VERSION "HNNBNNNYNNNNNNNNNNNNNNNNNNNNNNNNNNNNNNNNNN/4/%%%/4/'%**4NNN///"

NS_ :

BS_:

BU_: BAP_Tester CGS Gateway Gateway_PAG HUD Kombi Kombi_LB Kombi_PAG Waehlhebel_SB

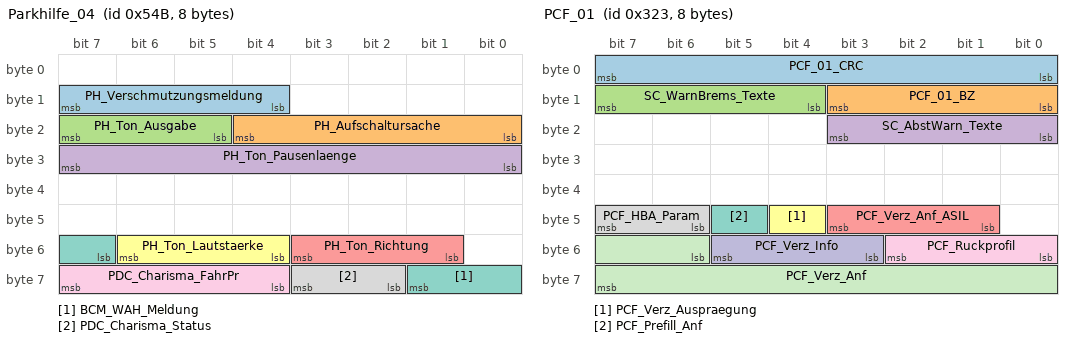
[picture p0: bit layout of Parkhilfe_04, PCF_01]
BO_ 1355 Parkhilfe_04: 8 Gateway
 SG_ PH_Verschmutzungsmeldung : 12|4@1+ (1.0,0.0) [0.0|15] ""  Kombi,Kombi_LB,Kombi_PAG
 SG_ PH_Aufschaltursache : 16|5@1+ (1.0,0.0) [0.0|31] ""  Vector__XXX
 SG_ PH_Ton_Ausgabe : 21|3@1+ (1.0,0.0) [0.0|7] ""  Vector__XXX
 SG_ PH_Ton_Pausenlaenge : 24|8@1+ (1.0,0.0) [0.0|255] ""  Vector__XXX
 SG_ PH_Ton_Richtung : 49|3@1+ (1.0,0.0) [0.0|7] ""  Vector__XXX
 SG_ PH_Ton_Lautstaerke : 52|3@1+ (1.0,0.0) [0.0|7] ""  Vector__XXX
 SG_ BCM_WAH_Meldung : 55|3@1+ (1.0,0.0) [0.0|7] ""  Kombi
 SG_ PDC_Charisma_Status : 58|2@1+ (1.0,0.0) [0.0|3] ""  Vector__XXX
 SG_ PDC_Charisma_FahrPr : 60|4@1+ (1.0,0.0) [0.0|15] ""  Vector__XXX

BO_ 803 PCF_01: 8 Gateway
 SG_ PCF_01_CRC : 0|8@1+ (1,0) [0|255] ""  Vector__XXX
 SG_ PCF_01_BZ : 8|4@1+ (1,0) [0|15] ""  Vector__XXX
 SG_ SC_WarnBrems_Texte : 12|4@1+ (1.0,0.0) [0.0|15] ""  Kombi,Kombi_LB,Kombi_PAG
 SG_ SC_AbstWarn_Texte : 16|4@1+ (1.0,0.0) [0.0|15] ""  Kombi,Kombi_LB,Kombi_PAG
 SG_ PCF_Verz_Anf_ASIL : 41|3@1+ (1.0,0.0) [0.0|7] ""  Vector__XXX
 SG_ PCF_Verz_Auspraegung : 44|1@1+ (1.0,0.0) [0.0|1] ""  Vector__XXX
 SG_ PCF_Prefill_Anf : 45|1@1+ (1.0,0.0) [0.0|1] ""  Vector__XXX
 SG_ PCF_HBA_Param : 46|2@1+ (1.0,0.0) [0.0|3] ""  Vector__XXX
 SG_ PCF_Ruckprofil : 48|3@1+ (1.0,0.0) [0.0|7] ""  Vector__XXX
 SG_ PCF_Verz_Info : 51|3@1+ (1.0,0.0) [0.0|7] ""  Vector__XXX
 SG_ PCF_Verz_Anf : 54|10@1+ (0.024,-20.016) [-20.016|4.536] "Unit_MeterPerSeconSquar"  Vector__XXX

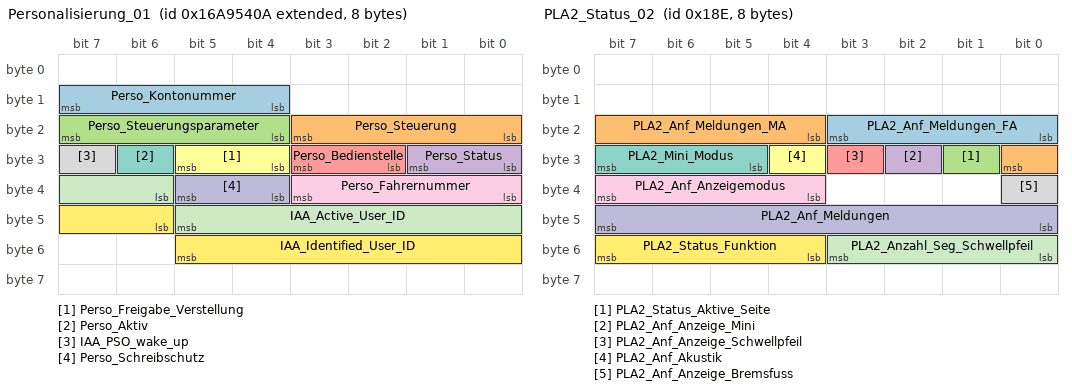
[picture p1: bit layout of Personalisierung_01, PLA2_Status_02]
BO_ 2527679498 Personalisierung_01: 8 Gateway
 SG_ Perso_Kontonummer : 12|4@1+ (1.0,0.0) [0.0|15] ""  HUD,Kombi,Kombi_LB,Kombi_PAG
 SG_ Perso_Steuerung : 16|4@1+ (1.0,0.0) [0.0|15] ""  HUD,Kombi,Kombi_LB,Kombi_PAG
 SG_ Perso_Steuerungsparameter : 20|4@1+ (1.0,0.0) [0.0|15] ""  HUD,Kombi,Kombi_LB,Kombi_PAG
 SG_ Perso_Status : 24|2@1+ (1.0,0.0) [0.0|3] ""  HUD,Kombi,Kombi_LB,Kombi_PAG
 SG_ Perso_Bedienstelle : 26|2@1+ (1.0,0.0) [0.0|3] ""  Vector__XXX
 SG_ Perso_Freigabe_Verstellung : 28|2@1+ (1.0,0.0) [0.0|3] ""  Vector__XXX
 SG_ Perso_Aktiv : 30|1@1+ (1.0,0.0) [0.0|1] ""  Vector__XXX
 SG_ IAA_PSO_wake_up : 31|1@1+ (1.0,0.0) [0.0|1] ""  Vector__XXX
 SG_ Perso_Fahrernummer : 32|4@1+ (1.0,0.0) [0.0|15] ""  Vector__XXX
 SG_ Perso_Schreibschutz : 36|2@1+ (1.0,0.0) [0.0|3] ""  Vector__XXX
 SG_ IAA_Active_User_ID : 38|8@1+ (1,0) [0|255] "Unit_None"  Kombi_PAG
 SG_ IAA_Identified_User_ID : 46|8@1+ (1,0) [0|255] "Unit_None"  Kombi_PAG

BO_ 398 PLA2_Status_02: 8 Gateway
 SG_ PLA2_Anf_Meldungen_FA : 16|4@1+ (1.0,0.0) [0.0|15] ""  Kombi,Kombi_LB,Kombi_PAG
 SG_ PLA2_Anf_Meldungen_MA : 20|5@1+ (1.0,0.0) [0.0|31] ""  Kombi,Kombi_LB,Kombi_PAG
 SG_ PLA2_Status_Aktive_Seite : 25|1@1+ (1.0,0.0) [0.0|1] ""  Kombi,Kombi_LB,Kombi_PAG
 SG_ PLA2_Anf_Anzeige_Mini : 26|1@1+ (1.0,0.0) [0.0|1] ""  Kombi,Kombi_LB,Kombi_PAG
 SG_ PLA2_Anf_Anzeige_Schwellpfeil : 27|1@1+ (1.0,0.0) [0.0|1] ""  Kombi,Kombi_LB,Kombi_PAG
 SG_ PLA2_Anf_Akustik : 28|1@1+ (1.0,0.0) [0.0|1] ""  Kombi,Kombi_LB,Kombi_PAG
 SG_ PLA2_Mini_Modus : 29|3@1+ (1.0,0.0) [0.0|7] ""  Kombi,Kombi_LB,Kombi_PAG
 SG_ PLA2_Anf_Anzeige_Bremsfuss : 32|1@1+ (1.0,0.0) [0.0|1] ""  Kombi,Kombi_LB,Kombi_PAG
 SG_ PLA2_Anf_Anzeigemodus : 36|4@1+ (1.0,0.0) [0.0|15] ""  Kombi,Kombi_LB,Kombi_PAG
 SG_ PLA2_Anf_Meldungen : 40|8@1+ (1.0,0.0) [0.0|255] ""  Kombi,Kombi_LB,Kombi_PAG
 SG_ PLA2_Anzahl_Seg_Schwellpfeil : 48|4@1+ (1,0) [0|15] ""  Kombi,Kombi_LB,Kombi_PAG
 SG_ PLA2_Status_Funktion : 52|4@1+ (1.0,0.0) [0.0|15] ""  Kombi,Kombi_LB,Kombi_PAG

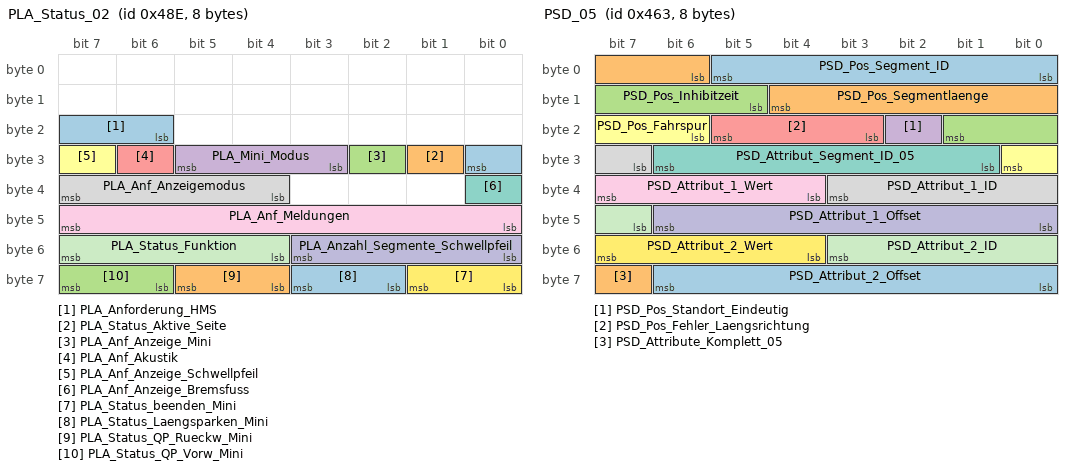
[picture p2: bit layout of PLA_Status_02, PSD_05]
BO_ 1166 PLA_Status_02: 8 Gateway
 SG_ PLA_Anforderung_HMS : 22|3@1+ (1.0,0.0) [0.0|7] ""  Vector__XXX
 SG_ PLA_Status_Aktive_Seite : 25|1@1+ (1.0,0.0) [0.0|1] ""  Kombi,Kombi_LB,Kombi_PAG
 SG_ PLA_Anf_Anzeige_Mini : 26|1@1+ (1.0,0.0) [0.0|1] ""  Kombi,Kombi_LB,Kombi_PAG
 SG_ PLA_Mini_Modus : 27|3@1+ (1.0,0.0) [0.0|7] ""  Kombi,Kombi_LB,Kombi_PAG
 SG_ PLA_Anf_Akustik : 30|1@1+ (1.0,0.0) [0.0|1] ""  Kombi,Kombi_LB,Kombi_PAG
 SG_ PLA_Anf_Anzeige_Schwellpfeil : 31|1@1+ (1.0,0.0) [0.0|1] ""  Kombi,Kombi_LB,Kombi_PAG
 SG_ PLA_Anf_Anzeige_Bremsfuss : 32|1@1+ (1.0,0.0) [0.0|1] ""  Kombi,Kombi_LB,Kombi_PAG
 SG_ PLA_Anf_Anzeigemodus : 36|4@1+ (1.0,0.0) [0.0|15] ""  Kombi,Kombi_LB,Kombi_PAG
 SG_ PLA_Anf_Meldungen : 40|8@1+ (1.0,0.0) [0.0|255] ""  Kombi,Kombi_LB,Kombi_PAG
 SG_ PLA_Anzahl_Segmente_Schwellpfeil : 48|4@1+ (1,0) [0|15] "Unit_None"  Kombi,Kombi_LB,Kombi_PAG
 SG_ PLA_Status_Funktion : 52|4@1+ (1.0,0.0) [0.0|15] ""  Kombi,Kombi_LB,Kombi_PAG
 SG_ PLA_Status_beenden_Mini : 56|2@1+ (1.0,0.0) [0.0|3] ""  Vector__XXX
 SG_ PLA_Status_Laengsparken_Mini : 58|2@1+ (1.0,0.0) [0.0|3] ""  Vector__XXX
 SG_ PLA_Status_QP_Rueckw_Mini : 60|2@1+ (1.0,0.0) [0.0|3] ""  Vector__XXX
 SG_ PLA_Status_QP_Vorw_Mini : 62|2@1+ (1.0,0.0) [0.0|3] ""  Vector__XXX

BO_ 319 PreCrash_02: 8 Gateway
 SG_ PreCrash_02_CRC : 0|8@1+ (1,0) [0|255] ""  Vector__XXX
 SG_ PreCrash_02_BZ : 8|4@1+ (1,0) [0|15] ""  Vector__XXX
 SG_ PreCrash_Charisma_FahrPr : 12|4@1+ (1.0,0.0) [0.0|15] ""  Vector__XXX
 SG_ PreCrash_Charisma_Status : 16|2@1+ (1.0,0.0) [0.0|3] ""  Vector__XXX
 SG_ PreCrash_Schiebedach_schliessen : 18|1@1+ (1.0,0.0) [0.0|1] ""  Vector__XXX
 SG_ PreCrash_Fenster_schliessen : 19|1@1+ (1.0,0.0) [0.0|1] ""  Vector__XXX
 SG_ PreCrash_Blinken : 20|3@1+ (1.0,0.0) [0.0|7] ""  Vector__XXX
 SG_ SC_PreSense_FCWP : 23|1@1+ (1.0,0.0) [0.0|1] ""  Vector__XXX
 SG_ PreCrash_Tueren_Verriegeln : 24|1@1+ (1.0,0.0) [0.0|1] ""  Vector__XXX
 SG_ PreCrash_Anforderung_AFR : 26|3@1+ (1.0,0.0) [0.0|7] ""  Vector__XXX
 SG_ SC_PreCrash_LED : 29|2@1+ (1.0,0.0) [0.0|3] ""  HUD,Kombi,Kombi_LB,Kombi_PAG
 SG_ PreCrash_FS_Pneumatik_ansteuern : 31|1@1+ (1.0,0.0) [0.0|1] ""  Vector__XXX
 SG_ PreCrash_BFS_Pneumatik_ansteuern : 32|1@1+ (1.0,0.0) [0.0|1] ""  Vector__XXX
 SG_ PreCrash_Fo_Pneumatik_ansteuern : 33|1@1+ (1.0,0.0) [0.0|1] ""  Vector__XXX
 SG_ PreCrash_FS_Sitzlehne_verfahren : 34|3@1+ (1.0,0.0) [0.0|7] ""  Vector__XXX
 SG_ PreCrash_BFS_Sitzlehne_verfahren : 37|3@1+ (1.0,0.0) [0.0|7] ""  Vector__XXX
 SG_ PreCrash_Fo_Sitzlehne_verfahren : 40|3@1+ (1.0,0.0) [0.0|7] ""  Vector__XXX
 SG_ PreCrash_FS_KSV_verfahren : 43|4@1+ (1.0,0.0) [0.0|15] ""  Vector__XXX
 SG_ PreCrash_BFS_KSV_verfahren : 47|4@1+ (1.0,0.0) [0.0|15] ""  Vector__XXX
 SG_ PreCrash_Fo_KSV_verfahren : 51|4@1+ (1.0,0.0) [0.0|15] ""  Vector__XXX
 SG_ SC_PreCrash_Warnung : 56|4@1+ (1.0,0.0) [0.0|15] ""  HUD,Kombi,Kombi_LB,Kombi_PAG
 SG_ SC_PreCrash_Texte : 60|4@1+ (1.0,0.0) [0.0|15] ""  Kombi,Kombi_LB,Kombi_PAG

BO_ 1122 PSD_04: 8 Gateway
 SG_ PSD_Segment_ID : 0|6@1+ (1,0) [2|63] ""  Kombi,Kombi_LB,Kombi_PAG
 SG_ PSD_Vorgaenger_Segment_ID : 6|6@1+ (1,0) [2|63] ""  Kombi,Kombi_LB,Kombi_PAG
 SG_ PSD_Segmentlaenge : 12|7@1+ (2,0) [0|254] "Unit_Meter"  Kombi,Kombi_LB,Kombi_PAG
 SG_ PSD_Strassenkategorie : 19|3@1+ (1.0,0.0) [0.0|7] ""  Kombi,Kombi_LB,Kombi_PAG
 SG_ PSD_Endkruemmung : 22|8@1+ (1,0) [0|254] "Unit_None"  Kombi,Kombi_LB,Kombi_PAG
 SG_ PSD_Endkruemmung_Vorz : 30|1@1+ (1.0,0.0) [0.0|1] ""  Kombi,Kombi_LB,Kombi_PAG
 SG_ PSD_Idenditaets_ID : 31|6@1+ (1,0) [2|63] ""  Kombi,Kombi_LB,Kombi_PAG
 SG_ PSD_ADAS_Qualitaet : 37|1@1+ (1.0,0.0) [0.0|1] ""  Kombi,Kombi_LB,Kombi_PAG
 SG_ PSD_wahrscheinlichster_Pfad : 38|1@1+ (1.0,0.0) [0.0|1] ""  Kombi,Kombi_LB,Kombi_PAG
 SG_ PSD_Geradester_Pfad : 39|1@1+ (1.0,0.0) [0.0|1] ""  Kombi,Kombi_LB,Kombi_PAG
 SG_ PSD_Fahrspuren_Anzahl : 40|3@1+ (1.0,0.0) [0.0|7] ""  Kombi,Kombi_LB,Kombi_PAG
 SG_ PSD_Bebauung : 43|1@1+ (1.0,0.0) [0.0|1] ""  Kombi,Kombi_LB,Kombi_PAG
 SG_ PSD_Segment_Komplett : 44|1@1+ (1.0,0.0) [0.0|1] ""  Kombi,Kombi_LB,Kombi_PAG
 SG_ PSD_Rampe : 45|2@1+ (1.0,0.0) [0.0|3] ""  Kombi,Kombi_LB,Kombi_PAG
 SG_ PSD_Anfangskruemmung : 47|8@1+ (1,0) [0|254] ""  Kombi,Kombi_LB,Kombi_PAG
 SG_ PSD_Anfangskruemmung_Vorz : 55|1@1+ (1.0,0.0) [0.0|1] ""  Kombi,Kombi_LB,Kombi_PAG
 SG_ PSD_Abzweigerichtung : 56|1@1+ (1.0,0.0) [0.0|1] ""  Kombi,Kombi_LB,Kombi_PAG
 SG_ PSD_Abzweigewinkel : 57|7@1+ (1.417323,0) [0.000000|180.000021] ""  Kombi,Kombi_LB,Kombi_PAG

BO_ 1123 PSD_05: 8 Gateway
 SG_ PSD_Pos_Segment_ID : 0|6@1+ (1,0) [2|63] ""  Kombi,Kombi_LB,Kombi_PAG
 SG_ PSD_Pos_Segmentlaenge : 6|7@1+ (2,0) [0|254] "Unit_Meter"  Kombi,Kombi_LB,Kombi_PAG
 SG_ PSD_Pos_Inhibitzeit : 13|5@1+ (10,0) [0|310] "Unit_MilliSecon"  Kombi,Kombi_LB,Kombi_PAG
 SG_ PSD_Pos_Standort_Eindeutig : 18|1@1+ (1.0,0.0) [0.0|1] ""  Kombi,Kombi_LB,Kombi_PAG
 SG_ PSD_Pos_Fehler_Laengsrichtung : 19|3@1+ (1.0,0.0) [0.0|7] ""  Kombi,Kombi_LB,Kombi_PAG
 SG_ PSD_Pos_Fahrspur : 22|3@1+ (1.0,0.0) [0.0|7] ""  Kombi,Kombi_LB,Kombi_PAG
 SG_ PSD_Attribut_Segment_ID_05 : 25|6@1+ (1,0) [2|63] ""  Kombi,Kombi_LB,Kombi_PAG
 SG_ PSD_Attribut_1_ID : 31|5@1+ (1,0) [1|31] ""  Kombi,Kombi_LB,Kombi_PAG
 SG_ PSD_Attribut_1_Wert : 36|4@1+ (1.0,0.0) [0.0|15] ""  Kombi,Kombi_LB,Kombi_PAG
 SG_ PSD_Attribut_1_Offset : 40|7@1+ (2,0) [0|254] "Unit_Meter"  Kombi,Kombi_LB,Kombi_PAG
 SG_ PSD_Attribut_2_ID : 47|5@1+ (1,0) [1|31] ""  Kombi,Kombi_LB,Kombi_PAG
 SG_ PSD_Attribut_2_Wert : 52|4@1+ (1.0,0.0) [0.0|15] ""  Kombi,Kombi_LB,Kombi_PAG
 SG_ PSD_Attribut_2_Offset : 56|7@1+ (2,0) [0|254] "Unit_Meter"  Kombi,Kombi_LB,Kombi_PAG
 SG_ PSD_Attribute_Komplett_05 : 63|1@1+ (1.0,0.0) [0.0|1] ""  Kombi,Kombi_LB,Kombi_PAG

BO_ 1124 PSD_06: 8 Gateway
 SG_ PSD_06_Mux M  : 0|3@1+ (1.0,0.0) [0.0|7] ""  HUD,Kombi,Kombi_LB,Kombi_PAG
 SG_ PSD_Sys_Segment_ID m0  : 3|6@1+ (1,0) [2|63] ""  HUD,Kombi,Kombi_LB,Kombi_PAG
 SG_ PSD_Attribut_Segment_ID m1  : 3|6@1+ (1,0) [2|63] ""  Kombi,Kombi_LB,Kombi_PAG
 SG_ PSD_Ges_Segment_ID m2  : 3|6@1+ (1,0) [2|63] ""  Kombi,Kombi_LB,Kombi_PAG
 SG_ PSD_Baum_Laenge_VZ m3  : 3|1@1+ (1.0,0.0) [0.0|1] ""  Kombi,Kombi_LB,Kombi_PAG
 SG_ PSD_Steigung_1_Segment_ID m4  : 3|6@1+ (1,0) [2|63] ""  Kombi,Kombi_LB,Kombi_PAG
 SG_ PSD_Baum_Laenge m3  : 4|25@1+ (0.00001,0) [0.00000|180.00000] "Unit_DegreOfArc"  Kombi,Kombi_LB,Kombi_PAG
 SG_ PSD_Sys_Laendercode m0  : 9|8@1+ (1.0,0.0) [0.0|255] ""  HUD,Kombi,Kombi_LB,Kombi_PAG
 SG_ PSD_Attribut_3_ID m1  : 9|5@1+ (1,0) [1|31] ""  Kombi,Kombi_LB,Kombi_PAG
 SG_ PSD_Ges_Offset m2  : 9|7@1+ (2,0) [0|254] "Unit_Meter"  Kombi,Kombi_LB,Kombi_PAG
 SG_ PSD_Steigung_1_A_Steigung m4  : 9|7@1+ (0.12,0) [0.00|15.00] "Unit_PerCent"  Kombi,Kombi_LB,Kombi_PAG
 SG_ PSD_Attribut_3_Offset m1  : 14|7@1+ (2,0) [0|254] "Unit_Meter"  Kombi,Kombi_LB,Kombi_PAG
 SG_ PSD_Ges_Geschwindigkeit m2  : 16|5@1+ (1.0,0.0) [0.0|31] ""  Kombi,Kombi_LB,Kombi_PAG
 SG_ PSD_Steigung_1_A_Vorz m4  : 16|1@1+ (1.0,0.0) [0.0|1] ""  Kombi,Kombi_LB,Kombi_PAG
 SG_ PSD_Sys_Geschwindigkeit_Einheit m0  : 17|1@1+ (1.0,0.0) [0.0|1] ""  HUD,Kombi,Kombi_LB,Kombi_PAG
 SG_ PSD_Steigung_1_A_Offset m4  : 17|7@1+ (2,0) [0|254] "Unit_Meter"  Kombi,Kombi_LB,Kombi_PAG
 SG_ PSD_Sys_Verkehrsrichtung m0  : 18|1@1+ (1.0,0.0) [0.0|1] ""  HUD,Kombi,Kombi_LB,Kombi_PAG
 SG_ PSD_Sys_Geometrieguete m0  : 19|2@1+ (1.0,0.0) [0.0|3] ""  HUD,Kombi,Kombi_LB,Kombi_PAG
 SG_ PSD_Sys_Mapmatchingguete m0  : 21|2@1+ (1.0,0.0) [0.0|3] ""  HUD,Kombi,Kombi_LB,Kombi_PAG
 SG_ PSD_Attribut_3_Wert m1  : 21|4@1+ (1.0,0.0) [0.0|15] ""  Kombi,Kombi_LB,Kombi_PAG
 SG_ PSD_Ges_Typ m2  : 21|2@1+ (1.0,0.0) [0.0|3] ""  Kombi,Kombi_LB,Kombi_PAG
 SG_ PSD_Sys_Alter_Karte m0  : 23|3@1+ (1.0,0.0) [0.0|7] ""  HUD,Kombi,Kombi_LB,Kombi_PAG
 SG_ PSD_Ges_Spur_Geschw_Begrenzung m2  : 23|6@1+ (1.0,0.0) [0.0|63] ""  Kombi,Kombi_LB,Kombi_PAG
 SG_ PSD_Steigung_1_B_Steigung m4  : 24|7@1+ (0.12,0) [0.00|15.00] "Unit_PerCent"  Kombi,Kombi_LB,Kombi_PAG
 SG_ PSD_Attribut_4_ID m1  : 25|5@1+ (1,0) [1|31] ""  Kombi,Kombi_LB,Kombi_PAG
 SG_ PSD_Sys_Zielfuehrung m0  : 26|1@1+ (1.0,0.0) [0.0|1] ""  HUD,Kombi,Kombi_LB,Kombi_PAG
 SG_ PSD_Sys_US_State m0  : 27|6@1+ (1.0,0.0) [0.0|63] ""  HUD,Kombi,Kombi_LB,Kombi_PAG
 SG_ PSD_Ges_Geschwindigkeit_Gespann m2  : 29|2@1+ (1.0,0.0) [0.0|3] ""  Kombi,Kombi_LB,Kombi_PAG
 SG_ PSD_Baum_Breite_VZ m3  : 29|1@1+ (1.0,0.0) [0.0|1] ""  Kombi,Kombi_LB,Kombi_PAG
 SG_ PSD_Attribut_4_Wert m1  : 30|4@1+ (1,0) [0|15] ""  Kombi,Kombi_LB,Kombi_PAG
 SG_ PSD_Baum_Breite m3  : 30|24@1+ (0.00001,0) [0.00000|90.00000] "Unit_DegreOfArc"  Kombi,Kombi_LB,Kombi_PAG
 SG_ PSD_Ges_Geschwindigkeit_Witter m2  : 31|2@1+ (1.0,0.0) [0.0|3] ""  Kombi,Kombi_LB,Kombi_PAG
 SG_ PSD_Steigung_1_B_Vorz m4  : 31|1@1+ (1.0,0.0) [0.0|1] ""  Kombi,Kombi_LB,Kombi_PAG
 SG_ PSD_Steigung_1_B_Offset m4  : 32|7@1+ (2,0) [0|254] "Unit_Meter"  Kombi,Kombi_LB,Kombi_PAG
 SG_ PSD_Sys_Quali_Geometrien m0  : 33|3@1+ (1,0) [0|7] "Unit_None"  HUD
 SG_ PSD_Ges_Geschwindigkeit_Tag_Anf m2  : 33|3@1+ (1.0,0.0) [0.0|7] ""  Kombi,Kombi_LB,Kombi_PAG
 SG_ PSD_Attribut_4_Offset m1  : 34|7@1+ (2,0) [0|254] "Unit_Meter"  Kombi,Kombi_LB,Kombi_PAG
 SG_ PSD_Sys_Quali_Ortsinfo m0  : 36|2@1+ (1,0) [0|3] "Unit_None"  HUD
 SG_ PSD_Ges_Geschwindigkeit_Tag_Ende m2  : 36|3@1+ (1.0,0.0) [0.0|7] ""  Kombi,Kombi_LB,Kombi_PAG
 SG_ PSD_Sys_Quali_verfuegbar m0  : 38|1@1+ (1.0,0.0) [0.0|1] ""  HUD
 SG_ PSD_Sys_Zielfuehrung_geaendert m0  : 39|1@1+ (1.0,0.0) [0.0|1] ""  HUD
 SG_ PSD_Ges_Geschwindigkeit_Std_Anf m2  : 39|5@1+ (1,0) [0|24] "Unit_Hours"  Kombi,Kombi_LB,Kombi_PAG
 SG_ PSD_Steigung_1_Attribute_kompl m4  : 39|1@1+ (1.0,0.0) [0.0|1] ""  Kombi,Kombi_LB,Kombi_PAG
 SG_ PSD_Sys_Geometrieguete_erweitert m0  : 40|8@1+ (1.0,0.0) [0.0|255] ""  HUD
 SG_ PSD_Steigung_2_Segment_ID m4  : 40|6@1+ (1,0) [2|63] ""  Kombi,Kombi_LB,Kombi_PAG
 SG_ PSD_Attribut_5_ID m1  : 41|5@1+ (1,0) [1|31] ""  Kombi,Kombi_LB,Kombi_PAG
 SG_ PSD_Ges_Geschwindigkeit_Std_Ende m2  : 44|5@1+ (1,0) [0|24] "Unit_Hours"  Kombi,Kombi_LB,Kombi_PAG
 SG_ PSD_Attribut_5_Offset m1  : 46|7@1+ (2,0) [0|254] "Unit_Meter"  Kombi,Kombi_LB,Kombi_PAG
 SG_ PSD_Steigung_2_Steigung m4  : 46|7@1+ (0.12,0) [0.00|15.00] "Unit_PerCent"  Kombi,Kombi_LB,Kombi_PAG
 SG_ PSD_Sys_Quali_sonstige_Attribute m0  : 48|3@1+ (1,0) [0|7] "Unit_None"  HUD
 SG_ PSD_Ges_Ueberholverbot m2  : 49|2@1+ (1.0,0.0) [0.0|3] ""  Kombi,Kombi_LB,Kombi_PAG
 SG_ PSD_Sys_Quali_Steigungen m0  : 51|3@1+ (1,0) [0|7] ""  HUD
 SG_ PSD_Ges_Wechselverkehrszeichen m2  : 51|3@1+ (1.0,0.0) [0.0|7] ""  Kombi,Kombi_LB,Kombi_PAG
 SG_ PSD_Attribut_5_Wert m1  : 53|4@1+ (1,0) [0|15] ""  Kombi,Kombi_LB,Kombi_PAG
 SG_ PSD_Steigung_2_Vorz m4  : 53|1@1+ (1.0,0.0) [0.0|1] ""  Kombi,Kombi_LB,Kombi_PAG
 SG_ PSD_Sys_Quali_Strassenkennz m0  : 54|3@1+ (1,0) [0|7] "Unit_None"  HUD
 SG_ PSD_Wechselverkehrszeichen_Typ m2  : 54|2@1+ (1.0,0.0) [0.0|3] ""  Kombi,Kombi_LB,Kombi_PAG
 SG_ PSD_Baum_Ausrichtung m3  : 54|10@1+ (0.3515625,0) [0E-7|359.6484375] "Unit_DegreOfArc"  Kombi,Kombi_LB,Kombi_PAG
 SG_ PSD_Steigung_2_Offset m4  : 54|7@1+ (2,0) [0|254] "Unit_Meter"  Kombi,Kombi_LB,Kombi_PAG
 SG_ PSD_Ges_Gesetzlich_Kategorie m2  : 56|3@1+ (1.0,0.0) [0.0|7] ""  Kombi,Kombi_LB,Kombi_PAG
 SG_ PSD_Sys_Quali_Tempolimits m0  : 57|3@1+ (1,0) [0|7] "Unit_None"  HUD
 SG_ PSD_Attribute_Komplett_06 m1  : 57|1@1+ (1.0,0.0) [0.0|1] ""  Kombi,Kombi_LB,Kombi_PAG
 SG_ PSD_Ges_Gesetzlich_Zusatz m2  : 59|2@1+ (1.0,0.0) [0.0|3] ""  Kombi,Kombi_LB,Kombi_PAG
 SG_ PSD_Sys_Quali_Vorfahrtsregelung m0  : 60|3@1+ (1,0) [0|7] "Unit_None"  HUD
 SG_ PSD_Ges_Verkehrszeichen_Quelle m2  : 61|2@1+ (1.0,0.0) [0.0|3] ""  Kombi,Kombi_LB,Kombi_PAG
 SG_ PSD_Steigung_2_Attribute_kompl m4  : 61|1@1+ (1.0,0.0) [0.0|1] ""  Kombi,Kombi_LB,Kombi_PAG
 SG_ PSD_Ges_Attribute_Komplett m2  : 63|1@1+ (1.0,0.0) [0.0|1] ""  Kombi,Kombi_LB,Kombi_PAG

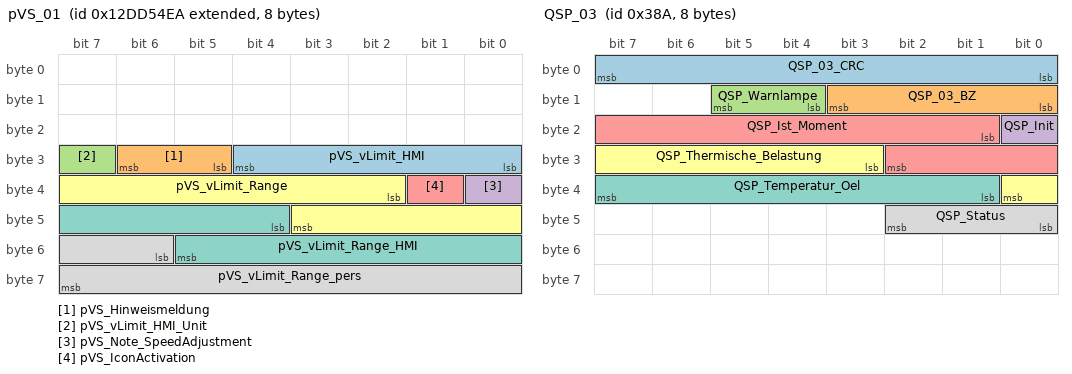
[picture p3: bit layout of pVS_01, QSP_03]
BO_ 2463978730 pVS_01: 8 Gateway_PAG
 SG_ pVS_vLimit_HMI : 24|5@1+ (5,35) [35|180] ""  HUD,Kombi_PAG
 SG_ pVS_Hinweismeldung : 29|2@1+ (1.0,0.0) [0.0|3] ""  HUD,Kombi_PAG
 SG_ pVS_vLimit_HMI_Unit : 31|1@1+ (1.0,0.0) [0.0|1] ""  HUD,Kombi_PAG
 SG_ pVS_Note_SpeedAdjustment : 32|1@1+ (1.0,0.0) [0.0|1] ""  Kombi_PAG
 SG_ pVS_IconActivation : 33|1@1+ (1.0,0.0) [0.0|1] ""  HUD,Kombi_PAG
 SG_ pVS_vLimit_Range : 34|10@1+ (0.32,0) [0.00|326.40] "Unit_KiloMeterPerHour"  Vector__XXX
 SG_ pVS_vLimit_Range_HMI : 44|10@1+ (0.32,0) [0.00|326.40] "Unit_KiloMeterPerHour"  Vector__XXX
 SG_ pVS_vLimit_Range_pers : 54|10@1+ (0.32,0) [0.00|326.40] "Unit_KiloMeterPerHour"  Vector__XXX

BO_ 906 QSP_03: 8 Gateway
 SG_ QSP_03_CRC : 0|8@1+ (1,0) [0|255] ""  Vector__XXX
 SG_ QSP_03_BZ : 8|4@1+ (1,0) [0|15] ""  Vector__XXX
 SG_ QSP_Warnlampe : 12|2@1+ (1.0,0.0) [0.0|3] ""  Kombi,Kombi_PAG
 SG_ QSP_Init : 16|1@1+ (1.0,0.0) [0.0|1] ""  Vector__XXX
 SG_ QSP_Ist_Moment : 17|10@1+ (3,-1533) [-1533|1533] "Unit_NewtoMeter"  Vector__XXX
 SG_ QSP_Thermische_Belastung : 27|6@1+ (2,0) [0|100] "Unit_PerCent"  Vector__XXX
 SG_ QSP_Temperatur_Oel : 33|7@1+ (2,-40) [-40|210] "Unit_DegreCelsi"  Vector__XXX
 SG_ QSP_Status : 40|3@1+ (1.0,0.0) [0.0|7] ""  Vector__XXX

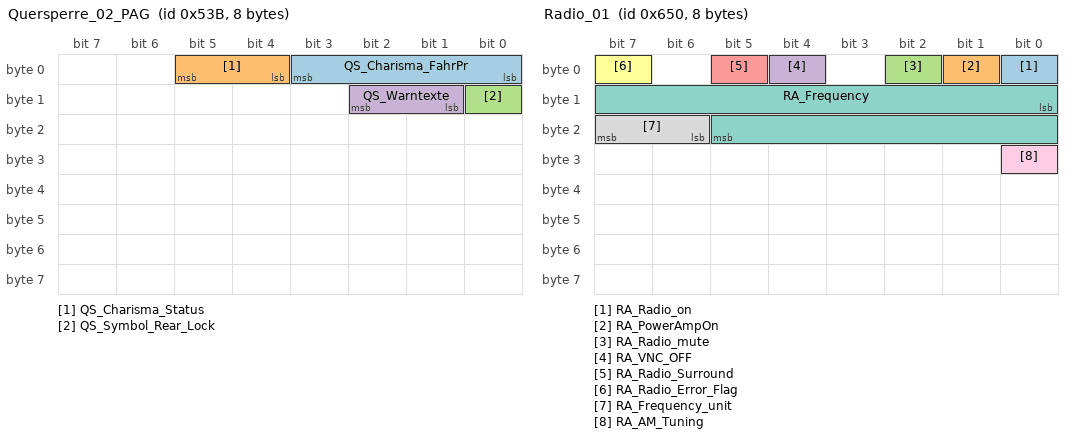
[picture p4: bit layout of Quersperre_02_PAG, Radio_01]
BO_ 1339 Quersperre_02_PAG: 8 Gateway
 SG_ QS_Charisma_FahrPr : 0|4@1+ (1.0,0.0) [0.0|15] ""  Vector__XXX
 SG_ QS_Charisma_Status : 4|2@1+ (1.0,0.0) [0.0|3] ""  Vector__XXX
 SG_ QS_Symbol_Rear_Lock : 8|1@1+ (1.0,0.0) [0.0|1] ""  Vector__XXX
 SG_ QS_Warntexte : 9|2@1+ (1.0,0.0) [0.0|3] ""  Kombi,Kombi_PAG

BO_ 1616 Radio_01: 8 Gateway
 SG_ RA_Radio_on : 0|1@1+ (1,0) [0|1] ""  Vector__XXX
 SG_ RA_PowerAmpOn : 1|1@1+ (1,0) [0|1] ""  Vector__XXX
 SG_ RA_Radio_mute : 2|1@1+ (1,0) [0|1] ""  Vector__XXX
 SG_ RA_VNC_OFF : 4|1@1+ (1,0) [0|1] ""  Vector__XXX
 SG_ RA_Radio_Surround : 5|1@1+ (1,0) [0|1] ""  Vector__XXX
 SG_ RA_Radio_Error_Flag : 7|1@1+ (1.0,0.0) [0.0|1] ""  Vector__XXX
 SG_ RA_Frequency : 8|14@1+ (1,0) [0|16383] "Unit_None"  Kombi
 SG_ RA_Frequency_unit : 22|2@1+ (1.0,0.0) [0.0|3] ""  Kombi,Kombi_LB
 SG_ RA_AM_Tuning : 24|1@1+ (1.0,0.0) [0.0|1] ""  Kombi,Kombi_LB

BO_ 1529 RDK_02: 8 Gateway
 SG_ RDK_FMVSS138_Lampe : 12|1@1+ (1.0,0.0) [0.0|1] ""  Kombi,Kombi_LB,Kombi_PAG
 SG_ RDK_FMVSS138_MIL : 13|1@1+ (1.0,0.0) [0.0|1] ""  Kombi,Kombi_LB,Kombi_PAG
 SG_ RDK_Kalibrierung : 14|1@1+ (1.0,0.0) [0.0|1] ""  Vector__XXX
 SG_ RDK_Reifendruck_Lampe : 15|1@1+ (1.0,0.0) [0.0|1] ""  Kombi,Kombi_LB
 SG_ RDK_Warnungen_02 : 16|5@1+ (1.0,0.0) [0.0|31] ""  Kombi,Kombi_LB,Kombi_PAG
 SG_ RDK_angelernt : 22|1@1+ (1.0,0.0) [0.0|1] ""  Kombi_PAG
 SG_ RDK_Reifentemperatur_Lampe : 23|1@1+ (1.0,0.0) [0.0|1] ""  Kombi,Kombi_LB
 SG_ RDK_RS_aktiv : 24|1@1+ (1.0,0.0) [0.0|1] ""  Kombi_PAG
 SG_ RDK_Text_7 : 25|1@1+ (1.0,0.0) [0.0|1] ""  Kombi_PAG
 SG_ RDK_W_1_Reifen_HL : 56|1@1+ (1.0,0.0) [0.0|1] ""  Kombi,Kombi_LB,Kombi_PAG
 SG_ RDK_W_1_Reifen_HR : 57|1@1+ (1.0,0.0) [0.0|1] ""  Kombi,Kombi_LB,Kombi_PAG
 SG_ RDK_W_1_Reifen_VL : 58|1@1+ (1.0,0.0) [0.0|1] ""  Kombi,Kombi_LB,Kombi_PAG
 SG_ RDK_W_1_Reifen_VR : 59|1@1+ (1.0,0.0) [0.0|1] ""  Kombi,Kombi_LB,Kombi_PAG
 SG_ RDK_W_2_Reifen_HL : 60|1@1+ (1.0,0.0) [0.0|1] ""  Kombi,Kombi_LB,Kombi_PAG
 SG_ RDK_W_2_Reifen_HR : 61|1@1+ (1.0,0.0) [0.0|1] ""  Kombi,Kombi_LB,Kombi_PAG
 SG_ RDK_W_2_Reifen_VL : 62|1@1+ (1.0,0.0) [0.0|1] ""  Kombi,Kombi_LB,Kombi_PAG
 SG_ RDK_W_2_Reifen_VR : 63|1@1+ (1.0,0.0) [0.0|1] ""  Kombi,Kombi_LB,Kombi_PAG

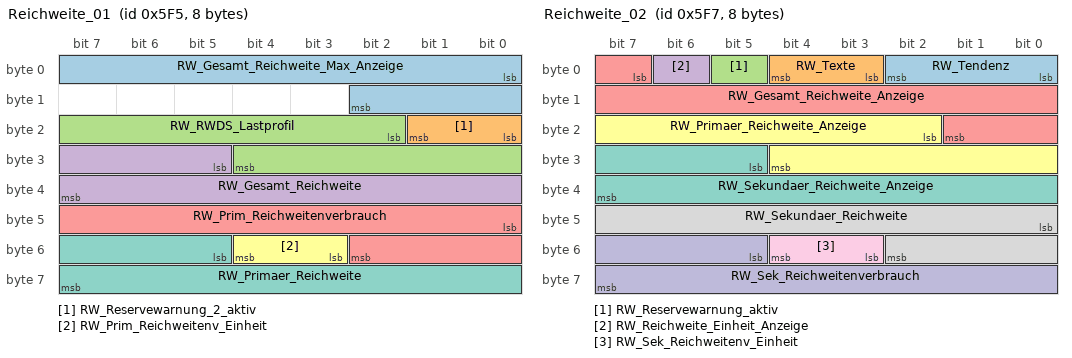
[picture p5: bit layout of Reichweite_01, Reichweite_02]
BO_ 1525 Reichweite_01: 8 Gateway
 SG_ RW_Gesamt_Reichweite_Max_Anzeige : 0|11@1+ (1,0) [0|2044] "Unit_None"  Kombi,Kombi_LB,Kombi_PAG
 SG_ RW_Reservewarnung_2_aktiv : 16|2@1+ (1.0,0.0) [0.0|3] ""  HUD,Kombi,Kombi_LB
 SG_ RW_RWDS_Lastprofil : 18|11@1+ (1,0) [0|2045] "Unit_Amper"  Vector__XXX
 SG_ RW_Gesamt_Reichweite : 29|11@1+ (1,0) [0|2044] "Unit_KiloMeter"  Kombi,Kombi_LB,Kombi_PAG
 SG_ RW_Prim_Reichweitenverbrauch : 40|11@1+ (0.1,0) [0.0|204.4] "Unit_None"  Kombi,Kombi_LB,Kombi_PAG
 SG_ RW_Prim_Reichweitenv_Einheit : 51|2@1+ (1.0,0.0) [0.0|3] ""  Kombi,Kombi_LB,Kombi_PAG
 SG_ RW_Primaer_Reichweite : 53|11@1+ (1,0) [0|2044] "Unit_KiloMeter"  Kombi,Kombi_LB,Kombi_PAG

BO_ 1527 Reichweite_02: 8 Gateway
 SG_ RW_Tendenz : 0|3@1+ (1.0,0.0) [0.0|7] ""  Kombi_PAG
 SG_ RW_Texte : 3|2@1+ (1.0,0.0) [0.0|3] ""  Kombi,Kombi_LB,Kombi_PAG
 SG_ RW_Reservewarnung_aktiv : 5|1@1+ (1.0,0.0) [0.0|1] ""  HUD,Kombi,Kombi_LB
 SG_ RW_Reichweite_Einheit_Anzeige : 6|1@1+ (1.0,0.0) [0.0|1] ""  Kombi,Kombi_LB,Kombi_PAG
 SG_ RW_Gesamt_Reichweite_Anzeige : 7|11@1+ (1,0) [0|2044] "Unit_None"  Kombi,Kombi_LB,Kombi_PAG
 SG_ RW_Primaer_Reichweite_Anzeige : 18|11@1+ (1,0) [0|2044] "Unit_None"  HUD,Kombi,Kombi_LB,Kombi_PAG
 SG_ RW_Sekundaer_Reichweite_Anzeige : 29|11@1+ (1,0) [0|2044] "Unit_None"  Kombi,Kombi_LB,Kombi_PAG
 SG_ RW_Sekundaer_Reichweite : 40|11@1+ (1,0) [0|2044] "Unit_KiloMeter"  Kombi,Kombi_LB,Kombi_PAG
 SG_ RW_Sek_Reichweitenv_Einheit : 51|2@1+ (1.0,0.0) [0.0|3] ""  Kombi,Kombi_LB,Kombi_PAG
 SG_ RW_Sek_Reichweitenverbrauch : 53|11@1+ (0.1,0) [0.0|204.4] "Unit_None"  Kombi,Kombi_LB,Kombi_PAG

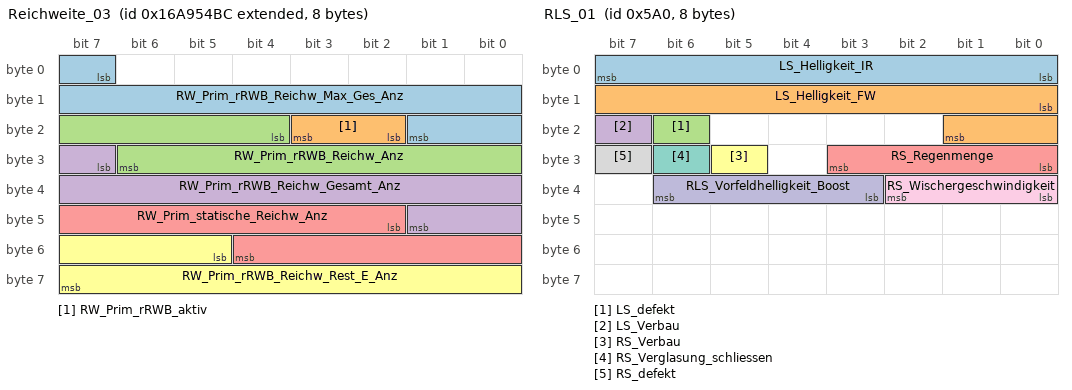
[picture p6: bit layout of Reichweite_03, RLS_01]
BO_ 2527679676 Reichweite_03: 8 Gateway
 SG_ RW_Prim_rRWB_Reichw_Max_Ges_Anz : 7|11@1+ (1,0) [0|2044] ""  Kombi,Kombi_LB,Kombi_PAG
 SG_ RW_Prim_rRWB_aktiv : 18|2@1+ (1.0,0.0) [0.0|3] ""  HUD,Kombi,Kombi_LB,Kombi_PAG
 SG_ RW_Prim_rRWB_Reichw_Anz : 20|11@1+ (1,0) [0|2044] ""  Kombi,Kombi_LB,Kombi_PAG
 SG_ RW_Prim_rRWB_Reichw_Gesamt_Anz : 31|11@1+ (1,0) [0|2044] "Unit_None"  HUD,Kombi,Kombi_LB,Kombi_PAG
 SG_ RW_Prim_statische_Reichw_Anz : 42|11@1+ (1,0) [0|2044] ""  HUD,Kombi,Kombi_LB,Kombi_PAG
 SG_ RW_Prim_rRWB_Reichw_Rest_E_Anz : 53|11@1+ (1,0) [0|2044] ""  HUD,Kombi,Kombi_LB,Kombi_PAG

BO_ 1440 RLS_01: 8 Gateway
 SG_ LS_Helligkeit_IR : 0|8@1+ (400,0) [0|101200] "Unit_Lux"  HUD
 SG_ LS_Helligkeit_FW : 8|10@1+ (6,0) [0|6126] "Unit_Lux"  HUD
 SG_ LS_defekt : 22|1@1+ (1.0,0.0) [0.0|1] ""  HUD
 SG_ LS_Verbau : 23|1@1+ (1.0,0.0) [0.0|1] ""  HUD
 SG_ RS_Regenmenge : 24|4@1+ (1.0,0.0) [0.0|15] ""  Kombi
 SG_ RS_Verbau : 29|1@1+ (1.0,0.0) [0.0|1] ""  Vector__XXX
 SG_ RS_Verglasung_schliessen : 30|1@1+ (1.0,0.0) [0.0|1] ""  Vector__XXX
 SG_ RS_defekt : 31|1@1+ (1.0,0.0) [0.0|1] ""  Kombi,Kombi_LB,Kombi_PAG
 SG_ RS_Wischergeschwindigkeit : 32|3@1+ (1.0,0.0) [0.0|7] ""  Kombi
 SG_ RLS_Vorfeldhelligkeit_Boost : 35|4@1+ (1.0,0.0) [0.0|15] ""  HUD

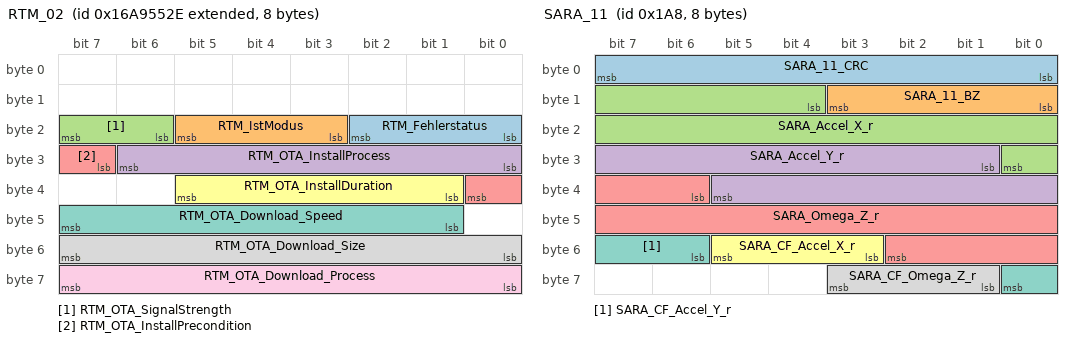
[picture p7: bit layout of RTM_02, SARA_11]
BO_ 2527679790 RTM_02: 8 Gateway
 SG_ RTM_Fehlerstatus : 16|3@1+ (1.0,0.0) [0.0|7] ""  Vector__XXX
 SG_ RTM_IstModus : 19|3@1+ (1.0,0.0) [0.0|7] ""  Kombi,Kombi_LB,Kombi_PAG
 SG_ RTM_OTA_SignalStrength : 22|2@1+ (1.0,0.0) [0.0|3] ""  Vector__XXX
 SG_ RTM_OTA_InstallProcess : 24|7@1+ (1,-1) [0|100] "Unit_PerCent"  Vector__XXX
 SG_ RTM_OTA_InstallPrecondition : 31|2@1+ (1.0,0.0) [0.0|3] ""  Vector__XXX
 SG_ RTM_OTA_InstallDuration : 33|5@1+ (1,0) [1|30] "Unit_Minut"  Vector__XXX
 SG_ RTM_OTA_Download_Speed : 41|7@1+ (0.1,0) [0.1|12.5] ""  Vector__XXX
 SG_ RTM_OTA_Download_Size : 48|8@1+ (1,1) [1|253] ""  Vector__XXX
 SG_ RTM_OTA_Download_Process : 56|8@1+ (0.5,0) [0.0|100.0] "Unit_PerCent"  Vector__XXX

BO_ 1504 SAD_01: 8 Gateway
 SG_ MD1_Position : 8|7@1+ (1,0) [0|100] "Unit_PerCent"  Kombi_PAG
 SG_ MD1_Lage : 15|1@1+ (1.0,0.0) [0.0|1] ""  Kombi_PAG
 SG_ MD3_Position : 16|7@1+ (1,0) [0|100] "Unit_PerCent"  Vector__XXX
 SG_ MD3_Lage : 23|1@1+ (1.0,0.0) [0.0|1] ""  Vector__XXX
 SG_ MRollo_Position : 24|7@1+ (1,0) [0|100] "Unit_PerCent"  Vector__XXX
 SG_ MRollo_Lage : 31|1@1+ (1.0,0.0) [0.0|1] ""  Vector__XXX
 SG_ SAD_normiert : 32|1@1+ (1.0,0.0) [0.0|1] ""  Kombi_PAG
 SG_ SAD_Thermoschutz : 33|1@1+ (1.0,0.0) [0.0|1] ""  Vector__XXX
 SG_ SAD_UEKB_aktiv : 34|1@1+ (1.0,0.0) [0.0|1] ""  Vector__XXX
 SG_ Rollo_normiert : 35|1@1+ (1.0,0.0) [0.0|1] ""  Vector__XXX
 SG_ Rollo_Thermoschutz : 36|1@1+ (1.0,0.0) [0.0|1] ""  Vector__XXX
 SG_ Rollo_UEKB_aktiv : 37|1@1+ (1.0,0.0) [0.0|1] ""  Vector__XXX
 SG_ SAD_Taster_Deckel_hi : 38|4@1+ (1.0,0.0) [0.0|15] ""  Vector__XXX
 SG_ SAD_Taster_Deckel_vo : 42|4@1+ (1.0,0.0) [0.0|15] ""  Vector__XXX
 SG_ SAD_Taster_Rollo_hi : 46|3@1+ (1.0,0.0) [0.0|7] ""  Vector__XXX
 SG_ SAD_Taster_Rollo_vo : 49|3@1+ (1.0,0.0) [0.0|7] ""  Vector__XXX
 SG_ SAD_Anf_ESC_Zuschaltung : 52|1@1+ (1.0,0.0) [0.0|1] ""  Vector__XXX
 SG_ SAD_Text : 53|1@1+ (1.0,0.0) [0.0|1] ""  Kombi_PAG
 SG_ SAD_ToggleBit : 54|1@1+ (1,0) [0|1] ""  Vector__XXX
 SG_ SAD_ParityBit : 55|1@1+ (1,0) [0|1] ""  Vector__XXX

BO_ 424 SARA_11: 8 Gateway
 SG_ SARA_11_CRC : 0|8@1+ (1,0) [0|255] ""  Vector__XXX
 SG_ SARA_11_BZ : 8|4@1+ (1,0) [0|15] ""  Vector__XXX
 SG_ SARA_Accel_X_r : 12|13@1+ (0.16,-655.36) [-655.20|655.04] "Unit_MeterPerSeconSquar"  HUD,Kombi,Kombi_LB,Kombi_PAG
 SG_ SARA_Accel_Y_r : 25|13@1+ (0.16,-655.36) [-655.20|655.04] "Unit_MeterPerSeconSquar"  HUD,Kombi,Kombi_LB,Kombi_PAG
 SG_ SARA_Omega_Z_r : 38|13@1+ (0.08,-327.68) [-327.60|327.52] "Unit_DegreOfArcPerSecon"  Vector__XXX
 SG_ SARA_CF_Accel_X_r : 51|3@1+ (1.0,0.0) [0.0|7] ""  HUD,Kombi,Kombi_LB,Kombi_PAG
 SG_ SARA_CF_Accel_Y_r : 54|3@1+ (1.0,0.0) [0.0|7] ""  HUD,Kombi,Kombi_LB,Kombi_PAG
 SG_ SARA_CF_Omega_Z_r : 57|3@1+ (1.0,0.0) [0.0|7] ""  Vector__XXX

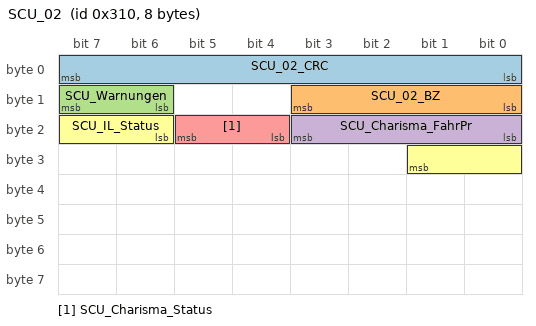
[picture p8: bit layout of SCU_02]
BO_ 784 SCU_02: 8 Gateway
 SG_ SCU_02_CRC : 0|8@1+ (1,0) [0|255] ""  Kombi,Kombi_LB,Kombi_PAG
 SG_ SCU_02_BZ : 8|4@1+ (1,0) [0|15] ""  Kombi,Kombi_LB,Kombi_PAG
 SG_ SCU_Warnungen : 14|2@1+ (1.0,0.0) [0.0|3] ""  Kombi,Kombi_LB,Kombi_PAG
 SG_ SCU_Charisma_FahrPr : 16|4@1+ (1.0,0.0) [0.0|15] ""  Vector__XXX
 SG_ SCU_Charisma_Status : 20|2@1+ (1.0,0.0) [0.0|3] ""  Vector__XXX
 SG_ SCU_IL_Status : 22|4@1+ (1.0,0.0) [0.0|15] ""  Vector__XXX

BO_ 1522 Sensorik_Dimmung_01: 2 Kombi
 SG_ KBI_Phototransistor : 0|8@1+ (1,0) [0|253] ""  Gateway,Gateway_PAG,HUD
 SG_ KBI_Dimmpoti : 8|7@1+ (1,0) [0|100] "Unit_PerCent"  Gateway,Gateway_PAG

BO_ 1363 Sitzmemo_SR3_01: 8 Gateway
 SG_ SR3_Status_Lehne_Links : 12|1@1+ (1.0,0.0) [0.0|1] ""  Kombi,Kombi_PAG
 SG_ SR3_Status_Lehne_Rechts : 13|1@1+ (1.0,0.0) [0.0|1] ""  Kombi,Kombi_PAG

BO_TX_BU_ 1355 :Gateway,Gateway_PAG;
BO_TX_BU_ 803 :Gateway,Gateway_PAG;
BO_TX_BU_ 2527679498 :Gateway,Gateway_PAG;
BO_TX_BU_ 398 :Gateway,Gateway_PAG;
BO_TX_BU_ 1166 :Gateway,Gateway_PAG;
BO_TX_BU_ 319 :Gateway,Gateway_PAG;
BO_TX_BU_ 1122 :Gateway,Gateway_PAG;
BO_TX_BU_ 1123 :Gateway,Gateway_PAG;
BO_TX_BU_ 1124 :Gateway,Gateway_PAG;
BO_TX_BU_ 906 :Gateway,Gateway_PAG;
BO_TX_BU_ 1339 :Gateway,Gateway_PAG;
BO_TX_BU_ 1616 :Gateway,Gateway_PAG;
BO_TX_BU_ 1529 :Gateway,Gateway_PAG;
BO_TX_BU_ 1525 :Gateway,Gateway_PAG;
BO_TX_BU_ 1527 :Gateway,Gateway_PAG;
BO_TX_BU_ 2527679676 :Gateway,Gateway_PAG;
BO_TX_BU_ 1440 :Gateway,Gateway_PAG;
BO_TX_BU_ 2527679790 :Gateway,Gateway_PAG;
BO_TX_BU_ 1504 :Gateway,Gateway_PAG;
BO_TX_BU_ 424 :Gateway,Gateway_PAG;
BO_TX_BU_ 784 :Gateway,Gateway_PAG;
BO_TX_BU_ 1522 :Kombi,Kombi_LB,Kombi_PAG;
BO_TX_BU_ 1363 :Gateway,Gateway_PAG;
CM_ BO_ 1355 "neue Struktur ab MQB ohne KD-Fehler";
CM_ BO_ 1529 "MQB";
CM_ BO_ 1440 "8Byte ab MLBevo
LIN-CAN (1:1) Botschaften werden geroutet
-  wenn entsprechender Slave codiert ist
-  wenn fehlerfreie Kommunikation zum Slave besteht
-  bei fehlerhafter Kommunikation zum Slave wird die Botschaft für 4s mit den letzten gültigen Werte";
CM_ BO_ 1504 "MLBevo 8Byte
LIN-CAN (1:1) Botschaft wird geroutet:
- wenn entsprechender Slave codiert ist
- wenn fehlerfreie Kommunikation zum Slave besteht
- bei fehlerhafter Kommunikation zum Slave wird die Botschaft für 4s mit den letzten gültigen Werten versend";
CM_ BO_ 424 "CAN-Botschaft";
CM_ BO_ 784 "MLBevo";
CM_ BO_ 1522 "MQB";
CM_ BO_ 1363 "Botschaft vom Steuergerät der dritten Sitzreihe";

CM_ SG_ 1355 BCM_WAH_Meldung "Steuert die HMI-Meldungen im Kombi für den Wiederanfahrhinweis";
CM_ SG_ 1355 PDC_Charisma_FahrPr "Istwert der Kennline (siehe System-LAH MQB FPA)";
CM_ SG_ 1355 PDC_Charisma_Status "Charisma Systemstatus des Charisma-Teilnehmers";
CM_ SG_ 1355 PH_Aufschaltursache "Der Grund für die Aufschaltung der Einparkhilfe wird angegeben, z.B. bei der Aktivierung der Einparkhilfe durch eine andere Funktion, wird diese Funktion als Aktivierungsursache für die Dauer der Aktivierung gemeldet.
Das Signal wird den PH_Systemzustand";
CM_ SG_ 1355 PH_Ton_Ausgabe "Anforderung einer Tonausgabe beim MIB3 durch die Parkhilfe";
CM_ SG_ 1355 PH_Ton_Lautstaerke "Wunschlautstärke der Tonanforderung beim MIB3 durch die Parkhilfe.";
CM_ SG_ 1355 PH_Ton_Pausenlaenge "Pause zwischen den angeforderten Tönen beim MIB3 durch die Parkhilfe. Nur für Intervalltöne, nicht relevant für Dauerton und Quittierungston.";
CM_ SG_ 1355 PH_Ton_Richtung "Abspielrichtung des angeforderten Ton beim MIB3 durch die Parkhilfe";
CM_ SG_ 1355 PH_Verschmutzungsmeldung "Meldung einer Verschmutzung/Vereisung der PDC an das Kombi";

CM_ SG_ 803 PCF_01_BZ "Botschaftszähler pro PDU


Botschaft asynchron geroutet. Zählerwert kann springen.";
CM_ SG_ 803 PCF_01_CRC "Für MLB:
'Berechnung siehe Lastenheft 'Kommunikationsabsicherung für Flexray und CAN''

Ab MQB und MLBevo:
'Berechnung siehe Lastenheft 'End-to-End Kommunikationsabsicherung'

Endwerte siehe Begleitdokument 'S-PDU Kennungsfolge'";
CM_ SG_ 803 PCF_HBA_Param "Mitteilung an das ESC-SG, welcher HBA-Parametersatz verwendet werden muss";
CM_ SG_ 803 PCF_Prefill_Anf "Mitteilung an das ESC-SG, dass die Prefill-Funktion aktiviert werden soll";
CM_ SG_ 803 PCF_Ruckprofil "Mitteilung an das ESC-SG welches Ruckprofil angefordert wird";
CM_ SG_ 803 PCF_Verz_Anf "Verzoegerungsanforderung an das ESC";
CM_ SG_ 803 PCF_Verz_Anf_ASIL "ASIL-Level der derzeit angeforderten Verzögerung";
CM_ SG_ 803 PCF_Verz_Auspraegung "Anforderung der Auspraegung einer Bremsanforderung an das ESC-SG";
CM_ SG_ 803 PCF_Verz_Info "Mitteilung an das ESC-SG welche Bremsanforderung aktuell angefordert wird";
CM_ SG_ 803 SC_AbstWarn_Texte "Safety Computer übermittelt Systemstatus der Abstandswarnfunktion an Kombi";
CM_ SG_ 803 SC_WarnBrems_Texte "Safety Computer übermittelt Systemstatus der Funktion Warn- und Bremsfunktion an Kombi";

CM_ SG_ 2527679498 IAA_Active_User_ID "Signal gibt die IAA Nutzer ID des aktiven IAA Nutzers an.";
CM_ SG_ 2527679498 IAA_Identified_User_ID "Signal gibt die IAA Nutzer ID des vom BCM identifizierten IAA Nutzers an";
CM_ SG_ 2527679498 IAA_PSO_wake_up "Signal zum Wake_up der IAA und PSO Komponenten im Kombi und in der OCU";
CM_ SG_ 2527679498 Perso_Aktiv "Status Personalisierung für den Fahrer aktiviert/ deaktiviert (via HMI)";
CM_ SG_ 2527679498 Perso_Bedienstelle "Signal zeigt an, über welche Bedienstelle die Umschaltung des Benutzerkontos gestartet wurden.";
CM_ SG_ 2527679498 Perso_Fahrernummer "Signal gibt die jewels aktuelle Nummer des Fahrers für die Personalisierung an.
Nicht für AU736 und AU48x.";
CM_ SG_ 2527679498 Perso_Freigabe_Verstellung "Signal zeigt an, ob die Ergonomiefunktionen nach Umschaltung des Benutzerkontos verfahren dürfen.";
CM_ SG_ 2527679498 Perso_Kontonummer "Signal gibt die jewels aktuelle Kontonummer für die Personalisierung an.
Nicht für AU736 und AU48x.";
CM_ SG_ 2527679498 Perso_Schreibschutz "Signal zeigt an, ob der Schreibschutz der Personalisierung aktiv ist.";
CM_ SG_ 2527679498 Perso_Status "Codierstatus der Personalisierung
Nicht für AU736 und AU49x.";
CM_ SG_ 2527679498 Perso_Steuerung "Signal gibt einen Steuerungsbefehl an die Funktionsteilnehmer der Personalisierung.
Nicht für AU736 und AU49x.";
CM_ SG_ 2527679498 Perso_Steuerungsparameter "Signal gibt einen Parameter zum Steuerungsbefehl (Signal Perso_Steuerung) für die Personalisierung an.
Nicht für AU736 und AU49x.";

CM_ SG_ 398 PLA2_Anf_Akustik "Anforderung der Akustik durch IPA";
CM_ SG_ 398 PLA2_Anf_Anzeige_Bremsfuss "Anzeige, ob IPA die Anzeige eines Bremsfusses anfordert";
CM_ SG_ 398 PLA2_Anf_Anzeige_Mini "Anforderung der Miniaturanzeige Funktionsstatus IPA";
CM_ SG_ 398 PLA2_Anf_Anzeige_Schwellpfeil "Anzeige, ob IPA im Kombi den Schwellpfeil zur Darstellung der Restwegstrecke im aktuellen Zug anfordert";
CM_ SG_ 398 PLA2_Anf_Anzeigemodus "Anzeigemodus das vom IPA je nach Parkszenario beim Kombi angefordert wird
";
CM_ SG_ 398 PLA2_Anf_Meldungen "Anforderung der Meldungen:
0 - Keine Meldung
1-127 niederprio. Meldungen
128-255 hochprio. Meldungen";
CM_ SG_ 398 PLA2_Anf_Meldungen_FA "Anforderung der Meldungen für Felgenschutz  (FA)";
CM_ SG_ 398 PLA2_Anf_Meldungen_MA "Anforderung der Meldungen für Manövrierassistent (MA)";
CM_ SG_ 398 PLA2_Anzahl_Seg_Schwellpfeil "Wird ein Schwellpfeil angezeigt, gibt dieses Signal die Länge des breiten Balkens in Anzahl der Segmente (max. Länge: 15 Segmente).

Wird keine Anzeige der Schwellpfeile angefordert, muss die Anzahl Segmente 0 sein.";
CM_ SG_ 398 PLA2_Mini_Modus "Art des vom IPA zur Darstellung angeforderten Minis. Wird angezeigt, wenn PLA2_Anf_Anzeige_Mini=1.";
CM_ SG_ 398 PLA2_Status_Aktive_Seite "Anzeige der zu parkenden Seite";
CM_ SG_ 398 PLA2_Status_Funktion "Funktionsstati, die die einzelnen Schritte innerhalb eines Parkszenarios anzeigen.";

CM_ SG_ 1166 PLA_Anf_Akustik "Anzeige, ob das PLA einen Gong im Kombi anfordert, Gong soll mit dem Übergang 0->1 abgespielt werden.";
CM_ SG_ 1166 PLA_Anf_Anzeige_Bremsfuss "Anzeige, ob PLA die Anzeige eines Bremsfusses anfordert";
CM_ SG_ 1166 PLA_Anf_Anzeige_Mini "Anforderung der Miniaturanzeige ";
CM_ SG_ 1166 PLA_Anf_Anzeige_Schwellpfeil "Anzeige, ob PLA im Kombi den Schwellpfeil zur Darstellung der Restwegstrecke im aktuellen Zug anfordert";
CM_ SG_ 1166 PLA_Anf_Anzeigemodus "Anzeigemodus das vom PLA je nach Parkszenario beim Kombi angefordert wird";
CM_ SG_ 1166 PLA_Anf_Meldungen "Anforderung der Meldungen:
0 - Keine Meldung
1-127 niederprio. Meldungen
128-255 hochprio. Meldungen";
CM_ SG_ 1166 PLA_Anforderung_HMS "Für die Anforderung der HMS Funktionen";
CM_ SG_ 1166 PLA_Anzahl_Segmente_Schwellpfeil "Wird ein Schwellpfeil angezeigt, gibt dieses Signal die Länge des breiten Balkens in Anzahl der Segmente (max. Länge: 15 Segmente).

Wird keine Anzeige der Schwellpfeile angefordert, muss die Anzahl Segmente 0 sein.";
CM_ SG_ 1166 PLA_Mini_Modus "Art des vom PLA zur Darstellung angeforderten Minis. Wird angezeigt, wenn PLA_Anf_Anzeige_Mini=1.";
CM_ SG_ 1166 PLA_Status_Aktive_Seite "Anzeige der zu parkenden Seite";
CM_ SG_ 1166 PLA_Status_beenden_Mini "Status Anzeige beendet Mini";
CM_ SG_ 1166 PLA_Status_Funktion "Funktionsstati, die die einzelnen Schritte innerhalb eines Parkszenarios anzeigen.";
CM_ SG_ 1166 PLA_Status_Laengsparken_Mini "Status Anzeige Längsparken Mini";
CM_ SG_ 1166 PLA_Status_QP_Rueckw_Mini "Status Anzeige Querparken rückwärts Mini";
CM_ SG_ 1166 PLA_Status_QP_Vorw_Mini "Status Anzeige Querparken vorwärtsMini";

CM_ SG_ 319 PreCrash_02_BZ "Botschaftszaehler
Botschaft asynchron geroutet. Zählerwert kann springen.";
CM_ SG_ 319 PreCrash_02_CRC "Ab MQB und MLBevo:
'Berechnung siehe Lastenheft 'End-to-End Kommunikationsabsicherung''

Endwerte siehe Begleitdokument 'S-PDU Kennungsfolgen'";
CM_ SG_ 319 PreCrash_Anforderung_AFR "Anforderungen der Funktion PrecrashSeite an Fahrwerksregelung";
CM_ SG_ 319 PreCrash_BFS_KSV_verfahren "Ansteuerung der Kopfstuetze Beifahrerseite durch die Funktion PreCrash

Signalwert 0x09 für vereinfachte Ansteuerung mit Logik im Sitz-SG (MQB37W)";
CM_ SG_ 319 PreCrash_BFS_Pneumatik_ansteuern "Ansteuerung des Beifahrersitzes durch die PreCrash-Funktionen";
CM_ SG_ 319 PreCrash_BFS_Sitzlehne_verfahren "Ansteuerung des Beifahrersitzes durch die PreCrash-Funktionen

Wert 0x06 und 0x07 für vereinfachte Ansteuerung Sitzlehne";
CM_ SG_ 319 PreCrash_Blinken "Safety Computer übermittelt Blinkverhalten bei einer PreCrash-Auslösung an den BCM2";
CM_ SG_ 319 PreCrash_Charisma_FahrPr "Aktuell eingestelltes Fahrprogramm der Funktion PreCrash";
CM_ SG_ 319 PreCrash_Charisma_Status "Verfügbarkeit der Funktion PreCrash für die Ansteuerung durch den Charisma_Koordinator";
CM_ SG_ 319 PreCrash_Fenster_schliessen "Anforderung Seitenscheiben schließen durch die Funktion PreCrash";
CM_ SG_ 319 PreCrash_Fo_KSV_verfahren "Ansteuerung der Kopfstuetzen im Fond durch die PreCrash-Funktionen";
CM_ SG_ 319 PreCrash_Fo_Pneumatik_ansteuern "Ansteuerung der Fondsitze durch die PreCrash-Funktionen";
CM_ SG_ 319 PreCrash_Fo_Sitzlehne_verfahren "Ansteuerung des Fondsitzes durch die PreCrash-Funktionen";
CM_ SG_ 319 PreCrash_FS_KSV_verfahren "Ansteuerung der Kopfstuetze Fahrerseite durch die PreCrash-Funktionen

Signalwert 0x09 für vereinfachte Ansteuerung mit Logik im Sitz-SG (MQB37W)";
CM_ SG_ 319 PreCrash_FS_Pneumatik_ansteuern "Ansteuerung des Fahrersitzes durch die PreCrash-Funktionen";
CM_ SG_ 319 PreCrash_FS_Sitzlehne_verfahren "Ansteuerung des Fahrersitzes durch die PreCrash-Funktionen

Wert 0x06 und 0x07 für vereinfachte Ansteuerung Sitzlehne";
CM_ SG_ 319 PreCrash_Schiebedach_schliessen "Anforderung Schiebedach schließen durch die Funktion PreCrash";
CM_ SG_ 319 PreCrash_Tueren_Verriegeln "Anforderung Türen Verriegeln durch die Funktion PreCrash";
CM_ SG_ 319 SC_PreCrash_LED "Ansteuerung LED-Leiste im Kombi durch SC";
CM_ SG_ 319 SC_PreCrash_Texte "Safety Computer übermittelt Systemstatus der PreCrash Funktionen an Kombi";
CM_ SG_ 319 SC_PreCrash_Warnung "Safety Computer übermittelt Warnung der PreCrash Funktionen an Kombi";
CM_ SG_ 319 SC_PreSense_FCWP "Mitteilung an das NightVision, auf welche Art von Objekt eine Warnung angefordert wird";

CM_ SG_ 1122 PSD_Abzweigerichtung "Richtung, in der die Abzweigung von der Hauptroute abzweigt
";
CM_ SG_ 1122 PSD_Abzweigewinkel "Winkel, unter dem die Abzweigung von der Hauptroute abzweigt.
";
CM_ SG_ 1122 PSD_ADAS_Qualitaet "ADAS Qualtität des Streckensegments.";
CM_ SG_ 1122 PSD_Anfangskruemmung "Startkrümmung der Klothoide des übermittelten abzweigenden Streckensegments. 
1/(1+0.155 * x^2) {1/m}'
";
CM_ SG_ 1122 PSD_Anfangskruemmung_Vorz "Vorzeichen für die Startkrümmung bei Abzweigungen
";
CM_ SG_ 1122 PSD_Bebauung "Segement befindet sich innerhalb bebauten Gebietes";
CM_ SG_ 1122 PSD_Endkruemmung "'Endkrümmung der Klotoide des übermittelten Streckensegments. Die Anfangskrümmung des folgenden Streckensegments entspricht der Endkrümmung dieses Segments. Krümmung = 1/(1+0.155 * x²) [1/m]

";
CM_ SG_ 1122 PSD_Fahrspuren_Anzahl "Anzahl der Fahrspuren in Fahrtrichtung
";
CM_ SG_ 1122 PSD_Geradester_Pfad "Segment ist Teil des geradesten Pfades";
CM_ SG_ 1122 PSD_Idenditaets_ID "Identifier auf ein Streckensegment, dass mit dem aktuell übertragenen geometrisch identisch ist.";
CM_ SG_ 1122 PSD_Segment_ID "Identifier des prädiktiven Streckensegments
";
CM_ SG_ 1122 PSD_Segment_Komplett "Zeigt, ob alle Attribute für das Segment übertragen worden sind
";
CM_ SG_ 1122 PSD_Segmentlaenge "Gesamtlänge des prädiktiven Streckensegments";
CM_ SG_ 1122 PSD_Strassenkategorie "Klassifizierung der Straße des beschriebenen Segments
";
CM_ SG_ 1122 PSD_Vorgaenger_Segment_ID "An dem Streckensegment mit diesem Identifier schließt sich das neue Segment mit der ID 'PSD_01_Segment_ID' an.
";
CM_ SG_ 1122 PSD_wahrscheinlichster_Pfad "Identifiziert den vom Navigationssystem berechneten wahrscheinlichsten Pfad des Fahrzeuges. ";

CM_ SG_ 1123 PSD_Attribut_1_ID "Identifier des ersten Attributes";
CM_ SG_ 1123 PSD_Attribut_1_Offset "Positionsoffset im Segment für die Position des Attributs";
CM_ SG_ 1123 PSD_Attribut_1_Wert "Wert des ersten Attributes";
CM_ SG_ 1123 PSD_Attribut_2_ID "Identifier des zweiten Attributes";
CM_ SG_ 1123 PSD_Attribut_2_Offset "Positionsoffset im Segment für die Position des Attributs";
CM_ SG_ 1123 PSD_Attribut_2_Wert "Wert des zweiten Attributes";
CM_ SG_ 1123 PSD_Attribut_Segment_ID_05 "Identifier des Streckensegments, für das die weiteren Attribute in der Botschaft gültig sind";
CM_ SG_ 1123 PSD_Attribute_Komplett_05 "Zeigt, ob alle Attribute für das Segment übertragen worden sind";
CM_ SG_ 1123 PSD_Pos_Fahrspur "Spur, auf der sich das Fahrzeug aktuell befindet";
CM_ SG_ 1123 PSD_Pos_Fehler_Laengsrichtung "Laengsfehler der Positionierung";
CM_ SG_ 1123 PSD_Pos_Inhibitzeit "Zeitspanne zwischen Generierung der PSD Daten im Navigationssystem und Versand der Daten auf den Most
";
CM_ SG_ 1123 PSD_Pos_Segment_ID "Identifier des Streckensegments, auf dem sich das Fahrzeug aktuell befindet
";
CM_ SG_ 1123 PSD_Pos_Segmentlaenge "Verbleibende Länge des Streckensegments, auf dem sich das Fahrzeug aktuell befindet
";
CM_ SG_ 1123 PSD_Pos_Standort_Eindeutig "Ist die Position des Fahrzeugs eindeutig dem aktuelle Segment zugeordnet, oder gibt es fahrbare alternative Segmente, die bei akteller GPS-Position ebenfalls als aktuelles Segment möglich wären.";

CM_ SG_ 1124 PSD_06_Mux "Multiplex Zähler für die PSD_06-Botschaft.
Die unterschiedlichen Muxe folgen keiner festen Reihenfolge. Je nach Inhalt des PSD-Protokolls an der aktuellen Position werden jeweils die notwendigen PSD6-Botschaften gesendet.";
CM_ SG_ 1124 PSD_Attribut_3_ID "Identifier des dritten Attributes";
CM_ SG_ 1124 PSD_Attribut_3_Offset "Positionsoffset im Segment für die Position des Attributs";
CM_ SG_ 1124 PSD_Attribut_3_Wert "Wert des dritten Attributes";
CM_ SG_ 1124 PSD_Attribut_4_ID "Typ von Attribut 4";
CM_ SG_ 1124 PSD_Attribut_4_Offset "Offset von Attribut 4";
CM_ SG_ 1124 PSD_Attribut_4_Wert "Wert von Attribut 4";
CM_ SG_ 1124 PSD_Attribut_5_ID "Typ von Attribut 5";
CM_ SG_ 1124 PSD_Attribut_5_Offset "Offset von Attribut 5";
CM_ SG_ 1124 PSD_Attribut_5_Wert "Wert von Attribut 5";
CM_ SG_ 1124 PSD_Attribut_Segment_ID "Identifier des Streckensegments,für das die weiteren Attribute in der Botschaft gültig sind";
CM_ SG_ 1124 PSD_Attribute_Komplett_06 "Zeigt, ob alle Attribute für das Segment übertragen worden sind
";
CM_ SG_ 1124 PSD_Baum_Ausrichtung "Ausrichtung des Fahrzeugsegments zu Nord";
CM_ SG_ 1124 PSD_Baum_Breite "WGS84 Breite des Fahrzeugsegments";
CM_ SG_ 1124 PSD_Baum_Breite_VZ "Vorzeichen WGS84 Breite des Fahrzeugsegments";
CM_ SG_ 1124 PSD_Baum_Laenge "WGS84 Laenge des Fahrzeugsegments";
CM_ SG_ 1124 PSD_Baum_Laenge_VZ "Vorzeichen WGS84 Laenge des Fahrzeugsegments";
CM_ SG_ 1124 PSD_Ges_Attribute_Komplett "Zeigt, ob alle Attribute für das Segment übertragen worden sind";
CM_ SG_ 1124 PSD_Ges_Geschwindigkeit_Gespann "Gilt diese Einschränkung der Geschwindigkeit für alle Fahrzeuge oder ausschließlich für PKW mit Gespann oder für LKW, Buss, etc.";
CM_ SG_ 1124 PSD_Ges_Geschwindigkeit_Std_Anf "Stunde, zu der die stündliche Geschwindigkeitsbegrenzung beginnt
0h.. 24h";
CM_ SG_ 1124 PSD_Ges_Geschwindigkeit_Std_Ende "Stunde, an der die stündliche Geschwindigkeitsbegrenzung endet
0h.. 24h";
CM_ SG_ 1124 PSD_Ges_Geschwindigkeit_Tag_Anf "Wochentag, an dem die tägliche Geschwindigkeitsbegrenzung beginnt";
CM_ SG_ 1124 PSD_Ges_Geschwindigkeit_Tag_Ende "Wochentag, an dem die tägliche Geschwindigkeitsbegrenzung endet";
CM_ SG_ 1124 PSD_Ges_Geschwindigkeit_Witter "Witterungsabhängigkeit der Geschwindigkeitsbegrenzung";
CM_ SG_ 1124 PSD_Ges_Gesetzlich_Kategorie "Kategorie für das legale Gebot";
CM_ SG_ 1124 PSD_Ges_Gesetzlich_Zusatz "Zusatz für das legale Gebot";
CM_ SG_ 1124 PSD_Ges_Offset "Positionsoffset im Segment für die Position des Attributs";
CM_ SG_ 1124 PSD_Ges_Segment_ID "Identifier des prädiktiven Streckensegments ab dem die Geschwindigkeitsbegrenzungen und mögliche Einschränkungen gelten.
";
CM_ SG_ 1124 PSD_Ges_Spur_Geschw_Begrenzung "Definition der Spuren, für die das übertragene Gebot gilt";
CM_ SG_ 1124 PSD_Ges_Typ "Typ der Geschwindigkeitsbegrenzung
";
CM_ SG_ 1124 PSD_Ges_Verkehrszeichen_Quelle "Quelle der Verkehrszeicheninformation";
CM_ SG_ 1124 PSD_Ges_Wechselverkehrszeichen "Am Beginn des Segments ist ein Wechselverkehrszeichen angebracht.";
CM_ SG_ 1124 PSD_Steigung_1_A_Offset "Positionsoffset im Segment für die Position der Steigung 1 A";
CM_ SG_ 1124 PSD_Steigung_1_A_Steigung "Steigung des Segments ab Offset 1A";
CM_ SG_ 1124 PSD_Steigung_1_A_Vorz "Vorzeichen für Steigung 1 A";
CM_ SG_ 1124 PSD_Steigung_1_Attribute_kompl "Alle Steigungsdaten für dieses Segment gesendet";
CM_ SG_ 1124 PSD_Steigung_1_B_Offset "Positionsoffset im Segment für die Position der Steigung 1 B";
CM_ SG_ 1124 PSD_Steigung_1_B_Steigung "Steigung des Segments ab Offset 1B";
CM_ SG_ 1124 PSD_Steigung_1_B_Vorz "Vorzeichen für Steigung 1 B";
CM_ SG_ 1124 PSD_Steigung_1_Segment_ID "Identifier des prädiktiven Streckensegments, zu dem die  ersten beiden Steigungswerte dieser Botschaft gehören";
CM_ SG_ 1124 PSD_Steigung_2_Attribute_kompl "Alle Steigungsdaten für dieses Segment gesendet";
CM_ SG_ 1124 PSD_Steigung_2_Offset "Positionsoffset im Segment für die Position der Steigung 2";
CM_ SG_ 1124 PSD_Steigung_2_Segment_ID "Identifier des prädiktiven Streckensegments, zu dem der dritte Steigungswert dieser Botschaft gehört";
CM_ SG_ 1124 PSD_Steigung_2_Steigung "Steigung des Segments ab Offset 2";
CM_ SG_ 1124 PSD_Steigung_2_Vorz "Vorzeichen für Steigung 2";
CM_ SG_ 1124 PSD_Sys_Alter_Karte "Alter der Karte";
CM_ SG_ 1124 PSD_Sys_Geometrieguete "Maß für die Güte der Klothoidengeometrie.";
CM_ SG_ 1124 PSD_Sys_Geometrieguete_erweitert "Güte der Kurvenrepräsentation der Klothoiden";
CM_ SG_ 1124 PSD_Sys_Geschwindigkeit_Einheit "Unterscheidung zwischen km/h und miles/h";
CM_ SG_ 1124 PSD_Sys_Laendercode "Ländercode
";
CM_ SG_ 1124 PSD_Sys_Mapmatchingguete "Güte des Mapmatchings";
CM_ SG_ 1124 PSD_Sys_Quali_Geometrien "Qualität der Geometrien in dieser Region";
CM_ SG_ 1124 PSD_Sys_Quali_Ortsinfo "Qualität Ortsinformationen (Bebauung, Ortsschild) dieser Region";
CM_ SG_ 1124 PSD_Sys_Quali_sonstige_Attribute "Qualität sonstiger Attribute dieser Region";
CM_ SG_ 1124 PSD_Sys_Quali_Steigungen "Qualität der Steigungen dieser Region";
CM_ SG_ 1124 PSD_Sys_Quali_Strassenkennz "Qualität Straßenkennzeichnungen dieser Region";
CM_ SG_ 1124 PSD_Sys_Quali_Tempolimits "Qualität Tempolimits dieser Region";
CM_ SG_ 1124 PSD_Sys_Quali_verfuegbar "Karte enthält gültige Qualitätskriterien";
CM_ SG_ 1124 PSD_Sys_Quali_Vorfahrtsregelung "Qualität Vorfahrtsregelungen dieser Region";
CM_ SG_ 1124 PSD_Sys_Segment_ID "Identifier des prädiktiven Streckensegments ab dem die Systeminformationen gültig sind.
";
CM_ SG_ 1124 PSD_Sys_US_State "Name des USA-State";
CM_ SG_ 1124 PSD_Sys_Verkehrsrichtung "Unterscheidung zwischen Linksverkehr und Rechtsverkehr";
CM_ SG_ 1124 PSD_Sys_Zielfuehrung "Zielfuehrung im Navigationssystem. Damit lässt sich der wahrscheinlichste Pfad des Fahrzeuges zuverlässig angeben.";
CM_ SG_ 1124 PSD_Sys_Zielfuehrung_geaendert "Die Zielführung (Route) hat sich geändert hat ohne dass der Fahrer eine neue Zielführung gestartet hat";
CM_ SG_ 1124 PSD_Wechselverkehrszeichen_Typ "Typ des Wechselverkehrszeichen";

CM_ SG_ 2463978730 pVS_Hinweismeldung "Hinweismeldung, falls die Geschwindigkeitsvorgabe überschritten wird / sich ändert";
CM_ SG_ 2463978730 pVS_IconActivation "Boolean zur Ansteuerung eines pVS-Icons im Kombi (pVS on/off).";
CM_ SG_ 2463978730 pVS_Note_SpeedAdjustment "Boolean zur Ansteuerung eines Hinweises (z.B. Blinken) im Falle eine V_Limit-Anpassung durch pVS im Kombi.";
CM_ SG_ 2463978730 pVS_vLimit_HMI "Geschwindigkeit für die dynamische Anzeige in der pVS_Hinweismeldung";
CM_ SG_ 2463978730 pVS_vLimit_HMI_Unit "Angabe für die Einheit der Geschwindigkeitsvorgabe";
CM_ SG_ 2463978730 pVS_vLimit_Range "Von der prädiktiven Verbrauchssteuerung bzw. im Fahrprogramm  Range konfiguriertes Limit";
CM_ SG_ 2463978730 pVS_vLimit_Range_HMI "Von der prädiktiven Verbrauchssteuerung bzw. im Fahrprogramm  Range konfiguriertes Limit für Anzeigezwecke. Diese Signal hat einen zeitlichen Vorlauf im Vergleich zu pVS_vLimit_Range";
CM_ SG_ 2463978730 pVS_vLimit_Range_pers "Vom Fahrer für den Range Mode personalisiertes Geschwindigkeitslimit";

CM_ SG_ 906 QSP_03_BZ "BZ der QSP_03
Botschaft asynchron geroutet. Zählerwert kann springen.";
CM_ SG_ 906 QSP_03_CRC "Ab MQB und MLBevo:
'Berechnung siehe Lastenheft 'End-to-End Kommunikationsabsicherung''

Endwerte siehe Begleitdokument 'S-PDU Kennungsfolgen'";
CM_ SG_ 906 QSP_Init "Status Initialisierungsphase";
CM_ SG_ 906 QSP_Ist_Moment "Gib an welches (Ist)Moment aktuell vom QSP verlagert wird.

negativ: mehr Antriebsmoment nach rechts (/rechtes Rad wird beschleuningt)

positiv: mehr Antriebsmoment nach links (/linkes Rad wird beschleuningt)";
CM_ SG_ 906 QSP_Status "Status der QSP-ECU:
Dient der synchronisation von QSP mit EFP

0x00 Abgeschaltet
0x01 Init
0x02 Bereit
0x03 Normalbetrieb
0x04 Temporaer_beendet (Beenden des aktuellen Eingriffs,
anschließend Übergang in Temporaer_abgeschaltet)
0x05 Temporaer_abg";
CM_ SG_ 906 QSP_Temperatur_Oel "Aktuelle Hydrauli-Oel-Temperatur";
CM_ SG_ 906 QSP_Thermische_Belastung "Maximale aktuelle thermische Belastung des Gesamtsystems (Motor, ECU, Kupplungen)";
CM_ SG_ 906 QSP_Warnlampe "Status der Warnlampe: aktuell anliegender Fehlerzustand";

CM_ SG_ 1339 QS_Charisma_FahrPr "MLBevoKonzern: Aktuelles Fahrprogramm des Charisma-Teilnehmers";
CM_ SG_ 1339 QS_Charisma_Status "Charisma Systemstatus des Charisma-Teilnehmers

Wert 0x3 ist nur für Fahrzeuge ab MQB relevant";
CM_ SG_ 1339 QS_Symbol_Rear_Lock "Anzeige von gelockter Quersperre im Offroad-Modus";
CM_ SG_ 1339 QS_Warntexte "Anzeige von Warn- oder Fehlermeldungen der geregelten Quersperre.";

CM_ SG_ 1616 RA_AM_Tuning "Das Signal kennzeichnet einen aktiven AM Suchlauf. Während des Suchlaufes wird die Frequenz = 0 übertragen.
0 = frequency locked => Störquelle vermeidet die aktuelle Frequenz
1 = AM tuning in progress => Störquelle abschalten bzw.PWM Signal auf DC umsch";
CM_ SG_ 1616 RA_Frequency "Übermittlung der eingestellten Sendefrequenz AM oder FM, diese wird mit RA_Frequency_unit multipliziert.
Im DAB oder Hybrid/Online Mode wird die aktuelle FM-Alternativfrequenz oder, falls nicht vorhanden, die zuletzt gehörte Senderfrequenz übertragen (AM";
CM_ SG_ 1616 RA_Frequency_unit "Faktor für RA_Frequency
bei AM: Faktor 0 = 1kHz
sonst   Faktor 1 = 100kHz";
CM_ SG_ 1616 RA_PowerAmpOn "1 = Request for Amplifier; 0 = Amplifier mute/off";
CM_ SG_ 1616 RA_Radio_Error_Flag "1 = mindestens ein Kundendienstfehlerspeicher Eintrag vorhanden";
CM_ SG_ 1616 RA_Radio_mute "1=Radio is muted for telephone";
CM_ SG_ 1616 RA_Radio_on "1 = user perceived On";
CM_ SG_ 1616 RA_Radio_Surround "1 = Surround ON; 0 = Surround OFF
requests the Amp to switch Surroundmode";
CM_ SG_ 1616 RA_VNC_OFF "VNC = Vehicle Noice Cancellation;
1 = VNC OFF; 0 = VNC ON
requests the Amp to switch VNC off";

CM_ SG_ 1529 RDK_angelernt "RDK signalisiert, dass die Radelektroniken angelernt sind und das Kombi den Rundstreckenmodus anbieten kann.";
CM_ SG_ 1529 RDK_FMVSS138_Lampe "Ansteuerung der RDK-Lampe im Kombi bei Druckwarnung";
CM_ SG_ 1529 RDK_FMVSS138_MIL "Ansteuerung der RDK-Lampe im Kombi bei Systemstörung.
RDK-Lampe muss für 65 Sekunden blinken und anschliessend dauerhaft leuchten bis RDK dieses Bit wieder auf '0' setzt (Wiedergutprüfung).
Hinweis:  Im AU48x blinken für 60 Sekunden";
CM_ SG_ 1529 RDK_Kalibrierung "Art der Vorgabe der Solldrücke
0x0 Vorgabe der Solldrücke erfolgt durch eine Reifenauswahl in der Headunit
0x1 Vorgabe der Solldrücke erfolgt durch Betätigung des SET-Tasters des Kombiinstruments";
CM_ SG_ 1529 RDK_Reifendruck_Lampe "Ansteuerung einer RDK-Lampe im Kombi bei einem problematischen Druck";
CM_ SG_ 1529 RDK_Reifentemperatur_Lampe "Ansteuerung einer RDK-Lampe im Kombi bei einer problematischen Reifentemperatur";
CM_ SG_ 1529 RDK_RS_aktiv "Rundstreckenmodus inaktiv/ aktiv";
CM_ SG_ 1529 RDK_Text_7 "Textausgabe 7: Mindestdruck für Rundstreckenmode unterschritten";
CM_ SG_ 1529 RDK_W_1_Reifen_HL "Harte Warnung fuer Reifen hinten links";
CM_ SG_ 1529 RDK_W_1_Reifen_HR "Harte Warnung fuer Reifen hinten rechts";
CM_ SG_ 1529 RDK_W_1_Reifen_VL "Harte Warnung fuer Reifen vorne links";
CM_ SG_ 1529 RDK_W_1_Reifen_VR "Harte Warnung fuer Reifen vorne rechts";
CM_ SG_ 1529 RDK_W_2_Reifen_HL "Weiche Warnung fuer Reifen hinten links";
CM_ SG_ 1529 RDK_W_2_Reifen_HR "Weiche Warnung fuer Reifen hinten rechts";
CM_ SG_ 1529 RDK_W_2_Reifen_VL "Weiche Warnung fuer Reifen vorne links";
CM_ SG_ 1529 RDK_W_2_Reifen_VR "Weiche Warnung fuer Reifen vorne rechts";
CM_ SG_ 1529 RDK_Warnungen_02 "Ausgabe von Texten/Akustik im Kombiinstrument";

CM_ SG_ 1525 RW_Gesamt_Reichweite "Reichweite für primär und sekundär Reichweite (eventuell Gewichtet)";
CM_ SG_ 1525 RW_Gesamt_Reichweite_Max_Anzeige "Angabe der Maximalen Anzeige der gesamten Reichweite.
Ergänzt das Signal RW_Gesamt_Reichweite_Anzeige.Die Einheit dieser Signal ist über RW_Reichweite_Einheit_Anzeige bereitgestellt.";
CM_ SG_ 1525 RW_Prim_Reichweitenv_Einheit "Für primäre  Reichweitenberechnung (KBI_Prim_Reichweitenverbrauch) zugrunde gelegte Einheit";
CM_ SG_ 1525 RW_Prim_Reichweitenverbrauch "Für primäre Reichweitenberechnung zugrunde gelegter Verbrauch";
CM_ SG_ 1525 RW_Primaer_Reichweite "Reichweite der primären Antriebsart";
CM_ SG_ 1525 RW_Reservewarnung_2_aktiv "Ansteuerung der Reservewarnung im Kombiinstrument (Leuchte und MFA-Warnhinweis). Wird gesetzt bei Erreichen / Unterschreiten eines unteren Reichweitenschwellwerts und zurückgenommen bei Erreich.
Zusätzlich erfolgt eine logische Verknüpfung mit einer akti";
CM_ SG_ 1525 RW_RWDS_Lastprofil "Lastprofil zur Bestimmung der notwendigen Nachladeenergie (Reichweitendurchschnittstrom)";

CM_ SG_ 1527 RW_Gesamt_Reichweite_Anzeige "Reichweite für primär und sekundär Reichweite (eventuell Gewichtet) zur Anzeige im Kombi. Die Einheit dieser Signal ist über RW_Reichweite_Einheit_Anzeige bereitgestellt.";
CM_ SG_ 1527 RW_Primaer_Reichweite_Anzeige "Reichweite der primären Antriebsart zur Anzeige im Kombi";
CM_ SG_ 1527 RW_Reichweite_Einheit_Anzeige "Einheit für Primaer-/Sekundaer-/Gesamt- Reichweite zur Anzeige im Kombi";
CM_ SG_ 1527 RW_Reservewarnung_aktiv "Ansteuerung der Reservewarnung im Kombiinstrument (Leuchte und MFA-Warnhinweis). Wird gesetzt bei Erreichen / Unterschreiten eines unteren Reichweitenschwellwerts und zurückgenommen bei Erreichen / Überschreiten eines oberen Reichweitenschwellwerts.";
CM_ SG_ 1527 RW_Sek_Reichweitenv_Einheit "Für sekundäre Reichweitenberechnung (KBI_Sek_Reichweitenverbrauch) zugrunde gelegte Einheit";
CM_ SG_ 1527 RW_Sek_Reichweitenverbrauch "Für sekundäre Reichweitenberechnung zugrunde gelegter Verbrauch";
CM_ SG_ 1527 RW_Sekundaer_Reichweite "Reichweite der sekundaeren Antriebsart";
CM_ SG_ 1527 RW_Sekundaer_Reichweite_Anzeige "Reichweite der sekundaeren Antriebsart zur Anzeige im Kombi";
CM_ SG_ 1527 RW_Tendenz "Signalisierung der RW-Tendenz auf Basis der aktuellen Fahrweise. ";
CM_ SG_ 1527 RW_Texte "Signal zum Steuern von reichweitenbezogenen Hinweistexten für Pop-Up Anzeigen im Kombiinstrument";

CM_ SG_ 2527679676 RW_Prim_rRWB_aktiv "Signalisiert eine aktive Routen basierende Reichweitenberechnung";
CM_ SG_ 2527679676 RW_Prim_rRWB_Reichw_Anz "Routen basierende Reichweite im Fall einer Navi Zielfuehrung";
CM_ SG_ 2527679676 RW_Prim_rRWB_Reichw_Gesamt_Anz "Gesamte Routen basierende Reichweite im Fall einer Navi Zielfuehrung";
CM_ SG_ 2527679676 RW_Prim_rRWB_Reichw_Max_Ges_Anz "Routen basierende gesamte maximal Reichweite im Fall einer Navi Zielfuehrung.
Einheit über RW_Reichweite_Einheit_Anzeige definiert.";
CM_ SG_ 2527679676 RW_Prim_rRWB_Reichw_Rest_E_Anz "Reichweite basierend auf dem Restenergieinhalt am Ziel im Fall einer Navi Zielfuehrung";
CM_ SG_ 2527679676 RW_Prim_statische_Reichw_Anz "Orientierungsreichweite aufgrund eines festen, bzw. geringfuegig adaptierbaren Reichweitenverbrauches";

CM_ SG_ 1440 LS_defekt "Fehlererkennung Lichtsensor
";
CM_ SG_ 1440 LS_Helligkeit_FW "Vorfeldhelligkeit";
CM_ SG_ 1440 LS_Helligkeit_IR "Globalfeldhelligkeit";
CM_ SG_ 1440 LS_Verbau "Verbauinfo Lichtsensor";
CM_ SG_ 1440 RLS_Vorfeldhelligkeit_Boost "erweiterte Helligkeitssensierung für HUD";
CM_ SG_ 1440 RS_defekt "Fehlererkennung Regensensor";
CM_ SG_ 1440 RS_Regenmenge "Regenmenge";
CM_ SG_ 1440 RS_Verbau "Verbauinfo Regensensor";
CM_ SG_ 1440 RS_Verglasung_schliessen "Anforderung: Verglasung schliessen
";
CM_ SG_ 1440 RS_Wischergeschwindigkeit "Wischergeschwindigkeit (Hübe/min)";

CM_ SG_ 2527679790 RTM_Fehlerstatus "The error status of RTM.";
CM_ SG_ 2527679790 RTM_IstModus "The operation status of RTM";
CM_ SG_ 2527679790 RTM_OTA_Download_Process "RTM OTA package download process in percentage[%]:0~100%";
CM_ SG_ 2527679790 RTM_OTA_Download_Size "The size of OTA download package [MB]";
CM_ SG_ 2527679790 RTM_OTA_Download_Speed "RTM OTA package download speed
[MB/s]";
CM_ SG_ 2527679790 RTM_OTA_InstallDuration "The estimated duration of  OTA package installation
Range:1-30min";
CM_ SG_ 2527679790 RTM_OTA_InstallPrecondition "The precondition check for SW upgrade installation.";
CM_ SG_ 2527679790 RTM_OTA_InstallProcess "RTM OTA package installation process in percentage[%]:0~100%";
CM_ SG_ 2527679790 RTM_OTA_SignalStrength "The signal strength during OTA package downloading";

CM_ SG_ 1504 MD1_Lage "Lage Schiebedachstellung 1 (Signal wird 1:1 vom BCM2 geroutet; ursprünglicher Sender: SAD = LIN-Slave vom BCM2)";
CM_ SG_ 1504 MD1_Position "Aktuelle Öffnungsweite Schiebedach.";
CM_ SG_ 1504 MD3_Lage "Lage Schiebedachstellung 3 
(Signal wird 1:1 vom BCM2 geroutet; ursprünglicher Sender: SAD = LIN-Slave vom BCM2) 
";
CM_ SG_ 1504 MD3_Position "Schiebedachstellung 3 
(Signal wird 1:1 vom BCM2 geroutet; ursprünglicher Sender: SAD = LIN-Slave vom BCM2)
";
CM_ SG_ 1504 MRollo_Lage "Lage Rollo
(Signal wird 1:1 vom BCM2 geroutet; ursprünglicher Sender: Rollo = LIN-Slave vom BCM2)";
CM_ SG_ 1504 MRollo_Position "Aktuelle Öffnungsweite des Dachrollos.";
CM_ SG_ 1504 Rollo_normiert "Anzeigen Normierung des Dachrollos";
CM_ SG_ 1504 Rollo_Thermoschutz "Anzeigen aktivierter Thermoschutz des Dachrollo";
CM_ SG_ 1504 Rollo_UEKB_aktiv "Anzeigen aktivierter Überschusskraftbegrenzung des Dachrollos";
CM_ SG_ 1504 SAD_Anf_ESC_Zuschaltung "Zwangsaktivierung ESP durch SAD-SG (bei geöffnetem Schiebedach und V> xx km/h).";
CM_ SG_ 1504 SAD_normiert "Anzeige Normierung des Schiebeausstelldaches";
CM_ SG_ 1504 SAD_ParityBit "SIL A Absicherung für die Signale: SAD_normiert, MD1_Lage, MD1_Position, SAD_Anf_ESC_Zuschaltung";
CM_ SG_ 1504 SAD_Taster_Deckel_hi "Taster für SAD Deckel hinten";
CM_ SG_ 1504 SAD_Taster_Deckel_vo "Taster für SAD Deckel vorne";
CM_ SG_ 1504 SAD_Taster_Rollo_hi "Taster für SAD Rollo hinten";
CM_ SG_ 1504 SAD_Taster_Rollo_vo "Taster für SAD Rollo vorne";
CM_ SG_ 1504 SAD_Text "Fehler Windabweiser in Abhängigkeit von der Geschwindigkeit";
CM_ SG_ 1504 SAD_Thermoschutz "Anzeige aktivierter Thermoschutz des Schiebeausstelldaches";
CM_ SG_ 1504 SAD_ToggleBit "SIL A Absicherung für die Signale: SAD_normiert, MD1_Lage, MD1_Position, SAD_Anf_ESC_Zuschaltung";
CM_ SG_ 1504 SAD_UEKB_aktiv "Anzeige aktivierter Überschusskraftbegrenzung des Schiebeausstelldaches";

CM_ SG_ 424 SARA_11_CRC "Für MLB:
'Berechnung siehe Lastenheft 'Kommunikationsabsicherung für Flexray und CAN''

Ab MQB und MLBevo:
'Berechnung siehe Lastenheft 'End-to-End Kommunikationsabsicherung'

Endwerte siehe Begleitdokument 'S-PDU Kennungsfolge'";
CM_ SG_ 424 SARA_Accel_X_r "Beschleunigung Acceleration-X routable:
- 0x0000= Sensor nicht verbaut, Signal wird nicht berechnet
- genutzter Wertebereich ± 640 m/s²

Filterung: 60 Hz Sensorfilter + 15 Hz uC-Filter (Cheby-II 3.Ordnung)";
CM_ SG_ 424 SARA_Accel_Y_r "Beschleunigung Acceleration-Y routable:
- 0x0000= Sensor nicht verbaut, Signal wird nicht berechnet
- genutzter Wertebereich ± 640 m/s²

Filterung: 60 Hz Sensorfilter + 15 Hz uC-Filter (Cheby-II 3.Ordnung)";
CM_ SG_ 424 SARA_CF_Accel_X_r "Confidence Faktor Beschleunigung Acceleration-X routable:

0=gültiger Wert
1=nicht belegt
2=nicht belegt
3=Temporärer Fehler {solange möglich werden aktuelle Sensorwerte gesendet, ansonsten 0xFFFF}
4=Init {0x8000 wird gesendet}
5=Sensor nicht verba";
CM_ SG_ 424 SARA_CF_Accel_Y_r "Confidence Faktor Beschleunigung Acceleration-Y routable:

0=gültiger Wert
1=nicht belegt
2=nicht belegt
3=Temporärer Fehler {solange möglich werden aktuelle Sensorwerte gesendet, ansonsten 0xFFFF}
4=Init {0x8000 wird gesendet}
5=Sensor nicht verba";
CM_ SG_ 424 SARA_CF_Omega_Z_r "Confidence Faktor Winkelgeschwindigkeit Omega-Z routable:

0=gültiger Wert
1=nicht belegt
2=nicht belegt
3=Temporärer Fehler {solange möglich werden aktuelle Sensorwerte gesendet, ansonsten 0xFFFF}
4=Init {0x8000 wird gesendet}
5=Sensor nicht verba";
CM_ SG_ 424 SARA_Omega_Z_r "Winkelgeschwindigkeit Omega-Z routable:
- 0x0000 = Sensor nicht verbaut, Signal wird nicht berechnet
- genutzter Wertebereich ± 320 Deg/s

Filterung: 60 Hz Sensorfilter + 15 Hz uC-Filter (Cheby-II 3.Ordnung)";

CM_ SG_ 784 SCU_02_BZ "Botschaftszaehler
Botschaft asynchron geroutet. Zählerwert kann springen.";
CM_ SG_ 784 SCU_02_CRC "Für MLB:
'Berechnung siehe Lastenheft 'Kommunikationsabsicherung für FlexRay und CAN''

Ab MQB und MLBevo:
'Berechnung siehe Lastenheft 'End-to-End Kommunikationsabsicherung''

Endwerte siehe Begleitdokument 'S-PDU Kennungsfolgen'";
CM_ SG_ 784 SCU_Charisma_FahrPr "Aktuelles Fahrprogramm des Charismateilnehmers SCU

Achtung neue Modusnamen (wie im MMI):

0x1 = Komfort = Comfort
0x2 = Dynamik = Auto
0x3 = Sport = Dynamic";
CM_ SG_ 784 SCU_Charisma_Status "Systemstatus des Charismateilnehmers SCU

Wert 0x3 ist nur für Fahrzeuge ab MQB relevant
";
CM_ SG_ 784 SCU_IL_Status "Status des Funktionsanteils Integrallenkung in der SCU";
CM_ SG_ 784 SCU_Warnungen "Warnungen der SCU";

CM_ SG_ 1522 KBI_Dimmpoti "Signal wird benötigt für Dimmung im Audi B8. Der Signalfluss erfolgt vom Kombi an das BCM1.";
CM_ SG_ 1522 KBI_Phototransistor "Signal wird benötigt für die Dimmung von Such- Funktions- und Displaybeleuchtungen. Der Signalfluss erfolgt vom Steuergerät mit Fotosensor an die jeweiligen Dimmmaster-Steuergeräte.

Für Audi B8/Q5 und D4/C7/VW526 vor PA: 
0xFE Phototransistor nicht ve";

CM_ SG_ 1363 SR3_Status_Lehne_Links "Status der Lehnenverriegelung  Links von der 3ten Sitzreihe ";
CM_ SG_ 1363 SR3_Status_Lehne_Rechts "Status der Lehnenverriegelung  Rechts von der 3ten Sitzreihe ";
BA_DEF_REL_ BU_SG_REL_  "GenSigTimeoutTime" INT 0 65535;
BA_DEF_ BO_  "DiagRequest" ENUM "No", "Yes";
BA_DEF_ BO_  "DiagResponse" ENUM "No", "Yes";
BA_DEF_ BO_  "DiagState" ENUM "No", "Yes";
BA_DEF_ BO_  "GenMsgChkConstant" HEX 0 4095;
BA_DEF_ BO_  "GenMsgCycleTime" INT 0 65535;
BA_DEF_ BO_  "GenMsgCycleTimeFast" INT 0 65535;
BA_DEF_ BO_  "GenMsgDelayTime" INT 0 100000;
BA_DEF_ BO_  "GenMsgILSupport" ENUM "No", "Yes";
BA_DEF_ BO_  "GenMsgNrOfRepetition" INT 0 100;
BA_DEF_ BO_  "GenMsgPDUConstants" STRING;
BA_DEF_ BO_  "GenMsgSendType" ENUM "Cyclic", "not_used", "not_used", "not_used", "not_used", "not_used", "not_used", "IfActive", "NoMsgSendType";
BA_DEF_ BO_  "GenMsgStartDelayTime" INT 0 100000;
BA_DEF_ BO_  "NmMessage" ENUM "No", "Yes";
BA_DEF_ BO_  "NmhMessage" ENUM "No", "Yes";
BA_DEF_ BO_  "MsgType" ENUM "Application", "NM ", "NMH", "TP2.0", "ISO-TP ", "BAP", "EID", "KS", "XCP_PRE_CONFIGURED", "XCP_RUNTIME_CONFIGURED";
BA_DEF_ BO_  "VAGTP20_API" HEX 0 255;
BA_DEF_ BO_  "VAGTP20_DynConnection" ENUM "No", "Yes";
BA_DEF_ BO_  "VAGTP20_DynSetup" ENUM "No", "Yes";
BA_DEF_ BO_  "VAGTP20_StatConnection" ENUM "No", "Yes";
BA_DEF_ SG_  "GenSigActiveRepetitions" INT -2147483648 2147483647;
BA_DEF_ SG_  "GenSigInactiveValue" INT -2147483648 2147483647;
BA_DEF_ SG_  "GenSigSendType" ENUM "Cyclic", "OnWrite", "OnWriteWithRepetition", "OnChange", "OnChangeWithRepetition", "IfActive", "IfActiveWithRepetition", "NoSigSendType", "OnChangeAndIfActive", "OnChangeAndIfActiveWithRepetition";
BA_DEF_ SG_  "GenSigStartValue" INT -2147483648 2147483647;
BA_DEF_ SG_  "NWM-WakeupAllowed" ENUM "No", "Yes";
BA_DEF_ SG_  "GenSigFuncType" ENUM "NoFunction", "MsgCounter", "CRC-8", "XOR", "XOR-2", "DatedBit", "SW-Kl15", "CHK", "Constant", "Protocol", "CRC-8-SAE_J1850", "CRC-32", "DataLength", "DataID", "MsgCounter16", "SOK-Signatur", "Cluster";
BA_DEF_ SG_  "GenSigSwitchedByIgnition" ENUM "No", "Yes";
BA_DEF_ SG_  "Fehlerwert" HEX 0 2147483647;
BA_DEF_ SG_  "GenSigMissingSourceValue" HEX 0 2147483647;
BA_DEF_DEF_REL_  "GenSigTimeoutTime" 0;
BA_DEF_DEF_  "DiagRequest" "No";
BA_DEF_DEF_  "DiagResponse" "No";
BA_DEF_DEF_  "DiagState" "No";
BA_DEF_DEF_  "GenMsgChkConstant" 0;
BA_DEF_DEF_  "GenMsgCycleTime" 0;
BA_DEF_DEF_  "GenMsgCycleTimeFast" 0;
BA_DEF_DEF_  "GenMsgDelayTime" 0;
BA_DEF_DEF_  "GenMsgILSupport" "No";
BA_DEF_DEF_  "GenMsgNrOfRepetition" 0;
BA_DEF_DEF_  "GenMsgPDUConstants" "";
BA_DEF_DEF_  "GenMsgSendType" "NoMsgSendType";
BA_DEF_DEF_  "GenMsgStartDelayTime" 0;
BA_DEF_DEF_  "NmMessage" "No";
BA_DEF_DEF_  "NmhMessage" "No";
BA_DEF_DEF_  "MsgType" "Application";
BA_DEF_DEF_  "VAGTP20_API" 0;
BA_DEF_DEF_  "VAGTP20_DynConnection" "No";
BA_DEF_DEF_  "VAGTP20_DynSetup" "No";
BA_DEF_DEF_  "VAGTP20_StatConnection" "No";
BA_DEF_DEF_  "GenSigActiveRepetitions" 0;
BA_DEF_DEF_  "GenSigInactiveValue" 0;
BA_DEF_DEF_  "GenSigSendType" "NoSigSendType";
BA_DEF_DEF_  "GenSigStartValue" 0;
BA_DEF_DEF_  "NWM-WakeupAllowed" "No";
BA_DEF_DEF_  "GenSigFuncType" "NoFunction";
BA_DEF_DEF_  "GenSigSwitchedByIgnition" "Yes";
BA_DEF_DEF_  "Fehlerwert" 0;
BA_DEF_DEF_  "GenSigMissingSourceValue" 0;
BA_ "GenMsgCycleTime" BO_ 1355 500;
BA_ "GenMsgDelayTime" BO_ 1355 20;
BA_ "GenMsgILSupport" BO_ 1355 1;
BA_ "GenMsgSendType" BO_ 1355 0;
BA_ "GenMsgCycleTime" BO_ 803 200;
BA_ "GenMsgDelayTime" BO_ 803 20;
BA_ "GenMsgILSupport" BO_ 803 1;
BA_ "GenMsgPDUConstants" BO_ 803 "0xa4,0x8b,0xda,0x66,0xdf,0x26,0xe0,0x4a,0x17,0x4d,0xbf,0xe3,0x47,0x2f,0x2a,0x06";
BA_ "GenMsgSendType" BO_ 803 0;
BA_ "GenMsgCycleTime" BO_ 2527679498 1000;
BA_ "GenMsgCycleTimeFast" BO_ 2527679498 200;
BA_ "GenMsgDelayTime" BO_ 2527679498 50;
BA_ "GenMsgILSupport" BO_ 2527679498 1;
BA_ "GenMsgNrOfRepetition" BO_ 2527679498 3;
BA_ "GenMsgSendType" BO_ 2527679498 0;
BA_ "GenMsgCycleTime" BO_ 398 100;
BA_ "GenMsgILSupport" BO_ 398 1;
BA_ "GenMsgSendType" BO_ 398 0;
BA_ "GenMsgCycleTime" BO_ 1166 100;
BA_ "GenMsgILSupport" BO_ 1166 1;
BA_ "GenMsgSendType" BO_ 1166 0;
BA_ "GenMsgCycleTime" BO_ 319 200;
BA_ "GenMsgDelayTime" BO_ 319 20;
BA_ "GenMsgILSupport" BO_ 319 1;
BA_ "GenMsgPDUConstants" BO_ 319 "0x28,0x6e,0x5a,0xc6,0x52,0x65,0x85,0xa1,0xb8,0xe6,0x38,0x88,0xf8,0xb9,0x2b,0xb0";
BA_ "GenMsgSendType" BO_ 319 0;
BA_ "GenMsgStartDelayTime" BO_ 319 15;
BA_ "GenMsgCycleTime" BO_ 1122 150;
BA_ "GenMsgILSupport" BO_ 1122 1;
BA_ "GenMsgSendType" BO_ 1122 0;
BA_ "GenMsgCycleTime" BO_ 1123 150;
BA_ "GenMsgILSupport" BO_ 1123 1;
BA_ "GenMsgSendType" BO_ 1123 0;
BA_ "GenMsgCycleTime" BO_ 1124 150;
BA_ "GenMsgILSupport" BO_ 1124 1;
BA_ "GenMsgSendType" BO_ 1124 0;
BA_ "GenMsgCycleTime" BO_ 2463978730 100;
BA_ "GenMsgILSupport" BO_ 2463978730 1;
BA_ "GenMsgSendType" BO_ 2463978730 0;
BA_ "GenMsgCycleTime" BO_ 906 100;
BA_ "GenMsgDelayTime" BO_ 906 10;
BA_ "GenMsgILSupport" BO_ 906 1;
BA_ "GenMsgPDUConstants" BO_ 906 "0xdd,0xd2,0x70,0x3d,0x04,0xcd,0x8a,0x28,0x06,0x4c,0x09,0x14,0x5b,0x22,0x86,0x4b";
BA_ "GenMsgSendType" BO_ 906 0;
BA_ "GenMsgCycleTime" BO_ 1339 500;
BA_ "GenMsgDelayTime" BO_ 1339 80;
BA_ "GenMsgILSupport" BO_ 1339 1;
BA_ "GenMsgSendType" BO_ 1339 0;
BA_ "GenMsgCycleTime" BO_ 1616 1000;
BA_ "GenMsgDelayTime" BO_ 1616 50;
BA_ "GenMsgILSupport" BO_ 1616 1;
BA_ "GenMsgSendType" BO_ 1616 0;
BA_ "GenMsgCycleTime" BO_ 1529 320;
BA_ "GenMsgILSupport" BO_ 1529 1;
BA_ "GenMsgSendType" BO_ 1529 0;
BA_ "GenMsgCycleTime" BO_ 1525 500;
BA_ "GenMsgILSupport" BO_ 1525 1;
BA_ "GenMsgSendType" BO_ 1525 0;
BA_ "GenMsgStartDelayTime" BO_ 1525 85;
BA_ "GenMsgCycleTime" BO_ 1527 500;
BA_ "GenMsgDelayTime" BO_ 1527 100;
BA_ "GenMsgILSupport" BO_ 1527 1;
BA_ "GenMsgSendType" BO_ 1527 0;
BA_ "GenMsgStartDelayTime" BO_ 1527 85;
BA_ "GenMsgCycleTime" BO_ 2527679676 500;
BA_ "GenMsgILSupport" BO_ 2527679676 1;
BA_ "GenMsgSendType" BO_ 2527679676 0;
BA_ "GenMsgStartDelayTime" BO_ 2527679676 85;
BA_ "GenMsgCycleTime" BO_ 1440 200;
BA_ "GenMsgILSupport" BO_ 1440 1;
BA_ "GenMsgSendType" BO_ 1440 0;
BA_ "GenMsgCycleTime" BO_ 2527679790 500;
BA_ "GenMsgILSupport" BO_ 2527679790 1;
BA_ "GenMsgSendType" BO_ 2527679790 0;
BA_ "GenMsgCycleTime" BO_ 1504 500;
BA_ "GenMsgCycleTimeFast" BO_ 1504 100;
BA_ "GenMsgDelayTime" BO_ 1504 50;
BA_ "GenMsgILSupport" BO_ 1504 1;
BA_ "GenMsgNrOfRepetition" BO_ 1504 5;
BA_ "GenMsgSendType" BO_ 1504 0;
BA_ "GenMsgCycleTime" BO_ 424 20;
BA_ "GenMsgILSupport" BO_ 424 1;
BA_ "GenMsgPDUConstants" BO_ 424 "0x11,0x17,0xbb,0xaa,0xd0,0x83,0xe1,0x8e,0xa3,0x4d,0xef,0x50,0x88,0xa5,0x22,0xf6";
BA_ "GenMsgSendType" BO_ 424 0;
BA_ "GenMsgCycleTime" BO_ 784 120;
BA_ "GenMsgDelayTime" BO_ 784 40;
BA_ "GenMsgILSupport" BO_ 784 1;
BA_ "GenMsgPDUConstants" BO_ 784 "0x39,0x5d,0x40,0x87,0x41,0xf4,0x1e,0x19,0xd6,0x91,0xe0,0xdd,0x7b,0xf3,0x74,0x30";
BA_ "GenMsgSendType" BO_ 784 0;
BA_ "GenMsgCycleTime" BO_ 1522 200;
BA_ "GenMsgDelayTime" BO_ 1522 50;
BA_ "GenMsgILSupport" BO_ 1522 1;
BA_ "GenMsgSendType" BO_ 1522 0;
BA_ "GenMsgCycleTime" BO_ 1363 100;
BA_ "GenMsgILSupport" BO_ 1363 1;
BA_ "GenMsgSendType" BO_ 1363 0;
BA_ "GenSigSendType" SG_ 1355 BCM_WAH_Meldung 3;
BA_ "GenSigSendType" SG_ 1355 PDC_Charisma_FahrPr 3;
BA_ "GenSigSendType" SG_ 1355 PDC_Charisma_Status 3;
BA_ "GenSigSendType" SG_ 1355 PH_Aufschaltursache 3;
BA_ "GenSigSendType" SG_ 1355 PH_Ton_Ausgabe 3;
BA_ "Fehlerwert" SG_ 1355 PH_Ton_Ausgabe 7;
BA_ "GenSigSendType" SG_ 1355 PH_Ton_Lautstaerke 3;
BA_ "GenSigSendType" SG_ 1355 PH_Ton_Pausenlaenge 3;
BA_ "Fehlerwert" SG_ 1355 PH_Ton_Pausenlaenge 127;
BA_ "GenSigSendType" SG_ 1355 PH_Ton_Richtung 3;
BA_ "GenSigSendType" SG_ 1355 PH_Verschmutzungsmeldung 3;
BA_ "GenSigSendType" SG_ 803 PCF_01_BZ 0;
BA_ "GenSigFuncType" SG_ 803 PCF_01_BZ 1;
BA_ "GenSigSendType" SG_ 803 PCF_01_CRC 0;
BA_ "GenSigFuncType" SG_ 803 PCF_01_CRC 2;
BA_ "GenSigSendType" SG_ 803 PCF_HBA_Param 0;
BA_ "GenSigSwitchedByIgnition" SG_ 803 PCF_HBA_Param 0;
BA_ "GenSigSendType" SG_ 803 PCF_Prefill_Anf 0;
BA_ "GenSigSwitchedByIgnition" SG_ 803 PCF_Prefill_Anf 0;
BA_ "GenSigSendType" SG_ 803 PCF_Ruckprofil 0;
BA_ "GenSigSwitchedByIgnition" SG_ 803 PCF_Ruckprofil 0;
BA_ "GenSigSendType" SG_ 803 PCF_Verz_Anf 0;
BA_ "GenSigStartValue" SG_ 803 PCF_Verz_Anf 834;
BA_ "GenSigSendType" SG_ 803 PCF_Verz_Anf_ASIL 0;
BA_ "GenSigSwitchedByIgnition" SG_ 803 PCF_Verz_Anf_ASIL 0;
BA_ "GenSigSendType" SG_ 803 PCF_Verz_Auspraegung 0;
BA_ "GenSigSwitchedByIgnition" SG_ 803 PCF_Verz_Auspraegung 0;
BA_ "GenSigSendType" SG_ 803 PCF_Verz_Info 0;
BA_ "GenSigSwitchedByIgnition" SG_ 803 PCF_Verz_Info 0;
BA_ "GenSigSendType" SG_ 803 SC_AbstWarn_Texte 3;
BA_ "GenSigSwitchedByIgnition" SG_ 803 SC_AbstWarn_Texte 0;
BA_ "GenSigSendType" SG_ 803 SC_WarnBrems_Texte 3;
BA_ "GenSigSwitchedByIgnition" SG_ 803 SC_WarnBrems_Texte 0;
BA_ "GenSigSendType" SG_ 2527679498 IAA_Active_User_ID 0;
BA_ "GenSigSwitchedByIgnition" SG_ 2527679498 IAA_Active_User_ID 0;
BA_ "GenSigSendType" SG_ 2527679498 IAA_Identified_User_ID 0;
BA_ "GenSigSwitchedByIgnition" SG_ 2527679498 IAA_Identified_User_ID 0;
BA_ "GenSigSendType" SG_ 2527679498 IAA_PSO_wake_up 0;
BA_ "GenSigSwitchedByIgnition" SG_ 2527679498 IAA_PSO_wake_up 0;
BA_ "GenSigActiveRepetitions" SG_ 2527679498 Perso_Aktiv 3;
BA_ "GenSigSendType" SG_ 2527679498 Perso_Aktiv 4;
BA_ "GenSigSwitchedByIgnition" SG_ 2527679498 Perso_Aktiv 0;
BA_ "GenSigActiveRepetitions" SG_ 2527679498 Perso_Bedienstelle 3;
BA_ "GenSigSendType" SG_ 2527679498 Perso_Bedienstelle 4;
BA_ "GenSigSwitchedByIgnition" SG_ 2527679498 Perso_Bedienstelle 0;
BA_ "GenSigActiveRepetitions" SG_ 2527679498 Perso_Fahrernummer 3;
BA_ "GenSigSendType" SG_ 2527679498 Perso_Fahrernummer 4;
BA_ "GenSigSwitchedByIgnition" SG_ 2527679498 Perso_Fahrernummer 0;
BA_ "GenSigActiveRepetitions" SG_ 2527679498 Perso_Freigabe_Verstellung 3;
BA_ "GenSigSendType" SG_ 2527679498 Perso_Freigabe_Verstellung 4;
BA_ "GenSigSwitchedByIgnition" SG_ 2527679498 Perso_Freigabe_Verstellung 0;
BA_ "GenSigActiveRepetitions" SG_ 2527679498 Perso_Kontonummer 3;
BA_ "GenSigSendType" SG_ 2527679498 Perso_Kontonummer 4;
BA_ "GenSigSwitchedByIgnition" SG_ 2527679498 Perso_Kontonummer 0;
BA_ "GenSigActiveRepetitions" SG_ 2527679498 Perso_Schreibschutz 3;
BA_ "GenSigSendType" SG_ 2527679498 Perso_Schreibschutz 4;
BA_ "GenSigSwitchedByIgnition" SG_ 2527679498 Perso_Schreibschutz 0;
BA_ "GenSigSendType" SG_ 2527679498 Perso_Status 1;
BA_ "GenSigSwitchedByIgnition" SG_ 2527679498 Perso_Status 0;
BA_ "GenSigActiveRepetitions" SG_ 2527679498 Perso_Steuerung 3;
BA_ "GenSigSendType" SG_ 2527679498 Perso_Steuerung 4;
BA_ "GenSigSwitchedByIgnition" SG_ 2527679498 Perso_Steuerung 0;
BA_ "GenSigActiveRepetitions" SG_ 2527679498 Perso_Steuerungsparameter 3;
BA_ "GenSigSendType" SG_ 2527679498 Perso_Steuerungsparameter 4;
BA_ "GenSigSwitchedByIgnition" SG_ 2527679498 Perso_Steuerungsparameter 0;
BA_ "GenSigSendType" SG_ 398 PLA2_Anf_Akustik 0;
BA_ "GenSigSwitchedByIgnition" SG_ 398 PLA2_Anf_Akustik 0;
BA_ "GenSigSendType" SG_ 398 PLA2_Anf_Anzeige_Bremsfuss 0;
BA_ "GenSigSwitchedByIgnition" SG_ 398 PLA2_Anf_Anzeige_Bremsfuss 0;
BA_ "GenSigSendType" SG_ 398 PLA2_Anf_Anzeige_Mini 0;
BA_ "GenSigSwitchedByIgnition" SG_ 398 PLA2_Anf_Anzeige_Mini 0;
BA_ "GenSigSendType" SG_ 398 PLA2_Anf_Anzeige_Schwellpfeil 0;
BA_ "GenSigSwitchedByIgnition" SG_ 398 PLA2_Anf_Anzeige_Schwellpfeil 0;
BA_ "GenSigSendType" SG_ 398 PLA2_Anf_Anzeigemodus 0;
BA_ "GenSigSwitchedByIgnition" SG_ 398 PLA2_Anf_Anzeigemodus 0;
BA_ "GenSigSendType" SG_ 398 PLA2_Anf_Meldungen 0;
BA_ "GenSigSwitchedByIgnition" SG_ 398 PLA2_Anf_Meldungen 0;
BA_ "GenSigSendType" SG_ 398 PLA2_Anf_Meldungen_FA 0;
BA_ "GenSigSwitchedByIgnition" SG_ 398 PLA2_Anf_Meldungen_FA 0;
BA_ "GenSigSendType" SG_ 398 PLA2_Anf_Meldungen_MA 0;
BA_ "GenSigSwitchedByIgnition" SG_ 398 PLA2_Anf_Meldungen_MA 0;
BA_ "GenSigSendType" SG_ 398 PLA2_Anzahl_Seg_Schwellpfeil 0;
BA_ "GenSigSwitchedByIgnition" SG_ 398 PLA2_Anzahl_Seg_Schwellpfeil 0;
BA_ "GenSigSendType" SG_ 398 PLA2_Mini_Modus 0;
BA_ "GenSigSwitchedByIgnition" SG_ 398 PLA2_Mini_Modus 0;
BA_ "GenSigSendType" SG_ 398 PLA2_Status_Aktive_Seite 0;
BA_ "GenSigSwitchedByIgnition" SG_ 398 PLA2_Status_Aktive_Seite 0;
BA_ "GenSigSendType" SG_ 398 PLA2_Status_Funktion 0;
BA_ "GenSigSwitchedByIgnition" SG_ 398 PLA2_Status_Funktion 0;
BA_ "GenSigSendType" SG_ 1166 PLA_Anf_Akustik 0;
BA_ "GenSigSendType" SG_ 1166 PLA_Anf_Anzeige_Bremsfuss 0;
BA_ "GenSigSendType" SG_ 1166 PLA_Anf_Anzeige_Mini 0;
BA_ "GenSigSendType" SG_ 1166 PLA_Anf_Anzeige_Schwellpfeil 0;
BA_ "GenSigSendType" SG_ 1166 PLA_Anf_Anzeigemodus 0;
BA_ "GenSigSendType" SG_ 1166 PLA_Anf_Meldungen 0;
BA_ "GenSigSendType" SG_ 1166 PLA_Anforderung_HMS 0;
BA_ "GenSigSendType" SG_ 1166 PLA_Anzahl_Segmente_Schwellpfeil 0;
BA_ "GenSigSendType" SG_ 1166 PLA_Mini_Modus 0;
BA_ "GenSigSendType" SG_ 1166 PLA_Status_Aktive_Seite 0;
BA_ "GenSigSendType" SG_ 1166 PLA_Status_beenden_Mini 0;
BA_ "GenSigSendType" SG_ 1166 PLA_Status_Funktion 0;
BA_ "GenSigSendType" SG_ 1166 PLA_Status_Laengsparken_Mini 0;
BA_ "GenSigSendType" SG_ 1166 PLA_Status_QP_Rueckw_Mini 0;
BA_ "GenSigSendType" SG_ 1166 PLA_Status_QP_Vorw_Mini 0;
BA_ "GenSigSendType" SG_ 319 PreCrash_02_BZ 0;
BA_ "GenSigFuncType" SG_ 319 PreCrash_02_BZ 1;
BA_ "GenSigSendType" SG_ 319 PreCrash_02_CRC 0;
BA_ "GenSigFuncType" SG_ 319 PreCrash_02_CRC 2;
BA_ "GenSigSendType" SG_ 319 PreCrash_Anforderung_AFR 3;
BA_ "GenSigStartValue" SG_ 319 PreCrash_Anforderung_AFR 7;
BA_ "GenSigSwitchedByIgnition" SG_ 319 PreCrash_Anforderung_AFR 0;
BA_ "GenSigSendType" SG_ 319 PreCrash_BFS_KSV_verfahren 3;
BA_ "GenSigSwitchedByIgnition" SG_ 319 PreCrash_BFS_KSV_verfahren 0;
BA_ "GenSigSendType" SG_ 319 PreCrash_BFS_Pneumatik_ansteuern 3;
BA_ "GenSigSwitchedByIgnition" SG_ 319 PreCrash_BFS_Pneumatik_ansteuern 0;
BA_ "GenSigSendType" SG_ 319 PreCrash_BFS_Sitzlehne_verfahren 3;
BA_ "GenSigSwitchedByIgnition" SG_ 319 PreCrash_BFS_Sitzlehne_verfahren 0;
BA_ "GenSigSendType" SG_ 319 PreCrash_Blinken 3;
BA_ "GenSigSendType" SG_ 319 PreCrash_Charisma_FahrPr 0;
BA_ "GenSigSendType" SG_ 319 PreCrash_Charisma_Status 0;
BA_ "GenSigSendType" SG_ 319 PreCrash_Fenster_schliessen 3;
BA_ "GenSigSendType" SG_ 319 PreCrash_Fo_KSV_verfahren 3;
BA_ "GenSigSwitchedByIgnition" SG_ 319 PreCrash_Fo_KSV_verfahren 0;
BA_ "GenSigSendType" SG_ 319 PreCrash_Fo_Pneumatik_ansteuern 3;
BA_ "GenSigSwitchedByIgnition" SG_ 319 PreCrash_Fo_Pneumatik_ansteuern 0;
BA_ "GenSigSendType" SG_ 319 PreCrash_Fo_Sitzlehne_verfahren 3;
BA_ "GenSigSwitchedByIgnition" SG_ 319 PreCrash_Fo_Sitzlehne_verfahren 0;
BA_ "GenSigSendType" SG_ 319 PreCrash_FS_KSV_verfahren 3;
BA_ "GenSigSwitchedByIgnition" SG_ 319 PreCrash_FS_KSV_verfahren 0;
BA_ "GenSigSendType" SG_ 319 PreCrash_FS_Pneumatik_ansteuern 3;
BA_ "GenSigSwitchedByIgnition" SG_ 319 PreCrash_FS_Pneumatik_ansteuern 0;
BA_ "GenSigSendType" SG_ 319 PreCrash_FS_Sitzlehne_verfahren 3;
BA_ "GenSigSwitchedByIgnition" SG_ 319 PreCrash_FS_Sitzlehne_verfahren 0;
BA_ "GenSigSendType" SG_ 319 PreCrash_Schiebedach_schliessen 3;
BA_ "GenSigSendType" SG_ 319 PreCrash_Tueren_Verriegeln 3;
BA_ "GenSigSwitchedByIgnition" SG_ 319 PreCrash_Tueren_Verriegeln 0;
BA_ "GenSigSendType" SG_ 319 SC_PreCrash_LED 3;
BA_ "GenSigSwitchedByIgnition" SG_ 319 SC_PreCrash_LED 0;
BA_ "GenSigSendType" SG_ 319 SC_PreCrash_Texte 3;
BA_ "GenSigSwitchedByIgnition" SG_ 319 SC_PreCrash_Texte 0;
BA_ "GenSigSendType" SG_ 319 SC_PreCrash_Warnung 3;
BA_ "GenSigSwitchedByIgnition" SG_ 319 SC_PreCrash_Warnung 0;
BA_ "GenSigSendType" SG_ 319 SC_PreSense_FCWP 3;
BA_ "GenSigSwitchedByIgnition" SG_ 319 SC_PreSense_FCWP 0;
BA_ "GenSigSendType" SG_ 1122 PSD_Abzweigerichtung 0;
BA_ "GenSigSwitchedByIgnition" SG_ 1122 PSD_Abzweigerichtung 0;
BA_ "GenSigSendType" SG_ 1122 PSD_Abzweigewinkel 0;
BA_ "GenSigSwitchedByIgnition" SG_ 1122 PSD_Abzweigewinkel 0;
BA_ "GenSigSendType" SG_ 1122 PSD_ADAS_Qualitaet 0;
BA_ "GenSigSendType" SG_ 1122 PSD_Anfangskruemmung 0;
BA_ "GenSigSwitchedByIgnition" SG_ 1122 PSD_Anfangskruemmung 0;
BA_ "GenSigSendType" SG_ 1122 PSD_Anfangskruemmung_Vorz 0;
BA_ "GenSigSwitchedByIgnition" SG_ 1122 PSD_Anfangskruemmung_Vorz 0;
BA_ "GenSigSendType" SG_ 1122 PSD_Bebauung 0;
BA_ "GenSigSendType" SG_ 1122 PSD_Endkruemmung 0;
BA_ "GenSigSendType" SG_ 1122 PSD_Endkruemmung_Vorz 0;
BA_ "GenSigSendType" SG_ 1122 PSD_Fahrspuren_Anzahl 0;
BA_ "GenSigStartValue" SG_ 1122 PSD_Fahrspuren_Anzahl 1;
BA_ "GenSigSwitchedByIgnition" SG_ 1122 PSD_Fahrspuren_Anzahl 0;
BA_ "GenSigSendType" SG_ 1122 PSD_Geradester_Pfad 0;
BA_ "GenSigSendType" SG_ 1122 PSD_Idenditaets_ID 0;
BA_ "Fehlerwert" SG_ 1122 PSD_Idenditaets_ID 1;
BA_ "GenSigSendType" SG_ 1122 PSD_Rampe 0;
BA_ "GenSigSendType" SG_ 1122 PSD_Segment_ID 0;
BA_ "GenSigSendType" SG_ 1122 PSD_Segment_Komplett 0;
BA_ "GenSigSwitchedByIgnition" SG_ 1122 PSD_Segment_Komplett 0;
BA_ "GenSigSendType" SG_ 1122 PSD_Segmentlaenge 0;
BA_ "GenSigSendType" SG_ 1122 PSD_Strassenkategorie 0;
BA_ "GenSigStartValue" SG_ 1122 PSD_Strassenkategorie 7;
BA_ "GenSigSwitchedByIgnition" SG_ 1122 PSD_Strassenkategorie 0;
BA_ "GenSigSendType" SG_ 1122 PSD_Vorgaenger_Segment_ID 0;
BA_ "GenSigSendType" SG_ 1122 PSD_wahrscheinlichster_Pfad 0;
BA_ "GenSigSendType" SG_ 1123 PSD_Attribut_1_ID 0;
BA_ "GenSigSendType" SG_ 1123 PSD_Attribut_1_Offset 0;
BA_ "GenSigSendType" SG_ 1123 PSD_Attribut_1_Wert 0;
BA_ "GenSigSendType" SG_ 1123 PSD_Attribut_2_ID 0;
BA_ "GenSigSendType" SG_ 1123 PSD_Attribut_2_Offset 0;
BA_ "GenSigSendType" SG_ 1123 PSD_Attribut_2_Wert 0;
BA_ "GenSigSendType" SG_ 1123 PSD_Attribut_Segment_ID_05 0;
BA_ "Fehlerwert" SG_ 1123 PSD_Attribut_Segment_ID_05 1;
BA_ "GenSigSendType" SG_ 1123 PSD_Attribute_Komplett_05 0;
BA_ "GenSigSendType" SG_ 1123 PSD_Pos_Fahrspur 0;
BA_ "GenSigSendType" SG_ 1123 PSD_Pos_Fehler_Laengsrichtung 0;
BA_ "GenSigSendType" SG_ 1123 PSD_Pos_Inhibitzeit 0;
BA_ "GenSigSendType" SG_ 1123 PSD_Pos_Segment_ID 0;
BA_ "GenSigSendType" SG_ 1123 PSD_Pos_Segmentlaenge 0;
BA_ "GenSigSendType" SG_ 1123 PSD_Pos_Standort_Eindeutig 0;
BA_ "GenSigSwitchedByIgnition" SG_ 1123 PSD_Pos_Standort_Eindeutig 0;
BA_ "GenSigSendType" SG_ 1124 PSD_06_Mux 0;
BA_ "NWM-WakeupAllowed" SG_ 1124 PSD_06_Mux 1;
BA_ "GenSigSwitchedByIgnition" SG_ 1124 PSD_06_Mux 0;
BA_ "Fehlerwert" SG_ 1124 PSD_Attribut_Segment_ID 1;
BA_ "GenSigSwitchedByIgnition" SG_ 1124 PSD_Attribute_Komplett_06 0;
BA_ "GenSigStartValue" SG_ 1124 PSD_Ges_Typ 3;
BA_ "GenSigSwitchedByIgnition" SG_ 1124 PSD_Ges_Typ 0;
BA_ "GenSigSwitchedByIgnition" SG_ 1124 PSD_Steigung_1_Attribute_kompl 0;
BA_ "Fehlerwert" SG_ 1124 PSD_Steigung_1_Segment_ID 1;
BA_ "GenSigSwitchedByIgnition" SG_ 1124 PSD_Steigung_2_Attribute_kompl 0;
BA_ "Fehlerwert" SG_ 1124 PSD_Steigung_2_Segment_ID 1;
BA_ "GenSigSendType" SG_ 2463978730 pVS_Hinweismeldung 0;
BA_ "GenSigSwitchedByIgnition" SG_ 2463978730 pVS_Hinweismeldung 0;
BA_ "GenSigSendType" SG_ 2463978730 pVS_IconActivation 0;
BA_ "GenSigSwitchedByIgnition" SG_ 2463978730 pVS_IconActivation 0;
BA_ "GenSigSendType" SG_ 2463978730 pVS_Note_SpeedAdjustment 0;
BA_ "GenSigSwitchedByIgnition" SG_ 2463978730 pVS_Note_SpeedAdjustment 0;
BA_ "GenSigSendType" SG_ 2463978730 pVS_vLimit_HMI 0;
BA_ "GenSigStartValue" SG_ 2463978730 pVS_vLimit_HMI 31;
BA_ "GenSigSwitchedByIgnition" SG_ 2463978730 pVS_vLimit_HMI 0;
BA_ "GenSigSendType" SG_ 2463978730 pVS_vLimit_HMI_Unit 0;
BA_ "GenSigSwitchedByIgnition" SG_ 2463978730 pVS_vLimit_HMI_Unit 0;
BA_ "GenSigSendType" SG_ 2463978730 pVS_vLimit_Range 0;
BA_ "GenSigStartValue" SG_ 2463978730 pVS_vLimit_Range 1022;
BA_ "Fehlerwert" SG_ 2463978730 pVS_vLimit_Range 1023;
BA_ "GenSigSendType" SG_ 2463978730 pVS_vLimit_Range_HMI 0;
BA_ "GenSigStartValue" SG_ 2463978730 pVS_vLimit_Range_HMI 1022;
BA_ "Fehlerwert" SG_ 2463978730 pVS_vLimit_Range_HMI 1023;
BA_ "GenSigSendType" SG_ 2463978730 pVS_vLimit_Range_pers 0;
BA_ "GenSigStartValue" SG_ 2463978730 pVS_vLimit_Range_pers 1022;
BA_ "Fehlerwert" SG_ 2463978730 pVS_vLimit_Range_pers 1023;
BA_ "GenSigSendType" SG_ 906 QSP_03_BZ 0;
BA_ "GenSigFuncType" SG_ 906 QSP_03_BZ 1;
BA_ "GenSigSendType" SG_ 906 QSP_03_CRC 0;
BA_ "GenSigFuncType" SG_ 906 QSP_03_CRC 2;
BA_ "GenSigSendType" SG_ 906 QSP_Init 0;
BA_ "GenSigStartValue" SG_ 906 QSP_Init 1;
BA_ "GenSigSendType" SG_ 906 QSP_Ist_Moment 0;
BA_ "GenSigStartValue" SG_ 906 QSP_Ist_Moment 511;
BA_ "Fehlerwert" SG_ 906 QSP_Ist_Moment 1023;
BA_ "GenSigSendType" SG_ 906 QSP_Status 0;
BA_ "GenSigStartValue" SG_ 906 QSP_Status 1;
BA_ "GenSigSendType" SG_ 906 QSP_Temperatur_Oel 0;
BA_ "Fehlerwert" SG_ 906 QSP_Temperatur_Oel 127;
BA_ "GenSigSendType" SG_ 906 QSP_Thermische_Belastung 0;
BA_ "Fehlerwert" SG_ 906 QSP_Thermische_Belastung 63;
BA_ "GenSigSendType" SG_ 906 QSP_Warnlampe 3;
BA_ "GenSigSendType" SG_ 1339 QS_Charisma_FahrPr 0;
BA_ "GenSigSendType" SG_ 1339 QS_Charisma_Status 0;
BA_ "GenSigSendType" SG_ 1339 QS_Symbol_Rear_Lock 0;
BA_ "GenSigSwitchedByIgnition" SG_ 1339 QS_Symbol_Rear_Lock 0;
BA_ "GenSigSendType" SG_ 1339 QS_Warntexte 3;
BA_ "GenSigSwitchedByIgnition" SG_ 1339 QS_Warntexte 0;
BA_ "GenSigSendType" SG_ 1616 RA_AM_Tuning 3;
BA_ "GenSigSwitchedByIgnition" SG_ 1616 RA_AM_Tuning 0;
BA_ "GenSigSendType" SG_ 1616 RA_Frequency 3;
BA_ "GenSigSwitchedByIgnition" SG_ 1616 RA_Frequency 0;
BA_ "GenSigSendType" SG_ 1616 RA_Frequency_unit 3;
BA_ "GenSigSwitchedByIgnition" SG_ 1616 RA_Frequency_unit 0;
BA_ "GenSigSendType" SG_ 1616 RA_PowerAmpOn 3;
BA_ "GenSigSwitchedByIgnition" SG_ 1616 RA_PowerAmpOn 0;
BA_ "GenSigSendType" SG_ 1616 RA_Radio_Error_Flag 3;
BA_ "GenSigSwitchedByIgnition" SG_ 1616 RA_Radio_Error_Flag 0;
BA_ "GenSigSendType" SG_ 1616 RA_Radio_mute 3;
BA_ "GenSigSwitchedByIgnition" SG_ 1616 RA_Radio_mute 0;
BA_ "GenSigSendType" SG_ 1616 RA_Radio_on 3;
BA_ "GenSigSwitchedByIgnition" SG_ 1616 RA_Radio_on 0;
BA_ "GenSigSendType" SG_ 1616 RA_Radio_Surround 3;
BA_ "GenSigSwitchedByIgnition" SG_ 1616 RA_Radio_Surround 0;
BA_ "GenSigSendType" SG_ 1616 RA_VNC_OFF 3;
BA_ "GenSigSwitchedByIgnition" SG_ 1616 RA_VNC_OFF 0;
BA_ "GenSigSendType" SG_ 1529 RDK_angelernt 0;
BA_ "GenSigSwitchedByIgnition" SG_ 1529 RDK_angelernt 0;
BA_ "GenSigSendType" SG_ 1529 RDK_FMVSS138_Lampe 0;
BA_ "GenSigSwitchedByIgnition" SG_ 1529 RDK_FMVSS138_Lampe 0;
BA_ "GenSigSendType" SG_ 1529 RDK_FMVSS138_MIL 0;
BA_ "GenSigSwitchedByIgnition" SG_ 1529 RDK_FMVSS138_MIL 0;
BA_ "GenSigSendType" SG_ 1529 RDK_Kalibrierung 0;
BA_ "GenSigSwitchedByIgnition" SG_ 1529 RDK_Kalibrierung 0;
BA_ "GenSigSendType" SG_ 1529 RDK_Reifendruck_Lampe 0;
BA_ "GenSigSwitchedByIgnition" SG_ 1529 RDK_Reifendruck_Lampe 0;
BA_ "GenSigSendType" SG_ 1529 RDK_Reifentemperatur_Lampe 0;
BA_ "GenSigSwitchedByIgnition" SG_ 1529 RDK_Reifentemperatur_Lampe 0;
BA_ "GenSigSendType" SG_ 1529 RDK_RS_aktiv 0;
BA_ "GenSigSwitchedByIgnition" SG_ 1529 RDK_RS_aktiv 0;
BA_ "GenSigSendType" SG_ 1529 RDK_Text_7 0;
BA_ "GenSigSwitchedByIgnition" SG_ 1529 RDK_Text_7 0;
BA_ "GenSigSendType" SG_ 1529 RDK_W_1_Reifen_HL 0;
BA_ "GenSigSwitchedByIgnition" SG_ 1529 RDK_W_1_Reifen_HL 0;
BA_ "GenSigSendType" SG_ 1529 RDK_W_1_Reifen_HR 0;
BA_ "GenSigSwitchedByIgnition" SG_ 1529 RDK_W_1_Reifen_HR 0;
BA_ "GenSigSendType" SG_ 1529 RDK_W_1_Reifen_VL 0;
BA_ "GenSigSwitchedByIgnition" SG_ 1529 RDK_W_1_Reifen_VL 0;
BA_ "GenSigSendType" SG_ 1529 RDK_W_1_Reifen_VR 0;
BA_ "GenSigSwitchedByIgnition" SG_ 1529 RDK_W_1_Reifen_VR 0;
BA_ "GenSigSendType" SG_ 1529 RDK_W_2_Reifen_HL 0;
BA_ "GenSigSwitchedByIgnition" SG_ 1529 RDK_W_2_Reifen_HL 0;
BA_ "GenSigSendType" SG_ 1529 RDK_W_2_Reifen_HR 0;
BA_ "GenSigSwitchedByIgnition" SG_ 1529 RDK_W_2_Reifen_HR 0;
BA_ "GenSigSendType" SG_ 1529 RDK_W_2_Reifen_VL 0;
BA_ "GenSigSwitchedByIgnition" SG_ 1529 RDK_W_2_Reifen_VL 0;
BA_ "GenSigSendType" SG_ 1529 RDK_W_2_Reifen_VR 0;
BA_ "GenSigSwitchedByIgnition" SG_ 1529 RDK_W_2_Reifen_VR 0;
BA_ "GenSigSendType" SG_ 1529 RDK_Warnungen_02 0;
BA_ "GenSigSwitchedByIgnition" SG_ 1529 RDK_Warnungen_02 0;
BA_ "GenSigSendType" SG_ 1525 RW_Gesamt_Reichweite 0;
BA_ "GenSigSwitchedByIgnition" SG_ 1525 RW_Gesamt_Reichweite 0;
BA_ "Fehlerwert" SG_ 1525 RW_Gesamt_Reichweite 2047;
BA_ "GenSigSendType" SG_ 1525 RW_Gesamt_Reichweite_Max_Anzeige 0;
BA_ "GenSigStartValue" SG_ 1525 RW_Gesamt_Reichweite_Max_Anzeige 2046;
BA_ "GenSigSwitchedByIgnition" SG_ 1525 RW_Gesamt_Reichweite_Max_Anzeige 0;
BA_ "Fehlerwert" SG_ 1525 RW_Gesamt_Reichweite_Max_Anzeige 2047;
BA_ "GenSigSendType" SG_ 1525 RW_Prim_Reichweitenv_Einheit 0;
BA_ "GenSigStartValue" SG_ 1525 RW_Prim_Reichweitenv_Einheit 3;
BA_ "GenSigSwitchedByIgnition" SG_ 1525 RW_Prim_Reichweitenv_Einheit 0;
BA_ "GenSigSendType" SG_ 1525 RW_Prim_Reichweitenverbrauch 0;
BA_ "GenSigStartValue" SG_ 1525 RW_Prim_Reichweitenverbrauch 2047;
BA_ "GenSigSwitchedByIgnition" SG_ 1525 RW_Prim_Reichweitenverbrauch 0;
BA_ "GenSigSendType" SG_ 1525 RW_Primaer_Reichweite 0;
BA_ "GenSigStartValue" SG_ 1525 RW_Primaer_Reichweite 2046;
BA_ "GenSigSwitchedByIgnition" SG_ 1525 RW_Primaer_Reichweite 0;
BA_ "Fehlerwert" SG_ 1525 RW_Primaer_Reichweite 2047;
BA_ "GenSigSendType" SG_ 1525 RW_Reservewarnung_2_aktiv 0;
BA_ "GenSigSwitchedByIgnition" SG_ 1525 RW_Reservewarnung_2_aktiv 0;
BA_ "GenSigSendType" SG_ 1525 RW_RWDS_Lastprofil 0;
BA_ "GenSigStartValue" SG_ 1525 RW_RWDS_Lastprofil 2046;
BA_ "GenSigSwitchedByIgnition" SG_ 1525 RW_RWDS_Lastprofil 0;
BA_ "Fehlerwert" SG_ 1525 RW_RWDS_Lastprofil 2047;
BA_ "GenSigSendType" SG_ 1527 RW_Gesamt_Reichweite_Anzeige 0;
BA_ "GenSigStartValue" SG_ 1527 RW_Gesamt_Reichweite_Anzeige 2046;
BA_ "GenSigSwitchedByIgnition" SG_ 1527 RW_Gesamt_Reichweite_Anzeige 0;
BA_ "Fehlerwert" SG_ 1527 RW_Gesamt_Reichweite_Anzeige 2047;
BA_ "GenSigSendType" SG_ 1527 RW_Primaer_Reichweite_Anzeige 0;
BA_ "GenSigStartValue" SG_ 1527 RW_Primaer_Reichweite_Anzeige 2046;
BA_ "GenSigSwitchedByIgnition" SG_ 1527 RW_Primaer_Reichweite_Anzeige 0;
BA_ "Fehlerwert" SG_ 1527 RW_Primaer_Reichweite_Anzeige 2047;
BA_ "GenSigSendType" SG_ 1527 RW_Reichweite_Einheit_Anzeige 0;
BA_ "GenSigSwitchedByIgnition" SG_ 1527 RW_Reichweite_Einheit_Anzeige 0;
BA_ "GenSigSendType" SG_ 1527 RW_Reservewarnung_aktiv 0;
BA_ "GenSigSwitchedByIgnition" SG_ 1527 RW_Reservewarnung_aktiv 0;
BA_ "GenSigSendType" SG_ 1527 RW_Sek_Reichweitenv_Einheit 0;
BA_ "GenSigStartValue" SG_ 1527 RW_Sek_Reichweitenv_Einheit 3;
BA_ "GenSigSwitchedByIgnition" SG_ 1527 RW_Sek_Reichweitenv_Einheit 0;
BA_ "GenSigSendType" SG_ 1527 RW_Sek_Reichweitenverbrauch 0;
BA_ "GenSigStartValue" SG_ 1527 RW_Sek_Reichweitenverbrauch 2047;
BA_ "GenSigSwitchedByIgnition" SG_ 1527 RW_Sek_Reichweitenverbrauch 0;
BA_ "GenSigSendType" SG_ 1527 RW_Sekundaer_Reichweite 0;
BA_ "GenSigStartValue" SG_ 1527 RW_Sekundaer_Reichweite 2046;
BA_ "GenSigSwitchedByIgnition" SG_ 1527 RW_Sekundaer_Reichweite 0;
BA_ "Fehlerwert" SG_ 1527 RW_Sekundaer_Reichweite 2047;
BA_ "GenSigSendType" SG_ 1527 RW_Sekundaer_Reichweite_Anzeige 0;
BA_ "GenSigStartValue" SG_ 1527 RW_Sekundaer_Reichweite_Anzeige 2046;
BA_ "GenSigSwitchedByIgnition" SG_ 1527 RW_Sekundaer_Reichweite_Anzeige 0;
BA_ "Fehlerwert" SG_ 1527 RW_Sekundaer_Reichweite_Anzeige 2047;
BA_ "GenSigSendType" SG_ 1527 RW_Tendenz 0;
BA_ "GenSigSwitchedByIgnition" SG_ 1527 RW_Tendenz 0;
BA_ "GenSigSendType" SG_ 1527 RW_Texte 3;
BA_ "GenSigSwitchedByIgnition" SG_ 1527 RW_Texte 0;
BA_ "GenSigSendType" SG_ 2527679676 RW_Prim_rRWB_aktiv 0;
BA_ "GenSigStartValue" SG_ 2527679676 RW_Prim_rRWB_aktiv 3;
BA_ "GenSigSwitchedByIgnition" SG_ 2527679676 RW_Prim_rRWB_aktiv 0;
BA_ "GenSigSendType" SG_ 2527679676 RW_Prim_rRWB_Reichw_Anz 0;
BA_ "GenSigStartValue" SG_ 2527679676 RW_Prim_rRWB_Reichw_Anz 2046;
BA_ "GenSigSwitchedByIgnition" SG_ 2527679676 RW_Prim_rRWB_Reichw_Anz 0;
BA_ "Fehlerwert" SG_ 2527679676 RW_Prim_rRWB_Reichw_Anz 2047;
BA_ "GenSigSendType" SG_ 2527679676 RW_Prim_rRWB_Reichw_Gesamt_Anz 0;
BA_ "GenSigStartValue" SG_ 2527679676 RW_Prim_rRWB_Reichw_Gesamt_Anz 2046;
BA_ "GenSigSwitchedByIgnition" SG_ 2527679676 RW_Prim_rRWB_Reichw_Gesamt_Anz 0;
BA_ "Fehlerwert" SG_ 2527679676 RW_Prim_rRWB_Reichw_Gesamt_Anz 2047;
BA_ "GenSigSendType" SG_ 2527679676 RW_Prim_rRWB_Reichw_Max_Ges_Anz 0;
BA_ "GenSigStartValue" SG_ 2527679676 RW_Prim_rRWB_Reichw_Max_Ges_Anz 2046;
BA_ "GenSigSwitchedByIgnition" SG_ 2527679676 RW_Prim_rRWB_Reichw_Max_Ges_Anz 0;
BA_ "Fehlerwert" SG_ 2527679676 RW_Prim_rRWB_Reichw_Max_Ges_Anz 2047;
BA_ "GenSigSendType" SG_ 2527679676 RW_Prim_rRWB_Reichw_Rest_E_Anz 0;
BA_ "GenSigStartValue" SG_ 2527679676 RW_Prim_rRWB_Reichw_Rest_E_Anz 2046;
BA_ "GenSigSwitchedByIgnition" SG_ 2527679676 RW_Prim_rRWB_Reichw_Rest_E_Anz 0;
BA_ "Fehlerwert" SG_ 2527679676 RW_Prim_rRWB_Reichw_Rest_E_Anz 2047;
BA_ "GenSigSendType" SG_ 2527679676 RW_Prim_statische_Reichw_Anz 0;
BA_ "GenSigStartValue" SG_ 2527679676 RW_Prim_statische_Reichw_Anz 2046;
BA_ "GenSigSwitchedByIgnition" SG_ 2527679676 RW_Prim_statische_Reichw_Anz 0;
BA_ "Fehlerwert" SG_ 2527679676 RW_Prim_statische_Reichw_Anz 2047;
BA_ "GenSigSendType" SG_ 1440 LS_defekt 0;
BA_ "GenSigSwitchedByIgnition" SG_ 1440 LS_defekt 0;
BA_ "GenSigSendType" SG_ 1440 LS_Helligkeit_FW 0;
BA_ "GenSigStartValue" SG_ 1440 LS_Helligkeit_FW 1022;
BA_ "GenSigSwitchedByIgnition" SG_ 1440 LS_Helligkeit_FW 0;
BA_ "Fehlerwert" SG_ 1440 LS_Helligkeit_FW 1023;
BA_ "GenSigMissingSourceValue" SG_ 1440 LS_Helligkeit_FW 1023;
BA_ "GenSigSendType" SG_ 1440 LS_Helligkeit_IR 0;
BA_ "GenSigStartValue" SG_ 1440 LS_Helligkeit_IR 254;
BA_ "GenSigSwitchedByIgnition" SG_ 1440 LS_Helligkeit_IR 0;
BA_ "Fehlerwert" SG_ 1440 LS_Helligkeit_IR 255;
BA_ "GenSigMissingSourceValue" SG_ 1440 LS_Helligkeit_IR 255;
BA_ "GenSigSendType" SG_ 1440 LS_Verbau 0;
BA_ "GenSigSwitchedByIgnition" SG_ 1440 LS_Verbau 0;
BA_ "GenSigSendType" SG_ 1440 RLS_Vorfeldhelligkeit_Boost 0;
BA_ "GenSigStartValue" SG_ 1440 RLS_Vorfeldhelligkeit_Boost 15;
BA_ "GenSigSwitchedByIgnition" SG_ 1440 RLS_Vorfeldhelligkeit_Boost 0;
BA_ "GenSigSendType" SG_ 1440 RS_defekt 0;
BA_ "GenSigSwitchedByIgnition" SG_ 1440 RS_defekt 0;
BA_ "GenSigSendType" SG_ 1440 RS_Regenmenge 0;
BA_ "GenSigStartValue" SG_ 1440 RS_Regenmenge 14;
BA_ "GenSigSwitchedByIgnition" SG_ 1440 RS_Regenmenge 0;
BA_ "Fehlerwert" SG_ 1440 RS_Regenmenge 15;
BA_ "GenSigMissingSourceValue" SG_ 1440 RS_Regenmenge 15;
BA_ "GenSigSendType" SG_ 1440 RS_Verbau 0;
BA_ "GenSigSwitchedByIgnition" SG_ 1440 RS_Verbau 0;
BA_ "GenSigSendType" SG_ 1440 RS_Verglasung_schliessen 0;
BA_ "GenSigSwitchedByIgnition" SG_ 1440 RS_Verglasung_schliessen 0;
BA_ "GenSigSendType" SG_ 1440 RS_Wischergeschwindigkeit 0;
BA_ "GenSigSwitchedByIgnition" SG_ 1440 RS_Wischergeschwindigkeit 0;
BA_ "GenSigSendType" SG_ 2527679790 RTM_Fehlerstatus 0;
BA_ "GenSigSwitchedByIgnition" SG_ 2527679790 RTM_Fehlerstatus 0;
BA_ "GenSigSendType" SG_ 2527679790 RTM_IstModus 0;
BA_ "GenSigSwitchedByIgnition" SG_ 2527679790 RTM_IstModus 0;
BA_ "GenSigSendType" SG_ 2527679790 RTM_OTA_Download_Process 0;
BA_ "GenSigStartValue" SG_ 2527679790 RTM_OTA_Download_Process 254;
BA_ "GenSigSwitchedByIgnition" SG_ 2527679790 RTM_OTA_Download_Process 0;
BA_ "Fehlerwert" SG_ 2527679790 RTM_OTA_Download_Process 255;
BA_ "GenSigSendType" SG_ 2527679790 RTM_OTA_Download_Size 0;
BA_ "GenSigStartValue" SG_ 2527679790 RTM_OTA_Download_Size 254;
BA_ "GenSigSwitchedByIgnition" SG_ 2527679790 RTM_OTA_Download_Size 0;
BA_ "Fehlerwert" SG_ 2527679790 RTM_OTA_Download_Size 255;
BA_ "GenSigSendType" SG_ 2527679790 RTM_OTA_Download_Speed 0;
BA_ "GenSigSwitchedByIgnition" SG_ 2527679790 RTM_OTA_Download_Speed 0;
BA_ "GenSigSendType" SG_ 2527679790 RTM_OTA_InstallDuration 0;
BA_ "GenSigStartValue" SG_ 2527679790 RTM_OTA_InstallDuration 31;
BA_ "GenSigSwitchedByIgnition" SG_ 2527679790 RTM_OTA_InstallDuration 0;
BA_ "GenSigSendType" SG_ 2527679790 RTM_OTA_InstallPrecondition 0;
BA_ "GenSigSwitchedByIgnition" SG_ 2527679790 RTM_OTA_InstallPrecondition 0;
BA_ "GenSigSendType" SG_ 2527679790 RTM_OTA_InstallProcess 0;
BA_ "GenSigSwitchedByIgnition" SG_ 2527679790 RTM_OTA_InstallProcess 0;
BA_ "GenSigSendType" SG_ 2527679790 RTM_OTA_SignalStrength 0;
BA_ "GenSigSwitchedByIgnition" SG_ 2527679790 RTM_OTA_SignalStrength 0;
BA_ "GenSigSendType" SG_ 1504 MD1_Lage 0;
BA_ "GenSigSwitchedByIgnition" SG_ 1504 MD1_Lage 0;
BA_ "GenSigSendType" SG_ 1504 MD1_Position 3;
BA_ "GenSigStartValue" SG_ 1504 MD1_Position 126;
BA_ "GenSigSwitchedByIgnition" SG_ 1504 MD1_Position 0;
BA_ "GenSigSendType" SG_ 1504 MD3_Lage 0;
BA_ "GenSigSwitchedByIgnition" SG_ 1504 MD3_Lage 0;
BA_ "GenSigSendType" SG_ 1504 MD3_Position 0;
BA_ "GenSigSwitchedByIgnition" SG_ 1504 MD3_Position 0;
BA_ "GenSigSendType" SG_ 1504 MRollo_Lage 0;
BA_ "GenSigSwitchedByIgnition" SG_ 1504 MRollo_Lage 0;
BA_ "GenSigSendType" SG_ 1504 MRollo_Position 0;
BA_ "GenSigStartValue" SG_ 1504 MRollo_Position 126;
BA_ "GenSigSwitchedByIgnition" SG_ 1504 MRollo_Position 0;
BA_ "GenSigSendType" SG_ 1504 Rollo_normiert 3;
BA_ "GenSigSwitchedByIgnition" SG_ 1504 Rollo_normiert 0;
BA_ "GenSigSendType" SG_ 1504 Rollo_Thermoschutz 3;
BA_ "GenSigSwitchedByIgnition" SG_ 1504 Rollo_Thermoschutz 0;
BA_ "GenSigSendType" SG_ 1504 Rollo_UEKB_aktiv 3;
BA_ "GenSigSwitchedByIgnition" SG_ 1504 Rollo_UEKB_aktiv 0;
BA_ "GenSigSendType" SG_ 1504 SAD_Anf_ESC_Zuschaltung 3;
BA_ "GenSigSwitchedByIgnition" SG_ 1504 SAD_Anf_ESC_Zuschaltung 0;
BA_ "GenSigSendType" SG_ 1504 SAD_normiert 3;
BA_ "GenSigSwitchedByIgnition" SG_ 1504 SAD_normiert 0;
BA_ "GenSigSendType" SG_ 1504 SAD_ParityBit 0;
BA_ "GenSigSwitchedByIgnition" SG_ 1504 SAD_ParityBit 0;
BA_ "GenSigActiveRepetitions" SG_ 1504 SAD_Taster_Deckel_hi 5;
BA_ "GenSigSendType" SG_ 1504 SAD_Taster_Deckel_hi 4;
BA_ "GenSigSwitchedByIgnition" SG_ 1504 SAD_Taster_Deckel_hi 0;
BA_ "GenSigActiveRepetitions" SG_ 1504 SAD_Taster_Deckel_vo 5;
BA_ "GenSigSendType" SG_ 1504 SAD_Taster_Deckel_vo 4;
BA_ "GenSigSwitchedByIgnition" SG_ 1504 SAD_Taster_Deckel_vo 0;
BA_ "GenSigActiveRepetitions" SG_ 1504 SAD_Taster_Rollo_hi 5;
BA_ "GenSigSendType" SG_ 1504 SAD_Taster_Rollo_hi 4;
BA_ "GenSigSwitchedByIgnition" SG_ 1504 SAD_Taster_Rollo_hi 0;
BA_ "GenSigActiveRepetitions" SG_ 1504 SAD_Taster_Rollo_vo 5;
BA_ "GenSigSendType" SG_ 1504 SAD_Taster_Rollo_vo 4;
BA_ "GenSigSwitchedByIgnition" SG_ 1504 SAD_Taster_Rollo_vo 0;
BA_ "GenSigActiveRepetitions" SG_ 1504 SAD_Text 5;
BA_ "GenSigSendType" SG_ 1504 SAD_Text 4;
BA_ "GenSigSwitchedByIgnition" SG_ 1504 SAD_Text 0;
BA_ "GenSigSendType" SG_ 1504 SAD_Thermoschutz 3;
BA_ "GenSigSwitchedByIgnition" SG_ 1504 SAD_Thermoschutz 0;
BA_ "GenSigSendType" SG_ 1504 SAD_ToggleBit 0;
BA_ "GenSigSwitchedByIgnition" SG_ 1504 SAD_ToggleBit 0;
BA_ "GenSigSendType" SG_ 1504 SAD_UEKB_aktiv 3;
BA_ "GenSigSwitchedByIgnition" SG_ 1504 SAD_UEKB_aktiv 0;
BA_ "GenSigSendType" SG_ 424 SARA_11_BZ 0;
BA_ "GenSigFuncType" SG_ 424 SARA_11_BZ 1;
BA_ "GenSigSwitchedByIgnition" SG_ 424 SARA_11_BZ 0;
BA_ "GenSigSendType" SG_ 424 SARA_11_CRC 0;
BA_ "GenSigFuncType" SG_ 424 SARA_11_CRC 2;
BA_ "GenSigSwitchedByIgnition" SG_ 424 SARA_11_CRC 0;
BA_ "GenSigSendType" SG_ 424 SARA_Accel_X_r 0;
BA_ "GenSigStartValue" SG_ 424 SARA_Accel_X_r 4096;
BA_ "GenSigSwitchedByIgnition" SG_ 424 SARA_Accel_X_r 0;
BA_ "Fehlerwert" SG_ 424 SARA_Accel_X_r 8191;
BA_ "GenSigSendType" SG_ 424 SARA_Accel_Y_r 0;
BA_ "GenSigStartValue" SG_ 424 SARA_Accel_Y_r 4096;
BA_ "GenSigSwitchedByIgnition" SG_ 424 SARA_Accel_Y_r 0;
BA_ "Fehlerwert" SG_ 424 SARA_Accel_Y_r 8191;
BA_ "GenSigSendType" SG_ 424 SARA_CF_Accel_X_r 0;
BA_ "GenSigStartValue" SG_ 424 SARA_CF_Accel_X_r 4;
BA_ "GenSigSwitchedByIgnition" SG_ 424 SARA_CF_Accel_X_r 0;
BA_ "GenSigSendType" SG_ 424 SARA_CF_Accel_Y_r 0;
BA_ "GenSigStartValue" SG_ 424 SARA_CF_Accel_Y_r 4;
BA_ "GenSigSwitchedByIgnition" SG_ 424 SARA_CF_Accel_Y_r 0;
BA_ "GenSigSendType" SG_ 424 SARA_CF_Omega_Z_r 0;
BA_ "GenSigStartValue" SG_ 424 SARA_CF_Omega_Z_r 4;
BA_ "GenSigSwitchedByIgnition" SG_ 424 SARA_CF_Omega_Z_r 0;
BA_ "GenSigSendType" SG_ 424 SARA_Omega_Z_r 0;
BA_ "GenSigStartValue" SG_ 424 SARA_Omega_Z_r 4096;
BA_ "GenSigSwitchedByIgnition" SG_ 424 SARA_Omega_Z_r 0;
BA_ "Fehlerwert" SG_ 424 SARA_Omega_Z_r 8191;
BA_ "GenSigSendType" SG_ 784 SCU_02_BZ 0;
BA_ "GenSigFuncType" SG_ 784 SCU_02_BZ 1;
BA_ "GenSigSendType" SG_ 784 SCU_02_CRC 0;
BA_ "GenSigFuncType" SG_ 784 SCU_02_CRC 2;
BA_ "GenSigSendType" SG_ 784 SCU_Charisma_FahrPr 0;
BA_ "GenSigSendType" SG_ 784 SCU_Charisma_Status 0;
BA_ "GenSigSendType" SG_ 784 SCU_IL_Status 0;
BA_ "GenSigStartValue" SG_ 784 SCU_IL_Status 1;
BA_ "GenSigSendType" SG_ 784 SCU_Warnungen 3;
BA_ "GenSigSendType" SG_ 1522 KBI_Dimmpoti 0;
BA_ "GenSigSwitchedByIgnition" SG_ 1522 KBI_Dimmpoti 0;
BA_ "Fehlerwert" SG_ 1522 KBI_Dimmpoti 127;
BA_ "GenSigSendType" SG_ 1522 KBI_Phototransistor 3;
BA_ "GenSigStartValue" SG_ 1522 KBI_Phototransistor 254;
BA_ "GenSigSwitchedByIgnition" SG_ 1522 KBI_Phototransistor 0;
BA_ "Fehlerwert" SG_ 1522 KBI_Phototransistor 255;
BA_ "GenSigSendType" SG_ 1363 SR3_Status_Lehne_Links 0;
BA_ "GenSigSwitchedByIgnition" SG_ 1363 SR3_Status_Lehne_Links 0;
BA_ "GenSigSendType" SG_ 1363 SR3_Status_Lehne_Rechts 0;
BA_ "GenSigSwitchedByIgnition" SG_ 1363 SR3_Status_Lehne_Rechts 0;
BA_REL_ "GenSigTimeoutTime" BU_SG_REL_ HUD SG_ 2527679498 Perso_Kontonummer 5000;
BA_REL_ "GenSigTimeoutTime" BU_SG_REL_ HUD SG_ 2527679498 Perso_Steuerung 5000;
BA_REL_ "GenSigTimeoutTime" BU_SG_REL_ HUD SG_ 2527679498 Perso_Steuerungsparameter 5000;
BA_REL_ "GenSigTimeoutTime" BU_SG_REL_ HUD SG_ 2527679498 Perso_Status 5000;
BA_REL_ "GenSigTimeoutTime" BU_SG_REL_ HUD SG_ 319 SC_PreCrash_LED 2000;
BA_REL_ "GenSigTimeoutTime" BU_SG_REL_ HUD SG_ 319 SC_PreCrash_Warnung 2000;
BA_REL_ "GenSigTimeoutTime" BU_SG_REL_ HUD SG_ 1124 PSD_06_Mux 1500;
BA_REL_ "GenSigTimeoutTime" BU_SG_REL_ HUD SG_ 1124 PSD_Sys_Segment_ID 1500;
BA_REL_ "GenSigTimeoutTime" BU_SG_REL_ HUD SG_ 1124 PSD_Sys_Laendercode 1500;
BA_REL_ "GenSigTimeoutTime" BU_SG_REL_ HUD SG_ 1124 PSD_Sys_Geschwindigkeit_Einheit 1500;
BA_REL_ "GenSigTimeoutTime" BU_SG_REL_ HUD SG_ 1124 PSD_Sys_Verkehrsrichtung 1500;
BA_REL_ "GenSigTimeoutTime" BU_SG_REL_ HUD SG_ 1124 PSD_Sys_Geometrieguete 1500;
BA_REL_ "GenSigTimeoutTime" BU_SG_REL_ HUD SG_ 1124 PSD_Sys_Mapmatchingguete 1500;
BA_REL_ "GenSigTimeoutTime" BU_SG_REL_ HUD SG_ 1124 PSD_Sys_Alter_Karte 1500;
BA_REL_ "GenSigTimeoutTime" BU_SG_REL_ HUD SG_ 1124 PSD_Sys_Zielfuehrung 1500;
BA_REL_ "GenSigTimeoutTime" BU_SG_REL_ HUD SG_ 1124 PSD_Sys_US_State 1500;
BA_REL_ "GenSigTimeoutTime" BU_SG_REL_ HUD SG_ 1124 PSD_Sys_Quali_Geometrien 1500;
BA_REL_ "GenSigTimeoutTime" BU_SG_REL_ HUD SG_ 1124 PSD_Sys_Quali_Ortsinfo 1500;
BA_REL_ "GenSigTimeoutTime" BU_SG_REL_ HUD SG_ 1124 PSD_Sys_Quali_verfuegbar 1500;
BA_REL_ "GenSigTimeoutTime" BU_SG_REL_ HUD SG_ 1124 PSD_Sys_Zielfuehrung_geaendert 1500;
BA_REL_ "GenSigTimeoutTime" BU_SG_REL_ HUD SG_ 1124 PSD_Sys_Geometrieguete_erweitert 1500;
BA_REL_ "GenSigTimeoutTime" BU_SG_REL_ HUD SG_ 1124 PSD_Sys_Quali_sonstige_Attribute 1500;
BA_REL_ "GenSigTimeoutTime" BU_SG_REL_ HUD SG_ 1124 PSD_Sys_Quali_Steigungen 1500;
BA_REL_ "GenSigTimeoutTime" BU_SG_REL_ HUD SG_ 1124 PSD_Sys_Quali_Strassenkennz 1500;
BA_REL_ "GenSigTimeoutTime" BU_SG_REL_ HUD SG_ 1124 PSD_Sys_Quali_Tempolimits 1500;
BA_REL_ "GenSigTimeoutTime" BU_SG_REL_ HUD SG_ 1124 PSD_Sys_Quali_Vorfahrtsregelung 1500;
BA_REL_ "GenSigTimeoutTime" BU_SG_REL_ HUD SG_ 2463978730 pVS_vLimit_HMI 1000;
BA_REL_ "GenSigTimeoutTime" BU_SG_REL_ HUD SG_ 2463978730 pVS_Hinweismeldung 1000;
BA_REL_ "GenSigTimeoutTime" BU_SG_REL_ HUD SG_ 2463978730 pVS_vLimit_HMI_Unit 1000;
BA_REL_ "GenSigTimeoutTime" BU_SG_REL_ HUD SG_ 2463978730 pVS_IconActivation 1000;
BA_REL_ "GenSigTimeoutTime" BU_SG_REL_ HUD SG_ 1525 RW_Reservewarnung_2_aktiv 5000;
BA_REL_ "GenSigTimeoutTime" BU_SG_REL_ HUD SG_ 1527 RW_Reservewarnung_aktiv 5000;
BA_REL_ "GenSigTimeoutTime" BU_SG_REL_ HUD SG_ 1527 RW_Primaer_Reichweite_Anzeige 5000;
BA_REL_ "GenSigTimeoutTime" BU_SG_REL_ HUD SG_ 2527679676 RW_Prim_rRWB_aktiv 5000;
BA_REL_ "GenSigTimeoutTime" BU_SG_REL_ HUD SG_ 2527679676 RW_Prim_rRWB_Reichw_Gesamt_Anz 5000;
BA_REL_ "GenSigTimeoutTime" BU_SG_REL_ HUD SG_ 2527679676 RW_Prim_statische_Reichw_Anz 5000;
BA_REL_ "GenSigTimeoutTime" BU_SG_REL_ HUD SG_ 2527679676 RW_Prim_rRWB_Reichw_Rest_E_Anz 5000;
BA_REL_ "GenSigTimeoutTime" BU_SG_REL_ HUD SG_ 1440 LS_Helligkeit_IR 2000;
BA_REL_ "GenSigTimeoutTime" BU_SG_REL_ HUD SG_ 1440 LS_Helligkeit_FW 2000;
BA_REL_ "GenSigTimeoutTime" BU_SG_REL_ HUD SG_ 1440 LS_defekt 2000;
BA_REL_ "GenSigTimeoutTime" BU_SG_REL_ HUD SG_ 1440 LS_Verbau 2000;
BA_REL_ "GenSigTimeoutTime" BU_SG_REL_ HUD SG_ 1440 RLS_Vorfeldhelligkeit_Boost 2000;
BA_REL_ "GenSigTimeoutTime" BU_SG_REL_ HUD SG_ 424 SARA_Accel_X_r 500;
BA_REL_ "GenSigTimeoutTime" BU_SG_REL_ HUD SG_ 424 SARA_Accel_Y_r 500;
BA_REL_ "GenSigTimeoutTime" BU_SG_REL_ HUD SG_ 424 SARA_CF_Accel_X_r 500;
BA_REL_ "GenSigTimeoutTime" BU_SG_REL_ HUD SG_ 424 SARA_CF_Accel_Y_r 500;
BA_REL_ "GenSigTimeoutTime" BU_SG_REL_ HUD SG_ 1522 KBI_Phototransistor 2000;
BA_REL_ "GenSigTimeoutTime" BU_SG_REL_ Kombi SG_ 1355 PH_Verschmutzungsmeldung 5000;
BA_REL_ "GenSigTimeoutTime" BU_SG_REL_ Kombi SG_ 1355 BCM_WAH_Meldung 5000;
BA_REL_ "GenSigTimeoutTime" BU_SG_REL_ Kombi SG_ 803 SC_WarnBrems_Texte 2000;
BA_REL_ "GenSigTimeoutTime" BU_SG_REL_ Kombi SG_ 803 SC_AbstWarn_Texte 2000;
BA_REL_ "GenSigTimeoutTime" BU_SG_REL_ Kombi SG_ 2527679498 Perso_Kontonummer 5000;
BA_REL_ "GenSigTimeoutTime" BU_SG_REL_ Kombi SG_ 2527679498 Perso_Steuerung 5000;
BA_REL_ "GenSigTimeoutTime" BU_SG_REL_ Kombi SG_ 2527679498 Perso_Steuerungsparameter 5000;
BA_REL_ "GenSigTimeoutTime" BU_SG_REL_ Kombi SG_ 2527679498 Perso_Status 5000;
BA_REL_ "GenSigTimeoutTime" BU_SG_REL_ Kombi SG_ 398 PLA2_Anf_Meldungen_FA 1000;
BA_REL_ "GenSigTimeoutTime" BU_SG_REL_ Kombi SG_ 398 PLA2_Anf_Meldungen_MA 1000;
BA_REL_ "GenSigTimeoutTime" BU_SG_REL_ Kombi SG_ 398 PLA2_Status_Aktive_Seite 1000;
BA_REL_ "GenSigTimeoutTime" BU_SG_REL_ Kombi SG_ 398 PLA2_Anf_Anzeige_Mini 1000;
BA_REL_ "GenSigTimeoutTime" BU_SG_REL_ Kombi SG_ 398 PLA2_Anf_Anzeige_Schwellpfeil 1000;
BA_REL_ "GenSigTimeoutTime" BU_SG_REL_ Kombi SG_ 398 PLA2_Anf_Akustik 1000;
BA_REL_ "GenSigTimeoutTime" BU_SG_REL_ Kombi SG_ 398 PLA2_Mini_Modus 1000;
BA_REL_ "GenSigTimeoutTime" BU_SG_REL_ Kombi SG_ 398 PLA2_Anf_Anzeige_Bremsfuss 1000;
BA_REL_ "GenSigTimeoutTime" BU_SG_REL_ Kombi SG_ 398 PLA2_Anf_Anzeigemodus 1000;
BA_REL_ "GenSigTimeoutTime" BU_SG_REL_ Kombi SG_ 398 PLA2_Anf_Meldungen 1000;
BA_REL_ "GenSigTimeoutTime" BU_SG_REL_ Kombi SG_ 398 PLA2_Anzahl_Seg_Schwellpfeil 1000;
BA_REL_ "GenSigTimeoutTime" BU_SG_REL_ Kombi SG_ 398 PLA2_Status_Funktion 1000;
BA_REL_ "GenSigTimeoutTime" BU_SG_REL_ Kombi SG_ 1166 PLA_Status_Aktive_Seite 1000;
BA_REL_ "GenSigTimeoutTime" BU_SG_REL_ Kombi SG_ 1166 PLA_Anf_Anzeige_Mini 1000;
BA_REL_ "GenSigTimeoutTime" BU_SG_REL_ Kombi SG_ 1166 PLA_Mini_Modus 1000;
BA_REL_ "GenSigTimeoutTime" BU_SG_REL_ Kombi SG_ 1166 PLA_Anf_Akustik 1000;
BA_REL_ "GenSigTimeoutTime" BU_SG_REL_ Kombi SG_ 1166 PLA_Anf_Anzeige_Schwellpfeil 1000;
BA_REL_ "GenSigTimeoutTime" BU_SG_REL_ Kombi SG_ 1166 PLA_Anf_Anzeige_Bremsfuss 1000;
BA_REL_ "GenSigTimeoutTime" BU_SG_REL_ Kombi SG_ 1166 PLA_Anf_Anzeigemodus 1000;
BA_REL_ "GenSigTimeoutTime" BU_SG_REL_ Kombi SG_ 1166 PLA_Anf_Meldungen 1000;
BA_REL_ "GenSigTimeoutTime" BU_SG_REL_ Kombi SG_ 1166 PLA_Anzahl_Segmente_Schwellpfeil 1000;
BA_REL_ "GenSigTimeoutTime" BU_SG_REL_ Kombi SG_ 1166 PLA_Status_Funktion 1000;
BA_REL_ "GenSigTimeoutTime" BU_SG_REL_ Kombi SG_ 319 SC_PreCrash_LED 2000;
BA_REL_ "GenSigTimeoutTime" BU_SG_REL_ Kombi SG_ 319 SC_PreCrash_Warnung 2000;
BA_REL_ "GenSigTimeoutTime" BU_SG_REL_ Kombi SG_ 319 SC_PreCrash_Texte 2000;
BA_REL_ "GenSigTimeoutTime" BU_SG_REL_ Kombi SG_ 1122 PSD_Segment_ID 1500;
BA_REL_ "GenSigTimeoutTime" BU_SG_REL_ Kombi SG_ 1122 PSD_Vorgaenger_Segment_ID 1500;
BA_REL_ "GenSigTimeoutTime" BU_SG_REL_ Kombi SG_ 1122 PSD_Segmentlaenge 1500;
BA_REL_ "GenSigTimeoutTime" BU_SG_REL_ Kombi SG_ 1122 PSD_Strassenkategorie 1500;
BA_REL_ "GenSigTimeoutTime" BU_SG_REL_ Kombi SG_ 1122 PSD_Endkruemmung 1500;
BA_REL_ "GenSigTimeoutTime" BU_SG_REL_ Kombi SG_ 1122 PSD_Endkruemmung_Vorz 1500;
BA_REL_ "GenSigTimeoutTime" BU_SG_REL_ Kombi SG_ 1122 PSD_Idenditaets_ID 1500;
BA_REL_ "GenSigTimeoutTime" BU_SG_REL_ Kombi SG_ 1122 PSD_ADAS_Qualitaet 1500;
BA_REL_ "GenSigTimeoutTime" BU_SG_REL_ Kombi SG_ 1122 PSD_wahrscheinlichster_Pfad 1500;
BA_REL_ "GenSigTimeoutTime" BU_SG_REL_ Kombi SG_ 1122 PSD_Geradester_Pfad 1500;
BA_REL_ "GenSigTimeoutTime" BU_SG_REL_ Kombi SG_ 1122 PSD_Fahrspuren_Anzahl 1500;
BA_REL_ "GenSigTimeoutTime" BU_SG_REL_ Kombi SG_ 1122 PSD_Bebauung 1500;
BA_REL_ "GenSigTimeoutTime" BU_SG_REL_ Kombi SG_ 1122 PSD_Segment_Komplett 1500;
BA_REL_ "GenSigTimeoutTime" BU_SG_REL_ Kombi SG_ 1122 PSD_Rampe 1500;
BA_REL_ "GenSigTimeoutTime" BU_SG_REL_ Kombi SG_ 1122 PSD_Anfangskruemmung 1500;
BA_REL_ "GenSigTimeoutTime" BU_SG_REL_ Kombi SG_ 1122 PSD_Anfangskruemmung_Vorz 1500;
BA_REL_ "GenSigTimeoutTime" BU_SG_REL_ Kombi SG_ 1122 PSD_Abzweigerichtung 1500;
BA_REL_ "GenSigTimeoutTime" BU_SG_REL_ Kombi SG_ 1122 PSD_Abzweigewinkel 1500;
BA_REL_ "GenSigTimeoutTime" BU_SG_REL_ Kombi SG_ 1123 PSD_Pos_Segment_ID 1500;
BA_REL_ "GenSigTimeoutTime" BU_SG_REL_ Kombi SG_ 1123 PSD_Pos_Segmentlaenge 1500;
BA_REL_ "GenSigTimeoutTime" BU_SG_REL_ Kombi SG_ 1123 PSD_Pos_Inhibitzeit 1500;
BA_REL_ "GenSigTimeoutTime" BU_SG_REL_ Kombi SG_ 1123 PSD_Pos_Standort_Eindeutig 1500;
BA_REL_ "GenSigTimeoutTime" BU_SG_REL_ Kombi SG_ 1123 PSD_Pos_Fehler_Laengsrichtung 1500;
BA_REL_ "GenSigTimeoutTime" BU_SG_REL_ Kombi SG_ 1123 PSD_Pos_Fahrspur 1500;
BA_REL_ "GenSigTimeoutTime" BU_SG_REL_ Kombi SG_ 1123 PSD_Attribut_Segment_ID_05 1500;
BA_REL_ "GenSigTimeoutTime" BU_SG_REL_ Kombi SG_ 1123 PSD_Attribut_1_ID 1500;
BA_REL_ "GenSigTimeoutTime" BU_SG_REL_ Kombi SG_ 1123 PSD_Attribut_1_Wert 1500;
BA_REL_ "GenSigTimeoutTime" BU_SG_REL_ Kombi SG_ 1123 PSD_Attribut_1_Offset 1500;
BA_REL_ "GenSigTimeoutTime" BU_SG_REL_ Kombi SG_ 1123 PSD_Attribut_2_ID 1500;
BA_REL_ "GenSigTimeoutTime" BU_SG_REL_ Kombi SG_ 1123 PSD_Attribut_2_Wert 1500;
BA_REL_ "GenSigTimeoutTime" BU_SG_REL_ Kombi SG_ 1123 PSD_Attribut_2_Offset 1500;
BA_REL_ "GenSigTimeoutTime" BU_SG_REL_ Kombi SG_ 1123 PSD_Attribute_Komplett_05 1500;
BA_REL_ "GenSigTimeoutTime" BU_SG_REL_ Kombi SG_ 1124 PSD_06_Mux 1500;
BA_REL_ "GenSigTimeoutTime" BU_SG_REL_ Kombi SG_ 1124 PSD_Sys_Segment_ID 1500;
BA_REL_ "GenSigTimeoutTime" BU_SG_REL_ Kombi SG_ 1124 PSD_Attribut_Segment_ID 1500;
BA_REL_ "GenSigTimeoutTime" BU_SG_REL_ Kombi SG_ 1124 PSD_Ges_Segment_ID 1500;
BA_REL_ "GenSigTimeoutTime" BU_SG_REL_ Kombi SG_ 1124 PSD_Baum_Laenge_VZ 1500;
BA_REL_ "GenSigTimeoutTime" BU_SG_REL_ Kombi SG_ 1124 PSD_Steigung_1_Segment_ID 1500;
BA_REL_ "GenSigTimeoutTime" BU_SG_REL_ Kombi SG_ 1124 PSD_Baum_Laenge 1500;
BA_REL_ "GenSigTimeoutTime" BU_SG_REL_ Kombi SG_ 1124 PSD_Sys_Laendercode 1500;
BA_REL_ "GenSigTimeoutTime" BU_SG_REL_ Kombi SG_ 1124 PSD_Attribut_3_ID 1500;
BA_REL_ "GenSigTimeoutTime" BU_SG_REL_ Kombi SG_ 1124 PSD_Ges_Offset 1500;
BA_REL_ "GenSigTimeoutTime" BU_SG_REL_ Kombi SG_ 1124 PSD_Steigung_1_A_Steigung 1500;
BA_REL_ "GenSigTimeoutTime" BU_SG_REL_ Kombi SG_ 1124 PSD_Attribut_3_Offset 1500;
BA_REL_ "GenSigTimeoutTime" BU_SG_REL_ Kombi SG_ 1124 PSD_Ges_Geschwindigkeit 1500;
BA_REL_ "GenSigTimeoutTime" BU_SG_REL_ Kombi SG_ 1124 PSD_Steigung_1_A_Vorz 1500;
BA_REL_ "GenSigTimeoutTime" BU_SG_REL_ Kombi SG_ 1124 PSD_Sys_Geschwindigkeit_Einheit 1500;
BA_REL_ "GenSigTimeoutTime" BU_SG_REL_ Kombi SG_ 1124 PSD_Steigung_1_A_Offset 1500;
BA_REL_ "GenSigTimeoutTime" BU_SG_REL_ Kombi SG_ 1124 PSD_Sys_Verkehrsrichtung 1500;
BA_REL_ "GenSigTimeoutTime" BU_SG_REL_ Kombi SG_ 1124 PSD_Sys_Geometrieguete 1500;
BA_REL_ "GenSigTimeoutTime" BU_SG_REL_ Kombi SG_ 1124 PSD_Sys_Mapmatchingguete 1500;
BA_REL_ "GenSigTimeoutTime" BU_SG_REL_ Kombi SG_ 1124 PSD_Attribut_3_Wert 1500;
BA_REL_ "GenSigTimeoutTime" BU_SG_REL_ Kombi SG_ 1124 PSD_Ges_Typ 1500;
BA_REL_ "GenSigTimeoutTime" BU_SG_REL_ Kombi SG_ 1124 PSD_Sys_Alter_Karte 1500;
BA_REL_ "GenSigTimeoutTime" BU_SG_REL_ Kombi SG_ 1124 PSD_Ges_Spur_Geschw_Begrenzung 1500;
BA_REL_ "GenSigTimeoutTime" BU_SG_REL_ Kombi SG_ 1124 PSD_Steigung_1_B_Steigung 1500;
BA_REL_ "GenSigTimeoutTime" BU_SG_REL_ Kombi SG_ 1124 PSD_Attribut_4_ID 1500;
BA_REL_ "GenSigTimeoutTime" BU_SG_REL_ Kombi SG_ 1124 PSD_Sys_Zielfuehrung 1500;
BA_REL_ "GenSigTimeoutTime" BU_SG_REL_ Kombi SG_ 1124 PSD_Sys_US_State 1500;
BA_REL_ "GenSigTimeoutTime" BU_SG_REL_ Kombi SG_ 1124 PSD_Ges_Geschwindigkeit_Gespann 1500;
BA_REL_ "GenSigTimeoutTime" BU_SG_REL_ Kombi SG_ 1124 PSD_Baum_Breite_VZ 1500;
BA_REL_ "GenSigTimeoutTime" BU_SG_REL_ Kombi SG_ 1124 PSD_Attribut_4_Wert 1500;
BA_REL_ "GenSigTimeoutTime" BU_SG_REL_ Kombi SG_ 1124 PSD_Baum_Breite 1500;
BA_REL_ "GenSigTimeoutTime" BU_SG_REL_ Kombi SG_ 1124 PSD_Ges_Geschwindigkeit_Witter 1500;
BA_REL_ "GenSigTimeoutTime" BU_SG_REL_ Kombi SG_ 1124 PSD_Steigung_1_B_Vorz 1500;
BA_REL_ "GenSigTimeoutTime" BU_SG_REL_ Kombi SG_ 1124 PSD_Steigung_1_B_Offset 1500;
BA_REL_ "GenSigTimeoutTime" BU_SG_REL_ Kombi SG_ 1124 PSD_Ges_Geschwindigkeit_Tag_Anf 1500;
BA_REL_ "GenSigTimeoutTime" BU_SG_REL_ Kombi SG_ 1124 PSD_Attribut_4_Offset 1500;
BA_REL_ "GenSigTimeoutTime" BU_SG_REL_ Kombi SG_ 1124 PSD_Ges_Geschwindigkeit_Tag_Ende 1500;
BA_REL_ "GenSigTimeoutTime" BU_SG_REL_ Kombi SG_ 1124 PSD_Ges_Geschwindigkeit_Std_Anf 1500;
BA_REL_ "GenSigTimeoutTime" BU_SG_REL_ Kombi SG_ 1124 PSD_Steigung_1_Attribute_kompl 1500;
BA_REL_ "GenSigTimeoutTime" BU_SG_REL_ Kombi SG_ 1124 PSD_Steigung_2_Segment_ID 1500;
BA_REL_ "GenSigTimeoutTime" BU_SG_REL_ Kombi SG_ 1124 PSD_Attribut_5_ID 1500;
BA_REL_ "GenSigTimeoutTime" BU_SG_REL_ Kombi SG_ 1124 PSD_Ges_Geschwindigkeit_Std_Ende 1500;
BA_REL_ "GenSigTimeoutTime" BU_SG_REL_ Kombi SG_ 1124 PSD_Attribut_5_Offset 1500;
BA_REL_ "GenSigTimeoutTime" BU_SG_REL_ Kombi SG_ 1124 PSD_Steigung_2_Steigung 1500;
BA_REL_ "GenSigTimeoutTime" BU_SG_REL_ Kombi SG_ 1124 PSD_Ges_Ueberholverbot 1500;
BA_REL_ "GenSigTimeoutTime" BU_SG_REL_ Kombi SG_ 1124 PSD_Ges_Wechselverkehrszeichen 1500;
BA_REL_ "GenSigTimeoutTime" BU_SG_REL_ Kombi SG_ 1124 PSD_Attribut_5_Wert 1500;
BA_REL_ "GenSigTimeoutTime" BU_SG_REL_ Kombi SG_ 1124 PSD_Steigung_2_Vorz 1500;
BA_REL_ "GenSigTimeoutTime" BU_SG_REL_ Kombi SG_ 1124 PSD_Wechselverkehrszeichen_Typ 1500;
BA_REL_ "GenSigTimeoutTime" BU_SG_REL_ Kombi SG_ 1124 PSD_Baum_Ausrichtung 1500;
BA_REL_ "GenSigTimeoutTime" BU_SG_REL_ Kombi SG_ 1124 PSD_Steigung_2_Offset 1500;
BA_REL_ "GenSigTimeoutTime" BU_SG_REL_ Kombi SG_ 1124 PSD_Ges_Gesetzlich_Kategorie 1500;
BA_REL_ "GenSigTimeoutTime" BU_SG_REL_ Kombi SG_ 1124 PSD_Attribute_Komplett_06 1500;
BA_REL_ "GenSigTimeoutTime" BU_SG_REL_ Kombi SG_ 1124 PSD_Ges_Gesetzlich_Zusatz 1500;
BA_REL_ "GenSigTimeoutTime" BU_SG_REL_ Kombi SG_ 1124 PSD_Ges_Verkehrszeichen_Quelle 1500;
BA_REL_ "GenSigTimeoutTime" BU_SG_REL_ Kombi SG_ 1124 PSD_Steigung_2_Attribute_kompl 1500;
BA_REL_ "GenSigTimeoutTime" BU_SG_REL_ Kombi SG_ 1124 PSD_Ges_Attribute_Komplett 1500;
BA_REL_ "GenSigTimeoutTime" BU_SG_REL_ Kombi SG_ 906 QSP_Warnlampe 1000;
BA_REL_ "GenSigTimeoutTime" BU_SG_REL_ Kombi SG_ 1339 QS_Warntexte 5000;
BA_REL_ "GenSigTimeoutTime" BU_SG_REL_ Kombi SG_ 1616 RA_Frequency 5000;
BA_REL_ "GenSigTimeoutTime" BU_SG_REL_ Kombi SG_ 1616 RA_Frequency_unit 5000;
BA_REL_ "GenSigTimeoutTime" BU_SG_REL_ Kombi SG_ 1616 RA_AM_Tuning 5000;
BA_REL_ "GenSigTimeoutTime" BU_SG_REL_ Kombi SG_ 1529 RDK_FMVSS138_Lampe 3200;
BA_REL_ "GenSigTimeoutTime" BU_SG_REL_ Kombi SG_ 1529 RDK_FMVSS138_MIL 3200;
BA_REL_ "GenSigTimeoutTime" BU_SG_REL_ Kombi SG_ 1529 RDK_Reifendruck_Lampe 3200;
BA_REL_ "GenSigTimeoutTime" BU_SG_REL_ Kombi SG_ 1529 RDK_Warnungen_02 3200;
BA_REL_ "GenSigTimeoutTime" BU_SG_REL_ Kombi SG_ 1529 RDK_Reifentemperatur_Lampe 3200;
BA_REL_ "GenSigTimeoutTime" BU_SG_REL_ Kombi SG_ 1529 RDK_W_1_Reifen_HL 3200;
BA_REL_ "GenSigTimeoutTime" BU_SG_REL_ Kombi SG_ 1529 RDK_W_1_Reifen_HR 3200;
BA_REL_ "GenSigTimeoutTime" BU_SG_REL_ Kombi SG_ 1529 RDK_W_1_Reifen_VL 3200;
BA_REL_ "GenSigTimeoutTime" BU_SG_REL_ Kombi SG_ 1529 RDK_W_1_Reifen_VR 3200;
BA_REL_ "GenSigTimeoutTime" BU_SG_REL_ Kombi SG_ 1529 RDK_W_2_Reifen_HL 3200;
BA_REL_ "GenSigTimeoutTime" BU_SG_REL_ Kombi SG_ 1529 RDK_W_2_Reifen_HR 3200;
BA_REL_ "GenSigTimeoutTime" BU_SG_REL_ Kombi SG_ 1529 RDK_W_2_Reifen_VL 3200;
BA_REL_ "GenSigTimeoutTime" BU_SG_REL_ Kombi SG_ 1529 RDK_W_2_Reifen_VR 3200;
BA_REL_ "GenSigTimeoutTime" BU_SG_REL_ Kombi SG_ 1525 RW_Gesamt_Reichweite_Max_Anzeige 5000;
BA_REL_ "GenSigTimeoutTime" BU_SG_REL_ Kombi SG_ 1525 RW_Reservewarnung_2_aktiv 5000;
BA_REL_ "GenSigTimeoutTime" BU_SG_REL_ Kombi SG_ 1525 RW_Gesamt_Reichweite 5000;
BA_REL_ "GenSigTimeoutTime" BU_SG_REL_ Kombi SG_ 1525 RW_Prim_Reichweitenverbrauch 5000;
BA_REL_ "GenSigTimeoutTime" BU_SG_REL_ Kombi SG_ 1525 RW_Prim_Reichweitenv_Einheit 5000;
BA_REL_ "GenSigTimeoutTime" BU_SG_REL_ Kombi SG_ 1525 RW_Primaer_Reichweite 5000;
BA_REL_ "GenSigTimeoutTime" BU_SG_REL_ Kombi SG_ 1527 RW_Texte 5000;
BA_REL_ "GenSigTimeoutTime" BU_SG_REL_ Kombi SG_ 1527 RW_Reservewarnung_aktiv 5000;
BA_REL_ "GenSigTimeoutTime" BU_SG_REL_ Kombi SG_ 1527 RW_Reichweite_Einheit_Anzeige 5000;
BA_REL_ "GenSigTimeoutTime" BU_SG_REL_ Kombi SG_ 1527 RW_Gesamt_Reichweite_Anzeige 5000;
BA_REL_ "GenSigTimeoutTime" BU_SG_REL_ Kombi SG_ 1527 RW_Primaer_Reichweite_Anzeige 5000;
BA_REL_ "GenSigTimeoutTime" BU_SG_REL_ Kombi SG_ 1527 RW_Sekundaer_Reichweite_Anzeige 5000;
BA_REL_ "GenSigTimeoutTime" BU_SG_REL_ Kombi SG_ 1527 RW_Sekundaer_Reichweite 5000;
BA_REL_ "GenSigTimeoutTime" BU_SG_REL_ Kombi SG_ 1527 RW_Sek_Reichweitenv_Einheit 5000;
BA_REL_ "GenSigTimeoutTime" BU_SG_REL_ Kombi SG_ 1527 RW_Sek_Reichweitenverbrauch 5000;
BA_REL_ "GenSigTimeoutTime" BU_SG_REL_ Kombi SG_ 2527679676 RW_Prim_rRWB_Reichw_Max_Ges_Anz 5000;
BA_REL_ "GenSigTimeoutTime" BU_SG_REL_ Kombi SG_ 2527679676 RW_Prim_rRWB_aktiv 5000;
BA_REL_ "GenSigTimeoutTime" BU_SG_REL_ Kombi SG_ 2527679676 RW_Prim_rRWB_Reichw_Anz 5000;
BA_REL_ "GenSigTimeoutTime" BU_SG_REL_ Kombi SG_ 2527679676 RW_Prim_rRWB_Reichw_Gesamt_Anz 5000;
BA_REL_ "GenSigTimeoutTime" BU_SG_REL_ Kombi SG_ 2527679676 RW_Prim_statische_Reichw_Anz 5000;
BA_REL_ "GenSigTimeoutTime" BU_SG_REL_ Kombi SG_ 2527679676 RW_Prim_rRWB_Reichw_Rest_E_Anz 5000;
BA_REL_ "GenSigTimeoutTime" BU_SG_REL_ Kombi SG_ 1440 RS_Regenmenge 2000;
BA_REL_ "GenSigTimeoutTime" BU_SG_REL_ Kombi SG_ 1440 RS_defekt 2000;
BA_REL_ "GenSigTimeoutTime" BU_SG_REL_ Kombi SG_ 1440 RS_Wischergeschwindigkeit 2000;
BA_REL_ "GenSigTimeoutTime" BU_SG_REL_ Kombi SG_ 2527679790 RTM_IstModus 5000;
BA_REL_ "GenSigTimeoutTime" BU_SG_REL_ Kombi SG_ 424 SARA_Accel_X_r 500;
BA_REL_ "GenSigTimeoutTime" BU_SG_REL_ Kombi SG_ 424 SARA_Accel_Y_r 500;
BA_REL_ "GenSigTimeoutTime" BU_SG_REL_ Kombi SG_ 424 SARA_CF_Accel_X_r 500;
BA_REL_ "GenSigTimeoutTime" BU_SG_REL_ Kombi SG_ 424 SARA_CF_Accel_Y_r 500;
BA_REL_ "GenSigTimeoutTime" BU_SG_REL_ Kombi SG_ 784 SCU_02_CRC 1200;
BA_REL_ "GenSigTimeoutTime" BU_SG_REL_ Kombi SG_ 784 SCU_02_BZ 1200;
BA_REL_ "GenSigTimeoutTime" BU_SG_REL_ Kombi SG_ 784 SCU_Warnungen 1200;
BA_REL_ "GenSigTimeoutTime" BU_SG_REL_ Kombi SG_ 1363 SR3_Status_Lehne_Links 1000;
BA_REL_ "GenSigTimeoutTime" BU_SG_REL_ Kombi SG_ 1363 SR3_Status_Lehne_Rechts 1000;
BA_REL_ "GenSigTimeoutTime" BU_SG_REL_ Kombi_LB SG_ 1355 PH_Verschmutzungsmeldung 5000;
BA_REL_ "GenSigTimeoutTime" BU_SG_REL_ Kombi_LB SG_ 803 SC_WarnBrems_Texte 2000;
BA_REL_ "GenSigTimeoutTime" BU_SG_REL_ Kombi_LB SG_ 803 SC_AbstWarn_Texte 2000;
BA_REL_ "GenSigTimeoutTime" BU_SG_REL_ Kombi_LB SG_ 2527679498 Perso_Kontonummer 5000;
BA_REL_ "GenSigTimeoutTime" BU_SG_REL_ Kombi_LB SG_ 2527679498 Perso_Steuerung 5000;
BA_REL_ "GenSigTimeoutTime" BU_SG_REL_ Kombi_LB SG_ 2527679498 Perso_Steuerungsparameter 5000;
BA_REL_ "GenSigTimeoutTime" BU_SG_REL_ Kombi_LB SG_ 2527679498 Perso_Status 5000;
BA_REL_ "GenSigTimeoutTime" BU_SG_REL_ Kombi_LB SG_ 398 PLA2_Anf_Meldungen_FA 1000;
BA_REL_ "GenSigTimeoutTime" BU_SG_REL_ Kombi_LB SG_ 398 PLA2_Anf_Meldungen_MA 1000;
BA_REL_ "GenSigTimeoutTime" BU_SG_REL_ Kombi_LB SG_ 398 PLA2_Status_Aktive_Seite 1000;
BA_REL_ "GenSigTimeoutTime" BU_SG_REL_ Kombi_LB SG_ 398 PLA2_Anf_Anzeige_Mini 1000;
BA_REL_ "GenSigTimeoutTime" BU_SG_REL_ Kombi_LB SG_ 398 PLA2_Anf_Anzeige_Schwellpfeil 1000;
BA_REL_ "GenSigTimeoutTime" BU_SG_REL_ Kombi_LB SG_ 398 PLA2_Anf_Akustik 1000;
BA_REL_ "GenSigTimeoutTime" BU_SG_REL_ Kombi_LB SG_ 398 PLA2_Mini_Modus 1000;
BA_REL_ "GenSigTimeoutTime" BU_SG_REL_ Kombi_LB SG_ 398 PLA2_Anf_Anzeige_Bremsfuss 1000;
BA_REL_ "GenSigTimeoutTime" BU_SG_REL_ Kombi_LB SG_ 398 PLA2_Anf_Anzeigemodus 1000;
BA_REL_ "GenSigTimeoutTime" BU_SG_REL_ Kombi_LB SG_ 398 PLA2_Anf_Meldungen 1000;
BA_REL_ "GenSigTimeoutTime" BU_SG_REL_ Kombi_LB SG_ 398 PLA2_Anzahl_Seg_Schwellpfeil 1000;
BA_REL_ "GenSigTimeoutTime" BU_SG_REL_ Kombi_LB SG_ 398 PLA2_Status_Funktion 1000;
BA_REL_ "GenSigTimeoutTime" BU_SG_REL_ Kombi_LB SG_ 1166 PLA_Status_Aktive_Seite 1000;
BA_REL_ "GenSigTimeoutTime" BU_SG_REL_ Kombi_LB SG_ 1166 PLA_Anf_Anzeige_Mini 1000;
BA_REL_ "GenSigTimeoutTime" BU_SG_REL_ Kombi_LB SG_ 1166 PLA_Mini_Modus 1000;
BA_REL_ "GenSigTimeoutTime" BU_SG_REL_ Kombi_LB SG_ 1166 PLA_Anf_Akustik 1000;
BA_REL_ "GenSigTimeoutTime" BU_SG_REL_ Kombi_LB SG_ 1166 PLA_Anf_Anzeige_Schwellpfeil 1000;
BA_REL_ "GenSigTimeoutTime" BU_SG_REL_ Kombi_LB SG_ 1166 PLA_Anf_Anzeige_Bremsfuss 1000;
BA_REL_ "GenSigTimeoutTime" BU_SG_REL_ Kombi_LB SG_ 1166 PLA_Anf_Anzeigemodus 1000;
BA_REL_ "GenSigTimeoutTime" BU_SG_REL_ Kombi_LB SG_ 1166 PLA_Anf_Meldungen 1000;
BA_REL_ "GenSigTimeoutTime" BU_SG_REL_ Kombi_LB SG_ 1166 PLA_Anzahl_Segmente_Schwellpfeil 1000;
BA_REL_ "GenSigTimeoutTime" BU_SG_REL_ Kombi_LB SG_ 1166 PLA_Status_Funktion 1000;
BA_REL_ "GenSigTimeoutTime" BU_SG_REL_ Kombi_LB SG_ 319 SC_PreCrash_LED 2000;
BA_REL_ "GenSigTimeoutTime" BU_SG_REL_ Kombi_LB SG_ 319 SC_PreCrash_Warnung 2000;
BA_REL_ "GenSigTimeoutTime" BU_SG_REL_ Kombi_LB SG_ 319 SC_PreCrash_Texte 2000;
BA_REL_ "GenSigTimeoutTime" BU_SG_REL_ Kombi_LB SG_ 1122 PSD_Segment_ID 1500;
BA_REL_ "GenSigTimeoutTime" BU_SG_REL_ Kombi_LB SG_ 1122 PSD_Vorgaenger_Segment_ID 1500;
BA_REL_ "GenSigTimeoutTime" BU_SG_REL_ Kombi_LB SG_ 1122 PSD_Segmentlaenge 1500;
BA_REL_ "GenSigTimeoutTime" BU_SG_REL_ Kombi_LB SG_ 1122 PSD_Strassenkategorie 1500;
BA_REL_ "GenSigTimeoutTime" BU_SG_REL_ Kombi_LB SG_ 1122 PSD_Endkruemmung 1500;
BA_REL_ "GenSigTimeoutTime" BU_SG_REL_ Kombi_LB SG_ 1122 PSD_Endkruemmung_Vorz 1500;
BA_REL_ "GenSigTimeoutTime" BU_SG_REL_ Kombi_LB SG_ 1122 PSD_Idenditaets_ID 1500;
BA_REL_ "GenSigTimeoutTime" BU_SG_REL_ Kombi_LB SG_ 1122 PSD_ADAS_Qualitaet 1500;
BA_REL_ "GenSigTimeoutTime" BU_SG_REL_ Kombi_LB SG_ 1122 PSD_wahrscheinlichster_Pfad 1500;
BA_REL_ "GenSigTimeoutTime" BU_SG_REL_ Kombi_LB SG_ 1122 PSD_Geradester_Pfad 1500;
BA_REL_ "GenSigTimeoutTime" BU_SG_REL_ Kombi_LB SG_ 1122 PSD_Fahrspuren_Anzahl 1500;
BA_REL_ "GenSigTimeoutTime" BU_SG_REL_ Kombi_LB SG_ 1122 PSD_Bebauung 1500;
BA_REL_ "GenSigTimeoutTime" BU_SG_REL_ Kombi_LB SG_ 1122 PSD_Segment_Komplett 1500;
BA_REL_ "GenSigTimeoutTime" BU_SG_REL_ Kombi_LB SG_ 1122 PSD_Rampe 1500;
BA_REL_ "GenSigTimeoutTime" BU_SG_REL_ Kombi_LB SG_ 1122 PSD_Anfangskruemmung 1500;
BA_REL_ "GenSigTimeoutTime" BU_SG_REL_ Kombi_LB SG_ 1122 PSD_Anfangskruemmung_Vorz 1500;
BA_REL_ "GenSigTimeoutTime" BU_SG_REL_ Kombi_LB SG_ 1122 PSD_Abzweigerichtung 1500;
BA_REL_ "GenSigTimeoutTime" BU_SG_REL_ Kombi_LB SG_ 1122 PSD_Abzweigewinkel 1500;
BA_REL_ "GenSigTimeoutTime" BU_SG_REL_ Kombi_LB SG_ 1123 PSD_Pos_Segment_ID 1500;
BA_REL_ "GenSigTimeoutTime" BU_SG_REL_ Kombi_LB SG_ 1123 PSD_Pos_Segmentlaenge 1500;
BA_REL_ "GenSigTimeoutTime" BU_SG_REL_ Kombi_LB SG_ 1123 PSD_Pos_Inhibitzeit 1500;
BA_REL_ "GenSigTimeoutTime" BU_SG_REL_ Kombi_LB SG_ 1123 PSD_Pos_Standort_Eindeutig 1500;
BA_REL_ "GenSigTimeoutTime" BU_SG_REL_ Kombi_LB SG_ 1123 PSD_Pos_Fehler_Laengsrichtung 1500;
BA_REL_ "GenSigTimeoutTime" BU_SG_REL_ Kombi_LB SG_ 1123 PSD_Pos_Fahrspur 1500;
BA_REL_ "GenSigTimeoutTime" BU_SG_REL_ Kombi_LB SG_ 1123 PSD_Attribut_Segment_ID_05 1500;
BA_REL_ "GenSigTimeoutTime" BU_SG_REL_ Kombi_LB SG_ 1123 PSD_Attribut_1_ID 1500;
BA_REL_ "GenSigTimeoutTime" BU_SG_REL_ Kombi_LB SG_ 1123 PSD_Attribut_1_Wert 1500;
BA_REL_ "GenSigTimeoutTime" BU_SG_REL_ Kombi_LB SG_ 1123 PSD_Attribut_1_Offset 1500;
BA_REL_ "GenSigTimeoutTime" BU_SG_REL_ Kombi_LB SG_ 1123 PSD_Attribut_2_ID 1500;
BA_REL_ "GenSigTimeoutTime" BU_SG_REL_ Kombi_LB SG_ 1123 PSD_Attribut_2_Wert 1500;
BA_REL_ "GenSigTimeoutTime" BU_SG_REL_ Kombi_LB SG_ 1123 PSD_Attribut_2_Offset 1500;
BA_REL_ "GenSigTimeoutTime" BU_SG_REL_ Kombi_LB SG_ 1123 PSD_Attribute_Komplett_05 1500;
BA_REL_ "GenSigTimeoutTime" BU_SG_REL_ Kombi_LB SG_ 1124 PSD_06_Mux 1500;
BA_REL_ "GenSigTimeoutTime" BU_SG_REL_ Kombi_LB SG_ 1124 PSD_Sys_Segment_ID 1500;
BA_REL_ "GenSigTimeoutTime" BU_SG_REL_ Kombi_LB SG_ 1124 PSD_Attribut_Segment_ID 1500;
BA_REL_ "GenSigTimeoutTime" BU_SG_REL_ Kombi_LB SG_ 1124 PSD_Ges_Segment_ID 1500;
BA_REL_ "GenSigTimeoutTime" BU_SG_REL_ Kombi_LB SG_ 1124 PSD_Baum_Laenge_VZ 1500;
BA_REL_ "GenSigTimeoutTime" BU_SG_REL_ Kombi_LB SG_ 1124 PSD_Steigung_1_Segment_ID 1500;
BA_REL_ "GenSigTimeoutTime" BU_SG_REL_ Kombi_LB SG_ 1124 PSD_Baum_Laenge 1500;
BA_REL_ "GenSigTimeoutTime" BU_SG_REL_ Kombi_LB SG_ 1124 PSD_Sys_Laendercode 1500;
BA_REL_ "GenSigTimeoutTime" BU_SG_REL_ Kombi_LB SG_ 1124 PSD_Attribut_3_ID 1500;
BA_REL_ "GenSigTimeoutTime" BU_SG_REL_ Kombi_LB SG_ 1124 PSD_Ges_Offset 1500;
BA_REL_ "GenSigTimeoutTime" BU_SG_REL_ Kombi_LB SG_ 1124 PSD_Steigung_1_A_Steigung 1500;
BA_REL_ "GenSigTimeoutTime" BU_SG_REL_ Kombi_LB SG_ 1124 PSD_Attribut_3_Offset 1500;
BA_REL_ "GenSigTimeoutTime" BU_SG_REL_ Kombi_LB SG_ 1124 PSD_Ges_Geschwindigkeit 1500;
BA_REL_ "GenSigTimeoutTime" BU_SG_REL_ Kombi_LB SG_ 1124 PSD_Steigung_1_A_Vorz 1500;
BA_REL_ "GenSigTimeoutTime" BU_SG_REL_ Kombi_LB SG_ 1124 PSD_Sys_Geschwindigkeit_Einheit 1500;
BA_REL_ "GenSigTimeoutTime" BU_SG_REL_ Kombi_LB SG_ 1124 PSD_Steigung_1_A_Offset 1500;
BA_REL_ "GenSigTimeoutTime" BU_SG_REL_ Kombi_LB SG_ 1124 PSD_Sys_Verkehrsrichtung 1500;
BA_REL_ "GenSigTimeoutTime" BU_SG_REL_ Kombi_LB SG_ 1124 PSD_Sys_Geometrieguete 1500;
BA_REL_ "GenSigTimeoutTime" BU_SG_REL_ Kombi_LB SG_ 1124 PSD_Sys_Mapmatchingguete 1500;
BA_REL_ "GenSigTimeoutTime" BU_SG_REL_ Kombi_LB SG_ 1124 PSD_Attribut_3_Wert 1500;
BA_REL_ "GenSigTimeoutTime" BU_SG_REL_ Kombi_LB SG_ 1124 PSD_Ges_Typ 1500;
BA_REL_ "GenSigTimeoutTime" BU_SG_REL_ Kombi_LB SG_ 1124 PSD_Sys_Alter_Karte 1500;
BA_REL_ "GenSigTimeoutTime" BU_SG_REL_ Kombi_LB SG_ 1124 PSD_Ges_Spur_Geschw_Begrenzung 1500;
BA_REL_ "GenSigTimeoutTime" BU_SG_REL_ Kombi_LB SG_ 1124 PSD_Steigung_1_B_Steigung 1500;
BA_REL_ "GenSigTimeoutTime" BU_SG_REL_ Kombi_LB SG_ 1124 PSD_Attribut_4_ID 1500;
BA_REL_ "GenSigTimeoutTime" BU_SG_REL_ Kombi_LB SG_ 1124 PSD_Sys_Zielfuehrung 1500;
BA_REL_ "GenSigTimeoutTime" BU_SG_REL_ Kombi_LB SG_ 1124 PSD_Sys_US_State 1500;
BA_REL_ "GenSigTimeoutTime" BU_SG_REL_ Kombi_LB SG_ 1124 PSD_Ges_Geschwindigkeit_Gespann 1500;
BA_REL_ "GenSigTimeoutTime" BU_SG_REL_ Kombi_LB SG_ 1124 PSD_Baum_Breite_VZ 1500;
BA_REL_ "GenSigTimeoutTime" BU_SG_REL_ Kombi_LB SG_ 1124 PSD_Attribut_4_Wert 1500;
BA_REL_ "GenSigTimeoutTime" BU_SG_REL_ Kombi_LB SG_ 1124 PSD_Baum_Breite 1500;
BA_REL_ "GenSigTimeoutTime" BU_SG_REL_ Kombi_LB SG_ 1124 PSD_Ges_Geschwindigkeit_Witter 1500;
BA_REL_ "GenSigTimeoutTime" BU_SG_REL_ Kombi_LB SG_ 1124 PSD_Steigung_1_B_Vorz 1500;
BA_REL_ "GenSigTimeoutTime" BU_SG_REL_ Kombi_LB SG_ 1124 PSD_Steigung_1_B_Offset 1500;
BA_REL_ "GenSigTimeoutTime" BU_SG_REL_ Kombi_LB SG_ 1124 PSD_Ges_Geschwindigkeit_Tag_Anf 1500;
BA_REL_ "GenSigTimeoutTime" BU_SG_REL_ Kombi_LB SG_ 1124 PSD_Attribut_4_Offset 1500;
BA_REL_ "GenSigTimeoutTime" BU_SG_REL_ Kombi_LB SG_ 1124 PSD_Ges_Geschwindigkeit_Tag_Ende 1500;
BA_REL_ "GenSigTimeoutTime" BU_SG_REL_ Kombi_LB SG_ 1124 PSD_Ges_Geschwindigkeit_Std_Anf 1500;
BA_REL_ "GenSigTimeoutTime" BU_SG_REL_ Kombi_LB SG_ 1124 PSD_Steigung_1_Attribute_kompl 1500;
BA_REL_ "GenSigTimeoutTime" BU_SG_REL_ Kombi_LB SG_ 1124 PSD_Steigung_2_Segment_ID 1500;
BA_REL_ "GenSigTimeoutTime" BU_SG_REL_ Kombi_LB SG_ 1124 PSD_Attribut_5_ID 1500;
BA_REL_ "GenSigTimeoutTime" BU_SG_REL_ Kombi_LB SG_ 1124 PSD_Ges_Geschwindigkeit_Std_Ende 1500;
BA_REL_ "GenSigTimeoutTime" BU_SG_REL_ Kombi_LB SG_ 1124 PSD_Attribut_5_Offset 1500;
BA_REL_ "GenSigTimeoutTime" BU_SG_REL_ Kombi_LB SG_ 1124 PSD_Steigung_2_Steigung 1500;
BA_REL_ "GenSigTimeoutTime" BU_SG_REL_ Kombi_LB SG_ 1124 PSD_Ges_Ueberholverbot 1500;
BA_REL_ "GenSigTimeoutTime" BU_SG_REL_ Kombi_LB SG_ 1124 PSD_Ges_Wechselverkehrszeichen 1500;
BA_REL_ "GenSigTimeoutTime" BU_SG_REL_ Kombi_LB SG_ 1124 PSD_Attribut_5_Wert 1500;
BA_REL_ "GenSigTimeoutTime" BU_SG_REL_ Kombi_LB SG_ 1124 PSD_Steigung_2_Vorz 1500;
BA_REL_ "GenSigTimeoutTime" BU_SG_REL_ Kombi_LB SG_ 1124 PSD_Wechselverkehrszeichen_Typ 1500;
BA_REL_ "GenSigTimeoutTime" BU_SG_REL_ Kombi_LB SG_ 1124 PSD_Baum_Ausrichtung 1500;
BA_REL_ "GenSigTimeoutTime" BU_SG_REL_ Kombi_LB SG_ 1124 PSD_Steigung_2_Offset 1500;
BA_REL_ "GenSigTimeoutTime" BU_SG_REL_ Kombi_LB SG_ 1124 PSD_Ges_Gesetzlich_Kategorie 1500;
BA_REL_ "GenSigTimeoutTime" BU_SG_REL_ Kombi_LB SG_ 1124 PSD_Attribute_Komplett_06 1500;
BA_REL_ "GenSigTimeoutTime" BU_SG_REL_ Kombi_LB SG_ 1124 PSD_Ges_Gesetzlich_Zusatz 1500;
BA_REL_ "GenSigTimeoutTime" BU_SG_REL_ Kombi_LB SG_ 1124 PSD_Ges_Verkehrszeichen_Quelle 1500;
BA_REL_ "GenSigTimeoutTime" BU_SG_REL_ Kombi_LB SG_ 1124 PSD_Steigung_2_Attribute_kompl 1500;
BA_REL_ "GenSigTimeoutTime" BU_SG_REL_ Kombi_LB SG_ 1124 PSD_Ges_Attribute_Komplett 1500;
BA_REL_ "GenSigTimeoutTime" BU_SG_REL_ Kombi_LB SG_ 1616 RA_Frequency_unit 5000;
BA_REL_ "GenSigTimeoutTime" BU_SG_REL_ Kombi_LB SG_ 1616 RA_AM_Tuning 5000;
BA_REL_ "GenSigTimeoutTime" BU_SG_REL_ Kombi_LB SG_ 1529 RDK_FMVSS138_Lampe 3200;
BA_REL_ "GenSigTimeoutTime" BU_SG_REL_ Kombi_LB SG_ 1529 RDK_FMVSS138_MIL 3200;
BA_REL_ "GenSigTimeoutTime" BU_SG_REL_ Kombi_LB SG_ 1529 RDK_Reifendruck_Lampe 3200;
BA_REL_ "GenSigTimeoutTime" BU_SG_REL_ Kombi_LB SG_ 1529 RDK_Warnungen_02 3200;
BA_REL_ "GenSigTimeoutTime" BU_SG_REL_ Kombi_LB SG_ 1529 RDK_Reifentemperatur_Lampe 3200;
BA_REL_ "GenSigTimeoutTime" BU_SG_REL_ Kombi_LB SG_ 1529 RDK_W_1_Reifen_HL 3200;
BA_REL_ "GenSigTimeoutTime" BU_SG_REL_ Kombi_LB SG_ 1529 RDK_W_1_Reifen_HR 3200;
BA_REL_ "GenSigTimeoutTime" BU_SG_REL_ Kombi_LB SG_ 1529 RDK_W_1_Reifen_VL 3200;
BA_REL_ "GenSigTimeoutTime" BU_SG_REL_ Kombi_LB SG_ 1529 RDK_W_1_Reifen_VR 3200;
BA_REL_ "GenSigTimeoutTime" BU_SG_REL_ Kombi_LB SG_ 1529 RDK_W_2_Reifen_HL 3200;
BA_REL_ "GenSigTimeoutTime" BU_SG_REL_ Kombi_LB SG_ 1529 RDK_W_2_Reifen_HR 3200;
BA_REL_ "GenSigTimeoutTime" BU_SG_REL_ Kombi_LB SG_ 1529 RDK_W_2_Reifen_VL 3200;
BA_REL_ "GenSigTimeoutTime" BU_SG_REL_ Kombi_LB SG_ 1529 RDK_W_2_Reifen_VR 3200;
BA_REL_ "GenSigTimeoutTime" BU_SG_REL_ Kombi_LB SG_ 1525 RW_Gesamt_Reichweite_Max_Anzeige 5000;
BA_REL_ "GenSigTimeoutTime" BU_SG_REL_ Kombi_LB SG_ 1525 RW_Reservewarnung_2_aktiv 5000;
BA_REL_ "GenSigTimeoutTime" BU_SG_REL_ Kombi_LB SG_ 1525 RW_Gesamt_Reichweite 5000;
BA_REL_ "GenSigTimeoutTime" BU_SG_REL_ Kombi_LB SG_ 1525 RW_Prim_Reichweitenverbrauch 5000;
BA_REL_ "GenSigTimeoutTime" BU_SG_REL_ Kombi_LB SG_ 1525 RW_Prim_Reichweitenv_Einheit 5000;
BA_REL_ "GenSigTimeoutTime" BU_SG_REL_ Kombi_LB SG_ 1525 RW_Primaer_Reichweite 5000;
BA_REL_ "GenSigTimeoutTime" BU_SG_REL_ Kombi_LB SG_ 1527 RW_Texte 5000;
BA_REL_ "GenSigTimeoutTime" BU_SG_REL_ Kombi_LB SG_ 1527 RW_Reservewarnung_aktiv 5000;
BA_REL_ "GenSigTimeoutTime" BU_SG_REL_ Kombi_LB SG_ 1527 RW_Reichweite_Einheit_Anzeige 5000;
BA_REL_ "GenSigTimeoutTime" BU_SG_REL_ Kombi_LB SG_ 1527 RW_Gesamt_Reichweite_Anzeige 5000;
BA_REL_ "GenSigTimeoutTime" BU_SG_REL_ Kombi_LB SG_ 1527 RW_Primaer_Reichweite_Anzeige 5000;
BA_REL_ "GenSigTimeoutTime" BU_SG_REL_ Kombi_LB SG_ 1527 RW_Sekundaer_Reichweite_Anzeige 5000;
BA_REL_ "GenSigTimeoutTime" BU_SG_REL_ Kombi_LB SG_ 1527 RW_Sekundaer_Reichweite 5000;
BA_REL_ "GenSigTimeoutTime" BU_SG_REL_ Kombi_LB SG_ 1527 RW_Sek_Reichweitenv_Einheit 5000;
BA_REL_ "GenSigTimeoutTime" BU_SG_REL_ Kombi_LB SG_ 1527 RW_Sek_Reichweitenverbrauch 5000;
BA_REL_ "GenSigTimeoutTime" BU_SG_REL_ Kombi_LB SG_ 2527679676 RW_Prim_rRWB_Reichw_Max_Ges_Anz 5000;
BA_REL_ "GenSigTimeoutTime" BU_SG_REL_ Kombi_LB SG_ 2527679676 RW_Prim_rRWB_aktiv 5000;
BA_REL_ "GenSigTimeoutTime" BU_SG_REL_ Kombi_LB SG_ 2527679676 RW_Prim_rRWB_Reichw_Anz 5000;
BA_REL_ "GenSigTimeoutTime" BU_SG_REL_ Kombi_LB SG_ 2527679676 RW_Prim_rRWB_Reichw_Gesamt_Anz 5000;
BA_REL_ "GenSigTimeoutTime" BU_SG_REL_ Kombi_LB SG_ 2527679676 RW_Prim_statische_Reichw_Anz 5000;
BA_REL_ "GenSigTimeoutTime" BU_SG_REL_ Kombi_LB SG_ 2527679676 RW_Prim_rRWB_Reichw_Rest_E_Anz 5000;
BA_REL_ "GenSigTimeoutTime" BU_SG_REL_ Kombi_LB SG_ 1440 RS_defekt 2000;
BA_REL_ "GenSigTimeoutTime" BU_SG_REL_ Kombi_LB SG_ 2527679790 RTM_IstModus 5000;
BA_REL_ "GenSigTimeoutTime" BU_SG_REL_ Kombi_LB SG_ 424 SARA_Accel_X_r 500;
BA_REL_ "GenSigTimeoutTime" BU_SG_REL_ Kombi_LB SG_ 424 SARA_Accel_Y_r 500;
BA_REL_ "GenSigTimeoutTime" BU_SG_REL_ Kombi_LB SG_ 424 SARA_CF_Accel_X_r 500;
BA_REL_ "GenSigTimeoutTime" BU_SG_REL_ Kombi_LB SG_ 424 SARA_CF_Accel_Y_r 500;
BA_REL_ "GenSigTimeoutTime" BU_SG_REL_ Kombi_LB SG_ 784 SCU_02_CRC 1200;
BA_REL_ "GenSigTimeoutTime" BU_SG_REL_ Kombi_LB SG_ 784 SCU_02_BZ 1200;
BA_REL_ "GenSigTimeoutTime" BU_SG_REL_ Kombi_LB SG_ 784 SCU_Warnungen 1200;
BA_REL_ "GenSigTimeoutTime" BU_SG_REL_ Kombi_PAG SG_ 1355 PH_Verschmutzungsmeldung 5000;
BA_REL_ "GenSigTimeoutTime" BU_SG_REL_ Kombi_PAG SG_ 803 SC_WarnBrems_Texte 2000;
BA_REL_ "GenSigTimeoutTime" BU_SG_REL_ Kombi_PAG SG_ 803 SC_AbstWarn_Texte 2000;
BA_REL_ "GenSigTimeoutTime" BU_SG_REL_ Kombi_PAG SG_ 2527679498 Perso_Kontonummer 5000;
BA_REL_ "GenSigTimeoutTime" BU_SG_REL_ Kombi_PAG SG_ 2527679498 Perso_Steuerung 5000;
BA_REL_ "GenSigTimeoutTime" BU_SG_REL_ Kombi_PAG SG_ 2527679498 Perso_Steuerungsparameter 5000;
BA_REL_ "GenSigTimeoutTime" BU_SG_REL_ Kombi_PAG SG_ 2527679498 Perso_Status 5000;
BA_REL_ "GenSigTimeoutTime" BU_SG_REL_ Kombi_PAG SG_ 2527679498 IAA_Active_User_ID 5000;
BA_REL_ "GenSigTimeoutTime" BU_SG_REL_ Kombi_PAG SG_ 2527679498 IAA_Identified_User_ID 5000;
BA_REL_ "GenSigTimeoutTime" BU_SG_REL_ Kombi_PAG SG_ 398 PLA2_Anf_Meldungen_FA 1000;
BA_REL_ "GenSigTimeoutTime" BU_SG_REL_ Kombi_PAG SG_ 398 PLA2_Anf_Meldungen_MA 1000;
BA_REL_ "GenSigTimeoutTime" BU_SG_REL_ Kombi_PAG SG_ 398 PLA2_Status_Aktive_Seite 1000;
BA_REL_ "GenSigTimeoutTime" BU_SG_REL_ Kombi_PAG SG_ 398 PLA2_Anf_Anzeige_Mini 1000;
BA_REL_ "GenSigTimeoutTime" BU_SG_REL_ Kombi_PAG SG_ 398 PLA2_Anf_Anzeige_Schwellpfeil 1000;
BA_REL_ "GenSigTimeoutTime" BU_SG_REL_ Kombi_PAG SG_ 398 PLA2_Anf_Akustik 1000;
BA_REL_ "GenSigTimeoutTime" BU_SG_REL_ Kombi_PAG SG_ 398 PLA2_Mini_Modus 1000;
BA_REL_ "GenSigTimeoutTime" BU_SG_REL_ Kombi_PAG SG_ 398 PLA2_Anf_Anzeige_Bremsfuss 1000;
BA_REL_ "GenSigTimeoutTime" BU_SG_REL_ Kombi_PAG SG_ 398 PLA2_Anf_Anzeigemodus 1000;
BA_REL_ "GenSigTimeoutTime" BU_SG_REL_ Kombi_PAG SG_ 398 PLA2_Anf_Meldungen 1000;
BA_REL_ "GenSigTimeoutTime" BU_SG_REL_ Kombi_PAG SG_ 398 PLA2_Anzahl_Seg_Schwellpfeil 1000;
BA_REL_ "GenSigTimeoutTime" BU_SG_REL_ Kombi_PAG SG_ 398 PLA2_Status_Funktion 1000;
BA_REL_ "GenSigTimeoutTime" BU_SG_REL_ Kombi_PAG SG_ 1166 PLA_Status_Aktive_Seite 1000;
BA_REL_ "GenSigTimeoutTime" BU_SG_REL_ Kombi_PAG SG_ 1166 PLA_Anf_Anzeige_Mini 1000;
BA_REL_ "GenSigTimeoutTime" BU_SG_REL_ Kombi_PAG SG_ 1166 PLA_Mini_Modus 1000;
BA_REL_ "GenSigTimeoutTime" BU_SG_REL_ Kombi_PAG SG_ 1166 PLA_Anf_Akustik 1000;
BA_REL_ "GenSigTimeoutTime" BU_SG_REL_ Kombi_PAG SG_ 1166 PLA_Anf_Anzeige_Schwellpfeil 1000;
BA_REL_ "GenSigTimeoutTime" BU_SG_REL_ Kombi_PAG SG_ 1166 PLA_Anf_Anzeige_Bremsfuss 1000;
BA_REL_ "GenSigTimeoutTime" BU_SG_REL_ Kombi_PAG SG_ 1166 PLA_Anf_Anzeigemodus 1000;
BA_REL_ "GenSigTimeoutTime" BU_SG_REL_ Kombi_PAG SG_ 1166 PLA_Anf_Meldungen 1000;
BA_REL_ "GenSigTimeoutTime" BU_SG_REL_ Kombi_PAG SG_ 1166 PLA_Anzahl_Segmente_Schwellpfeil 1000;
BA_REL_ "GenSigTimeoutTime" BU_SG_REL_ Kombi_PAG SG_ 1166 PLA_Status_Funktion 1000;
BA_REL_ "GenSigTimeoutTime" BU_SG_REL_ Kombi_PAG SG_ 319 SC_PreCrash_LED 2000;
BA_REL_ "GenSigTimeoutTime" BU_SG_REL_ Kombi_PAG SG_ 319 SC_PreCrash_Warnung 2000;
BA_REL_ "GenSigTimeoutTime" BU_SG_REL_ Kombi_PAG SG_ 319 SC_PreCrash_Texte 2000;
BA_REL_ "GenSigTimeoutTime" BU_SG_REL_ Kombi_PAG SG_ 1122 PSD_Segment_ID 1500;
BA_REL_ "GenSigTimeoutTime" BU_SG_REL_ Kombi_PAG SG_ 1122 PSD_Vorgaenger_Segment_ID 1500;
BA_REL_ "GenSigTimeoutTime" BU_SG_REL_ Kombi_PAG SG_ 1122 PSD_Segmentlaenge 1500;
BA_REL_ "GenSigTimeoutTime" BU_SG_REL_ Kombi_PAG SG_ 1122 PSD_Strassenkategorie 1500;
BA_REL_ "GenSigTimeoutTime" BU_SG_REL_ Kombi_PAG SG_ 1122 PSD_Endkruemmung 1500;
BA_REL_ "GenSigTimeoutTime" BU_SG_REL_ Kombi_PAG SG_ 1122 PSD_Endkruemmung_Vorz 1500;
BA_REL_ "GenSigTimeoutTime" BU_SG_REL_ Kombi_PAG SG_ 1122 PSD_Idenditaets_ID 1500;
BA_REL_ "GenSigTimeoutTime" BU_SG_REL_ Kombi_PAG SG_ 1122 PSD_ADAS_Qualitaet 1500;
BA_REL_ "GenSigTimeoutTime" BU_SG_REL_ Kombi_PAG SG_ 1122 PSD_wahrscheinlichster_Pfad 1500;
BA_REL_ "GenSigTimeoutTime" BU_SG_REL_ Kombi_PAG SG_ 1122 PSD_Geradester_Pfad 1500;
BA_REL_ "GenSigTimeoutTime" BU_SG_REL_ Kombi_PAG SG_ 1122 PSD_Fahrspuren_Anzahl 1500;
BA_REL_ "GenSigTimeoutTime" BU_SG_REL_ Kombi_PAG SG_ 1122 PSD_Bebauung 1500;
BA_REL_ "GenSigTimeoutTime" BU_SG_REL_ Kombi_PAG SG_ 1122 PSD_Segment_Komplett 1500;
BA_REL_ "GenSigTimeoutTime" BU_SG_REL_ Kombi_PAG SG_ 1122 PSD_Rampe 1500;
BA_REL_ "GenSigTimeoutTime" BU_SG_REL_ Kombi_PAG SG_ 1122 PSD_Anfangskruemmung 1500;
BA_REL_ "GenSigTimeoutTime" BU_SG_REL_ Kombi_PAG SG_ 1122 PSD_Anfangskruemmung_Vorz 1500;
BA_REL_ "GenSigTimeoutTime" BU_SG_REL_ Kombi_PAG SG_ 1122 PSD_Abzweigerichtung 1500;
BA_REL_ "GenSigTimeoutTime" BU_SG_REL_ Kombi_PAG SG_ 1122 PSD_Abzweigewinkel 1500;
BA_REL_ "GenSigTimeoutTime" BU_SG_REL_ Kombi_PAG SG_ 1123 PSD_Pos_Segment_ID 1500;
BA_REL_ "GenSigTimeoutTime" BU_SG_REL_ Kombi_PAG SG_ 1123 PSD_Pos_Segmentlaenge 1500;
BA_REL_ "GenSigTimeoutTime" BU_SG_REL_ Kombi_PAG SG_ 1123 PSD_Pos_Inhibitzeit 1500;
BA_REL_ "GenSigTimeoutTime" BU_SG_REL_ Kombi_PAG SG_ 1123 PSD_Pos_Standort_Eindeutig 1500;
BA_REL_ "GenSigTimeoutTime" BU_SG_REL_ Kombi_PAG SG_ 1123 PSD_Pos_Fehler_Laengsrichtung 1500;
BA_REL_ "GenSigTimeoutTime" BU_SG_REL_ Kombi_PAG SG_ 1123 PSD_Pos_Fahrspur 1500;
BA_REL_ "GenSigTimeoutTime" BU_SG_REL_ Kombi_PAG SG_ 1123 PSD_Attribut_Segment_ID_05 1500;
BA_REL_ "GenSigTimeoutTime" BU_SG_REL_ Kombi_PAG SG_ 1123 PSD_Attribut_1_ID 1500;
BA_REL_ "GenSigTimeoutTime" BU_SG_REL_ Kombi_PAG SG_ 1123 PSD_Attribut_1_Wert 1500;
BA_REL_ "GenSigTimeoutTime" BU_SG_REL_ Kombi_PAG SG_ 1123 PSD_Attribut_1_Offset 1500;
BA_REL_ "GenSigTimeoutTime" BU_SG_REL_ Kombi_PAG SG_ 1123 PSD_Attribut_2_ID 1500;
BA_REL_ "GenSigTimeoutTime" BU_SG_REL_ Kombi_PAG SG_ 1123 PSD_Attribut_2_Wert 1500;
BA_REL_ "GenSigTimeoutTime" BU_SG_REL_ Kombi_PAG SG_ 1123 PSD_Attribut_2_Offset 1500;
BA_REL_ "GenSigTimeoutTime" BU_SG_REL_ Kombi_PAG SG_ 1123 PSD_Attribute_Komplett_05 1500;
BA_REL_ "GenSigTimeoutTime" BU_SG_REL_ Kombi_PAG SG_ 1124 PSD_06_Mux 1500;
BA_REL_ "GenSigTimeoutTime" BU_SG_REL_ Kombi_PAG SG_ 1124 PSD_Sys_Segment_ID 1500;
BA_REL_ "GenSigTimeoutTime" BU_SG_REL_ Kombi_PAG SG_ 1124 PSD_Attribut_Segment_ID 1500;
BA_REL_ "GenSigTimeoutTime" BU_SG_REL_ Kombi_PAG SG_ 1124 PSD_Ges_Segment_ID 1500;
BA_REL_ "GenSigTimeoutTime" BU_SG_REL_ Kombi_PAG SG_ 1124 PSD_Baum_Laenge_VZ 1500;
BA_REL_ "GenSigTimeoutTime" BU_SG_REL_ Kombi_PAG SG_ 1124 PSD_Steigung_1_Segment_ID 1500;
BA_REL_ "GenSigTimeoutTime" BU_SG_REL_ Kombi_PAG SG_ 1124 PSD_Baum_Laenge 1500;
BA_REL_ "GenSigTimeoutTime" BU_SG_REL_ Kombi_PAG SG_ 1124 PSD_Sys_Laendercode 1500;
BA_REL_ "GenSigTimeoutTime" BU_SG_REL_ Kombi_PAG SG_ 1124 PSD_Attribut_3_ID 1500;
BA_REL_ "GenSigTimeoutTime" BU_SG_REL_ Kombi_PAG SG_ 1124 PSD_Ges_Offset 1500;
BA_REL_ "GenSigTimeoutTime" BU_SG_REL_ Kombi_PAG SG_ 1124 PSD_Steigung_1_A_Steigung 1500;
BA_REL_ "GenSigTimeoutTime" BU_SG_REL_ Kombi_PAG SG_ 1124 PSD_Attribut_3_Offset 1500;
BA_REL_ "GenSigTimeoutTime" BU_SG_REL_ Kombi_PAG SG_ 1124 PSD_Ges_Geschwindigkeit 1500;
BA_REL_ "GenSigTimeoutTime" BU_SG_REL_ Kombi_PAG SG_ 1124 PSD_Steigung_1_A_Vorz 1500;
BA_REL_ "GenSigTimeoutTime" BU_SG_REL_ Kombi_PAG SG_ 1124 PSD_Sys_Geschwindigkeit_Einheit 1500;
BA_REL_ "GenSigTimeoutTime" BU_SG_REL_ Kombi_PAG SG_ 1124 PSD_Steigung_1_A_Offset 1500;
BA_REL_ "GenSigTimeoutTime" BU_SG_REL_ Kombi_PAG SG_ 1124 PSD_Sys_Verkehrsrichtung 1500;
BA_REL_ "GenSigTimeoutTime" BU_SG_REL_ Kombi_PAG SG_ 1124 PSD_Sys_Geometrieguete 1500;
BA_REL_ "GenSigTimeoutTime" BU_SG_REL_ Kombi_PAG SG_ 1124 PSD_Sys_Mapmatchingguete 1500;
BA_REL_ "GenSigTimeoutTime" BU_SG_REL_ Kombi_PAG SG_ 1124 PSD_Attribut_3_Wert 1500;
BA_REL_ "GenSigTimeoutTime" BU_SG_REL_ Kombi_PAG SG_ 1124 PSD_Ges_Typ 1500;
BA_REL_ "GenSigTimeoutTime" BU_SG_REL_ Kombi_PAG SG_ 1124 PSD_Sys_Alter_Karte 1500;
BA_REL_ "GenSigTimeoutTime" BU_SG_REL_ Kombi_PAG SG_ 1124 PSD_Ges_Spur_Geschw_Begrenzung 1500;
BA_REL_ "GenSigTimeoutTime" BU_SG_REL_ Kombi_PAG SG_ 1124 PSD_Steigung_1_B_Steigung 1500;
BA_REL_ "GenSigTimeoutTime" BU_SG_REL_ Kombi_PAG SG_ 1124 PSD_Attribut_4_ID 1500;
BA_REL_ "GenSigTimeoutTime" BU_SG_REL_ Kombi_PAG SG_ 1124 PSD_Sys_Zielfuehrung 1500;
BA_REL_ "GenSigTimeoutTime" BU_SG_REL_ Kombi_PAG SG_ 1124 PSD_Sys_US_State 1500;
BA_REL_ "GenSigTimeoutTime" BU_SG_REL_ Kombi_PAG SG_ 1124 PSD_Ges_Geschwindigkeit_Gespann 1500;
BA_REL_ "GenSigTimeoutTime" BU_SG_REL_ Kombi_PAG SG_ 1124 PSD_Baum_Breite_VZ 1500;
BA_REL_ "GenSigTimeoutTime" BU_SG_REL_ Kombi_PAG SG_ 1124 PSD_Attribut_4_Wert 1500;
BA_REL_ "GenSigTimeoutTime" BU_SG_REL_ Kombi_PAG SG_ 1124 PSD_Baum_Breite 1500;
BA_REL_ "GenSigTimeoutTime" BU_SG_REL_ Kombi_PAG SG_ 1124 PSD_Ges_Geschwindigkeit_Witter 1500;
BA_REL_ "GenSigTimeoutTime" BU_SG_REL_ Kombi_PAG SG_ 1124 PSD_Steigung_1_B_Vorz 1500;
BA_REL_ "GenSigTimeoutTime" BU_SG_REL_ Kombi_PAG SG_ 1124 PSD_Steigung_1_B_Offset 1500;
BA_REL_ "GenSigTimeoutTime" BU_SG_REL_ Kombi_PAG SG_ 1124 PSD_Ges_Geschwindigkeit_Tag_Anf 1500;
BA_REL_ "GenSigTimeoutTime" BU_SG_REL_ Kombi_PAG SG_ 1124 PSD_Attribut_4_Offset 1500;
BA_REL_ "GenSigTimeoutTime" BU_SG_REL_ Kombi_PAG SG_ 1124 PSD_Ges_Geschwindigkeit_Tag_Ende 1500;
BA_REL_ "GenSigTimeoutTime" BU_SG_REL_ Kombi_PAG SG_ 1124 PSD_Ges_Geschwindigkeit_Std_Anf 1500;
BA_REL_ "GenSigTimeoutTime" BU_SG_REL_ Kombi_PAG SG_ 1124 PSD_Steigung_1_Attribute_kompl 1500;
BA_REL_ "GenSigTimeoutTime" BU_SG_REL_ Kombi_PAG SG_ 1124 PSD_Steigung_2_Segment_ID 1500;
BA_REL_ "GenSigTimeoutTime" BU_SG_REL_ Kombi_PAG SG_ 1124 PSD_Attribut_5_ID 1500;
BA_REL_ "GenSigTimeoutTime" BU_SG_REL_ Kombi_PAG SG_ 1124 PSD_Ges_Geschwindigkeit_Std_Ende 1500;
BA_REL_ "GenSigTimeoutTime" BU_SG_REL_ Kombi_PAG SG_ 1124 PSD_Attribut_5_Offset 1500;
BA_REL_ "GenSigTimeoutTime" BU_SG_REL_ Kombi_PAG SG_ 1124 PSD_Steigung_2_Steigung 1500;
BA_REL_ "GenSigTimeoutTime" BU_SG_REL_ Kombi_PAG SG_ 1124 PSD_Ges_Ueberholverbot 1500;
BA_REL_ "GenSigTimeoutTime" BU_SG_REL_ Kombi_PAG SG_ 1124 PSD_Ges_Wechselverkehrszeichen 1500;
BA_REL_ "GenSigTimeoutTime" BU_SG_REL_ Kombi_PAG SG_ 1124 PSD_Attribut_5_Wert 1500;
BA_REL_ "GenSigTimeoutTime" BU_SG_REL_ Kombi_PAG SG_ 1124 PSD_Steigung_2_Vorz 1500;
BA_REL_ "GenSigTimeoutTime" BU_SG_REL_ Kombi_PAG SG_ 1124 PSD_Wechselverkehrszeichen_Typ 1500;
BA_REL_ "GenSigTimeoutTime" BU_SG_REL_ Kombi_PAG SG_ 1124 PSD_Baum_Ausrichtung 1500;
BA_REL_ "GenSigTimeoutTime" BU_SG_REL_ Kombi_PAG SG_ 1124 PSD_Steigung_2_Offset 1500;
BA_REL_ "GenSigTimeoutTime" BU_SG_REL_ Kombi_PAG SG_ 1124 PSD_Ges_Gesetzlich_Kategorie 1500;
BA_REL_ "GenSigTimeoutTime" BU_SG_REL_ Kombi_PAG SG_ 1124 PSD_Attribute_Komplett_06 1500;
BA_REL_ "GenSigTimeoutTime" BU_SG_REL_ Kombi_PAG SG_ 1124 PSD_Ges_Gesetzlich_Zusatz 1500;
BA_REL_ "GenSigTimeoutTime" BU_SG_REL_ Kombi_PAG SG_ 1124 PSD_Ges_Verkehrszeichen_Quelle 1500;
BA_REL_ "GenSigTimeoutTime" BU_SG_REL_ Kombi_PAG SG_ 1124 PSD_Steigung_2_Attribute_kompl 1500;
BA_REL_ "GenSigTimeoutTime" BU_SG_REL_ Kombi_PAG SG_ 1124 PSD_Ges_Attribute_Komplett 1500;
BA_REL_ "GenSigTimeoutTime" BU_SG_REL_ Kombi_PAG SG_ 2463978730 pVS_vLimit_HMI 1000;
BA_REL_ "GenSigTimeoutTime" BU_SG_REL_ Kombi_PAG SG_ 2463978730 pVS_Hinweismeldung 1000;
BA_REL_ "GenSigTimeoutTime" BU_SG_REL_ Kombi_PAG SG_ 2463978730 pVS_vLimit_HMI_Unit 1000;
BA_REL_ "GenSigTimeoutTime" BU_SG_REL_ Kombi_PAG SG_ 2463978730 pVS_Note_SpeedAdjustment 1000;
BA_REL_ "GenSigTimeoutTime" BU_SG_REL_ Kombi_PAG SG_ 2463978730 pVS_IconActivation 1000;
BA_REL_ "GenSigTimeoutTime" BU_SG_REL_ Kombi_PAG SG_ 906 QSP_Warnlampe 1000;
BA_REL_ "GenSigTimeoutTime" BU_SG_REL_ Kombi_PAG SG_ 1339 QS_Warntexte 5000;
BA_REL_ "GenSigTimeoutTime" BU_SG_REL_ Kombi_PAG SG_ 1529 RDK_FMVSS138_Lampe 3200;
BA_REL_ "GenSigTimeoutTime" BU_SG_REL_ Kombi_PAG SG_ 1529 RDK_FMVSS138_MIL 3200;
BA_REL_ "GenSigTimeoutTime" BU_SG_REL_ Kombi_PAG SG_ 1529 RDK_Warnungen_02 3200;
BA_REL_ "GenSigTimeoutTime" BU_SG_REL_ Kombi_PAG SG_ 1529 RDK_angelernt 3200;
BA_REL_ "GenSigTimeoutTime" BU_SG_REL_ Kombi_PAG SG_ 1529 RDK_RS_aktiv 3200;
BA_REL_ "GenSigTimeoutTime" BU_SG_REL_ Kombi_PAG SG_ 1529 RDK_Text_7 3200;
BA_REL_ "GenSigTimeoutTime" BU_SG_REL_ Kombi_PAG SG_ 1529 RDK_W_1_Reifen_HL 3200;
BA_REL_ "GenSigTimeoutTime" BU_SG_REL_ Kombi_PAG SG_ 1529 RDK_W_1_Reifen_HR 3200;
BA_REL_ "GenSigTimeoutTime" BU_SG_REL_ Kombi_PAG SG_ 1529 RDK_W_1_Reifen_VL 3200;
BA_REL_ "GenSigTimeoutTime" BU_SG_REL_ Kombi_PAG SG_ 1529 RDK_W_1_Reifen_VR 3200;
BA_REL_ "GenSigTimeoutTime" BU_SG_REL_ Kombi_PAG SG_ 1529 RDK_W_2_Reifen_HL 3200;
BA_REL_ "GenSigTimeoutTime" BU_SG_REL_ Kombi_PAG SG_ 1529 RDK_W_2_Reifen_HR 3200;
BA_REL_ "GenSigTimeoutTime" BU_SG_REL_ Kombi_PAG SG_ 1529 RDK_W_2_Reifen_VL 3200;
BA_REL_ "GenSigTimeoutTime" BU_SG_REL_ Kombi_PAG SG_ 1529 RDK_W_2_Reifen_VR 3200;
BA_REL_ "GenSigTimeoutTime" BU_SG_REL_ Kombi_PAG SG_ 1525 RW_Gesamt_Reichweite_Max_Anzeige 5000;
BA_REL_ "GenSigTimeoutTime" BU_SG_REL_ Kombi_PAG SG_ 1525 RW_Gesamt_Reichweite 5000;
BA_REL_ "GenSigTimeoutTime" BU_SG_REL_ Kombi_PAG SG_ 1525 RW_Prim_Reichweitenverbrauch 5000;
BA_REL_ "GenSigTimeoutTime" BU_SG_REL_ Kombi_PAG SG_ 1525 RW_Prim_Reichweitenv_Einheit 5000;
BA_REL_ "GenSigTimeoutTime" BU_SG_REL_ Kombi_PAG SG_ 1525 RW_Primaer_Reichweite 5000;
BA_REL_ "GenSigTimeoutTime" BU_SG_REL_ Kombi_PAG SG_ 1527 RW_Tendenz 5000;
BA_REL_ "GenSigTimeoutTime" BU_SG_REL_ Kombi_PAG SG_ 1527 RW_Texte 5000;
BA_REL_ "GenSigTimeoutTime" BU_SG_REL_ Kombi_PAG SG_ 1527 RW_Reichweite_Einheit_Anzeige 5000;
BA_REL_ "GenSigTimeoutTime" BU_SG_REL_ Kombi_PAG SG_ 1527 RW_Gesamt_Reichweite_Anzeige 5000;
BA_REL_ "GenSigTimeoutTime" BU_SG_REL_ Kombi_PAG SG_ 1527 RW_Primaer_Reichweite_Anzeige 5000;
BA_REL_ "GenSigTimeoutTime" BU_SG_REL_ Kombi_PAG SG_ 1527 RW_Sekundaer_Reichweite_Anzeige 5000;
BA_REL_ "GenSigTimeoutTime" BU_SG_REL_ Kombi_PAG SG_ 1527 RW_Sekundaer_Reichweite 5000;
BA_REL_ "GenSigTimeoutTime" BU_SG_REL_ Kombi_PAG SG_ 1527 RW_Sek_Reichweitenv_Einheit 5000;
BA_REL_ "GenSigTimeoutTime" BU_SG_REL_ Kombi_PAG SG_ 1527 RW_Sek_Reichweitenverbrauch 5000;
BA_REL_ "GenSigTimeoutTime" BU_SG_REL_ Kombi_PAG SG_ 2527679676 RW_Prim_rRWB_Reichw_Max_Ges_Anz 5000;
BA_REL_ "GenSigTimeoutTime" BU_SG_REL_ Kombi_PAG SG_ 2527679676 RW_Prim_rRWB_aktiv 5000;
BA_REL_ "GenSigTimeoutTime" BU_SG_REL_ Kombi_PAG SG_ 2527679676 RW_Prim_rRWB_Reichw_Anz 5000;
BA_REL_ "GenSigTimeoutTime" BU_SG_REL_ Kombi_PAG SG_ 2527679676 RW_Prim_rRWB_Reichw_Gesamt_Anz 5000;
BA_REL_ "GenSigTimeoutTime" BU_SG_REL_ Kombi_PAG SG_ 2527679676 RW_Prim_statische_Reichw_Anz 5000;
BA_REL_ "GenSigTimeoutTime" BU_SG_REL_ Kombi_PAG SG_ 2527679676 RW_Prim_rRWB_Reichw_Rest_E_Anz 5000;
BA_REL_ "GenSigTimeoutTime" BU_SG_REL_ Kombi_PAG SG_ 1440 RS_defekt 2000;
BA_REL_ "GenSigTimeoutTime" BU_SG_REL_ Kombi_PAG SG_ 2527679790 RTM_IstModus 5000;
BA_REL_ "GenSigTimeoutTime" BU_SG_REL_ Kombi_PAG SG_ 1504 MD1_Position 5000;
BA_REL_ "GenSigTimeoutTime" BU_SG_REL_ Kombi_PAG SG_ 1504 MD1_Lage 5000;
BA_REL_ "GenSigTimeoutTime" BU_SG_REL_ Kombi_PAG SG_ 1504 SAD_normiert 5000;
BA_REL_ "GenSigTimeoutTime" BU_SG_REL_ Kombi_PAG SG_ 1504 SAD_Text 5000;
BA_REL_ "GenSigTimeoutTime" BU_SG_REL_ Kombi_PAG SG_ 424 SARA_Accel_X_r 500;
BA_REL_ "GenSigTimeoutTime" BU_SG_REL_ Kombi_PAG SG_ 424 SARA_Accel_Y_r 500;
BA_REL_ "GenSigTimeoutTime" BU_SG_REL_ Kombi_PAG SG_ 424 SARA_CF_Accel_X_r 500;
BA_REL_ "GenSigTimeoutTime" BU_SG_REL_ Kombi_PAG SG_ 424 SARA_CF_Accel_Y_r 500;
BA_REL_ "GenSigTimeoutTime" BU_SG_REL_ Kombi_PAG SG_ 784 SCU_02_CRC 1200;
BA_REL_ "GenSigTimeoutTime" BU_SG_REL_ Kombi_PAG SG_ 784 SCU_02_BZ 1200;
BA_REL_ "GenSigTimeoutTime" BU_SG_REL_ Kombi_PAG SG_ 784 SCU_Warnungen 1200;
BA_REL_ "GenSigTimeoutTime" BU_SG_REL_ Kombi_PAG SG_ 1363 SR3_Status_Lehne_Links 1000;
BA_REL_ "GenSigTimeoutTime" BU_SG_REL_ Kombi_PAG SG_ 1363 SR3_Status_Lehne_Rechts 1000;
VAL_ 1355 PH_Verschmutzungsmeldung 0 "keine_Anzeige_kein_Gong" 1 "Textmeldung_PDC_hinten_verschmutzt_mit_Gong" 2 "Textmeldung_PDC_hinten_verschmutzt_ohne_Gong" 3 "Textmeldung_PDC_vorn_verschmutzt_mit_Gong" 4 "Textmeldung_PDC_vorn_verschmutzt_ohne_Gong" 5 "Textmeldung_PDC_verschmutzt_mit_Gong" 6 "Textmeldung_PDC_verschmutzt_ohne_Gong" 7 "Textmeldung_PDC_seitlich_verschmutzt_mit_Gong" 8 "Textmeldung_PDC_seitlich_verschmutzt_ohne_Gong" ;
VAL_ 1355 PH_Aufschaltursache 0 "Anlage aus" 1 "Anlage durch einlegen R-Gang aktiviert" 2 "Anlage manuell durch Taster aktiviert" 3 "Anlage automatisch aktiviert" 4 "Anlage durch ARA aktiviert" 5 "Rueckwaertsrollen" 6 "Anlage_durch_PLA_aktiviert" 7 "Anlage_durch_IPA_aktiviert" 8 "Anlage_durch_FA_aktiviert" 9 "Anlage_durch_RBF_oder_MA_aktiviert" 10 "Anlage_durch_Smartphone_aktiviert" 11 "Anlage_durch_Jokertaste_aktiviert" 12 "Anlage_durch_Favoritentasten_aktiviert" 13 "Anlage_durch_SideViewTaster_aktiviert" 14 "Anlage_durch_RCTA_aktiviert" 15 "Anlage_durch_KAS_aktiviert" 16 "Anlage_durch_AWC_aktiviert" 30 "Init_Initialisierungsphase_nach_Kl_15_ein_oder_Reset" 31 "Fehler_gestoerter_Zustand_System_noch_aktiv" ;
VAL_ 1355 PH_Ton_Ausgabe 0 "Init" 1 "Intervallton_vorne" 2 "Intervallton_hinten" 3 "Dauerton_vorne" 4 "Dauerton_hinten" 5 "Quittierungston" 6 "Reserviert" 7 "Fehler" ;
VAL_ 1355 PH_Ton_Pausenlaenge 0 "Init" 1 "Pause_5ms" 2 "Pause_10ms" 3 "Pause_15ms" 100 "Pause_500ms" 101 "Reserviert" 126 "Reserviert" 127 "Fehler" ;
VAL_ 1355 PH_Ton_Richtung 0 "vorne" 1 "vorne_rechts" 2 "rechts" 3 "rechts_hinten" 4 "hinten" 5 "hinten_links" 6 "links" 7 "vorne_links" ;
VAL_ 1355 PH_Ton_Lautstaerke 0 "Minimallautstaerke" 1 "Lautstaerke_1" 2 "Lautstaerke_2" 3 "Lautstaerke_3" 4 "Lautstaerke_4" 5 "Lautstaerke_5" 6 "Lautstaerke_6" 7 "Maximallautstaerke" ;
VAL_ 1355 BCM_WAH_Meldung 0 "Init" 1 "Fehlermeldung_bei_Nichtverfuegbarkeit_mit_Gong" 2 "Fehlermeldung_bei_Nichtverfuegbarkeit_ohne_Gong" 3 "Anzeige_dass_Fahrzeug_erkannt_wurde_und_Funktion_aktiv_ist" 4 "Wiederanfahrhinweis_mit_Gong" 5 "Wiederanfahrhinweis_ohne_Gong" ;
VAL_ 1355 PDC_Charisma_Status 0 "Init" 1 "verfuegbar" 2 "nicht_verfuegbar" 3 "asynchron_durch_Fahrerwunsch" ;
VAL_ 1355 PDC_Charisma_FahrPr 0 "keine_Funktion" 1 "Programm_1" 2 "Programm_2" 3 "Programm_3" 4 "Programm_4" 5 "Programm_5" 6 "Programm_6" 7 "Programm_7" 8 "Programm_8" 9 "Programm_9" 10 "Programm_10" 11 "Programm_11" 12 "Programm_12" 13 "Programm_13" 14 "Programm_14" 15 "Programm_15" ;
VAL_ 803 SC_WarnBrems_Texte 0 "keine_Anzeige" 1 "Systemstoerung" 2 "keine_Sensorsicht" 3 "Demomodus" 4 "System_aus" 5 "Anhaengerbetrieb" 6 "ESC_aus" 7 "zurzeit_eingeschraenkt" 8 "zurzeit_eingeschraenkt_ESP_Aus" 9 "Initialisierung" ;
VAL_ 803 SC_AbstWarn_Texte 0 "keine_Anzeige" 1 "Systemstoerung" 2 "keine_Sensorsicht" 3 "Demomodus" 4 "System_aus" 5 "Anhaengerbetrieb" 6 "ESC_aus" 7 "zurzeit_eingeschraenkt" 8 "zurzeit_eingeschraenkt_ESP_Aus" 9 "Initialisierung" ;
VAL_ 803 PCF_Verz_Anf_ASIL 0 "Nicht_verfuegbar" 1 "Verz_Anf_ASIL_QM" 2 "Verz_Anf_ASIL_A" 3 "Verz_Anf_ASIL_B" 4 "Verz_Anf_ASIL_C" 5 "Verz_Anf_ASIL_D" 6 "reserved" 7 "reserved" ;
VAL_ 803 PCF_Verz_Auspraegung 0 "Standard" 1 "Erweitert" ;
VAL_ 803 PCF_Prefill_Anf 0 "Prefill_nicht_aktivieren" 1 "Prefill_aktivieren" ;
VAL_ 803 PCF_HBA_Param 0 "Defaultparametersatz" 1 "Param_leicht_erh_Empfindlichkeit" 2 "Param_erh_Empfindlichkeit" 3 "Param_hoechste_Empfindlichkeit" ;
VAL_ 803 PCF_Ruckprofil 0 "keine_Ruckanforderung" 1 "Profil_1" 2 "Profil_2" 3 "Profil_3" 4 "Profil_4" 5 "Profil_5" 6 "Profil_6" 7 "Profil_7" ;
VAL_ 803 PCF_Verz_Info 0 "keine_Anforderung" 1 "Teilbremsung_Stufe1" 2 "Teilbremsung_Stufe2" 3 "Zielbremsung_fahrergetriggert" 4 "Notbremsung_geregelt" 5 "Notbremsung_gesteuert" 6 "Abbiegebremsen_Angef" ;
VAL_ 803 PCF_Verz_Anf 834 "Init" ;
VAL_ 2527679498 Perso_Kontonummer 0 "kein_Benutzerkonto" 1 "Benutzerkonto_1" 2 "Benutzerkonto_2" 3 "Benutzerkonto_3" 4 "Benutzerkonto_4" 5 "Benutzerkonto_5" 6 "Benutzerkonto_6" 7 "Benutzerkonto_7" ;
VAL_ 2527679498 Perso_Steuerung 0 "keine_Steuerung" 1 "Reset_alle_Konten" 2 "Reset_aktives_Konto" 3 "Kopiere_aktives_Konto_nach" 4 "Wiederherstellen_aktives_Konto" 5 "Aktivieren_aktives_Konto" 6 "Reset_Konto" 7 "Reset_alle_Fahrer" 8 "Reset_aktiver_Fahrer" 9 "Reset_Fahrer" ;
VAL_ 2527679498 Perso_Steuerungsparameter 0 "kein_Parameter" 1 "Benutzerkonto_1" 2 "Benutzerkonto_2" 3 "Benutzerkonto_3" 4 "Benutzerkonto_4" 5 "Benutzerkonto_5" 6 "Benutzerkonto_6" 7 "Benutzerkonto_7" ;
VAL_ 2527679498 Perso_Status 0 "deaktiviert" 1 "PSO_1x_aktiviert" 2 "PSO_2x_aktiviert" ;
VAL_ 2527679498 Perso_Bedienstelle 0 "Init" 1 "Kombiinstrument" 2 "ABT" ;
VAL_ 2527679498 Perso_Freigabe_Verstellung 0 "Init" 1 "freigegeben" ;
VAL_ 2527679498 Perso_Aktiv 0 "deaktiviert" 1 "aktiviert" ;
VAL_ 2527679498 IAA_PSO_wake_up 0 "wake_up_inactive" 1 "wake_up_active" ;
VAL_ 2527679498 Perso_Fahrernummer 0 "kein_Fahrer" 1 "Fahrer_1" 2 "Fahrer_2" 3 "Fahrer_3" 4 "Fahrer_4" 5 "Fahrer_5" 6 "Fahrer_6" 7 "Fahrer_7" ;
VAL_ 2527679498 Perso_Schreibschutz 0 "Schreibschutz_deaktiviert" 1 "Schreibschutz_aktiviert" ;
VAL_ 398 PLA2_Anf_Meldungen_FA 0 "Keine_Meldung" 1 "FA_Stoerung_Service" 2 "FA_Stoerung_temp" 3 "FA_n_a_temp_Anhaenger" 4 "FA_n_a_temp_Tuer_offen" 5 "FA_n_a_temp_Heckklappe_offen" 6 "FA_n_a_temp_Sensor" 7 "FA_n_a_Kamerareinigung" 8 "FA_n_a_DriveSelect" ;
VAL_ 398 PLA2_Anf_Meldungen_MA 0 "Keine_Meldung" 1 "MA_Lenkeingriff_Akustik" 2 "MA_Fahrpedal_betaetigen" 3 "MA_Bremspedal_betaetigen" 4 "MA_Stoerung_Service" 5 "MA_n_a_temp" 6 "MA_n_a_temp_Anhaenger" 7 "MA_Lenkung_uebersteuert" 8 "MA_Bremsung_uebersteuert" 9 "MA_n_a_Seitespiegel_ausklappen" 10 "MA_Uebernahme_Fahrer" 11 "MA_Stoerung_hinten_perm" 12 "MA_Stoerung_vorn_perm" 13 "MA_n_a_temp_Tuer_offen" 14 "MA_n_a_temp_Heckklappe_offen" 15 "MA_n_a_vorn_Ultraschall" 16 "MA_n_a_hinten_Ultraschall" 17 "MA_n_a_Ultraschall" 18 "MA_n_a_vorn_Kamera" 19 "MA_n_a_hinten_Kamera" 20 "MA_n_a_Kamera" 21 "MA_n_a_Kamerareinigung" 22 "MA_Bremsung" 23 "MA_n_a_ESC_deaktiviert" 24 "MA_n_a_ACC_aktiv" 25 "MA_Lenkeingriff" 26 "MA_n_a_DriveSelect" 27 "MA_temp_beendet" ;
VAL_ 398 PLA2_Status_Aktive_Seite 0 "Rechts" 1 "Links" ;
VAL_ 398 PLA2_Anf_Anzeige_Mini 0 "keine Anzeige" 1 "Anzeige Mini" ;
VAL_ 398 PLA2_Anf_Anzeige_Schwellpfeil 0 "Keine Schwellpfeilanzeige" 1 "Anzeige Schwellpfeil" ;
VAL_ 398 PLA2_Anf_Akustik 0 "keine_Akustik" 1 "Akustik_Gong_1000" ;
VAL_ 398 PLA2_Mini_Modus 0 "kein Mini angezeigt" 1 "Mini Längsparken" 2 "Mini Rückwärts Querparken" 3 "Mini Vorwärts Querparken" 4 "Mini_Vorwaerts_Querparken_mit_VB" 5 "Weitere_Parkmoeglichkeit_vorhanden" 6 "Garagenparken" ;
VAL_ 398 PLA2_Anf_Anzeige_Bremsfuss 0 "Keine_Anzeige_Bremsfuss" 1 "Anzeige_Bremsfuss" ;
VAL_ 398 PLA2_Anf_Anzeigemodus 0 "Keine_Anzeige" 1 "Reserved" 2 "Laengsparken_Singlescreen" 3 "Reserved" 4 "Rueckwaerts_Querparken_Singlescreen" 5 "Reserved" 6 "Vorwaerts_Querparken_Singlescreen" 7 "Vorwaerts_Querparken_mit_VB" 8 "Ausparken_Laengsparken_Singlescreen" 9 "Garagenparken_vorwaerts" 10 "Garagenparken_rueckwaerts" 11 "Textmeldung_hochprior" 12 "Textmeldungen_niederprior" 13 "Anzeigen_beidseitig" 14 "Reserved" 15 "Reserved" ;
VAL_ 398 PLA2_Anf_Meldungen 0 "keine Meldung" 1 "beendet" 2 "Fahrinf_Bremse_FT_betaetigen" 3 "Suche_fortsetzen_ESC_Eingriff" 4 "n_a_temp_ESC_deaktiviert" 5 "n_a_temp_Anhaengerbetrieb" 6 "Suche_Zeitlimit_ueberschritten" 8 "Fahrinf_PaLueSu_aufschalten" 9 "Stby_Bremse_u_FT_druecken" 10 "PosOK_Stillstandszeit" 11 "Stby_FT_druecken" 12 "AP_nicht_moeglich" 13 "Fahrinf_Bremse_loesen_Umfeld" 14 "n_a_temp_Tuer_Heckklappe_offen" 15 "Stby_Tuer_Heckklappe_schliessen" 16 "PP_aktiv_nur_aussen_bedienbar" 17 "PP_Fzg_verlassen" 18 "n_a_Offroad_Modus" 19 "PP_Schluessel_oder_App_bedienen" 20 "PP_App_bedienen" 21 "PP_Schluessel_bedienen" 22 "n_a_temp" 23 "Systemstoerung_Service" 24 "n_a_temp_Sensorsicht" 25 "n_a_temp_Spiegel_ausklappen" 26 "GP_Stoerung_Service" 27 "n_a_temp_FAS_aktiv" 28 "PP_BT_unterbrochen" 29 "Hindernis_in_Fahrtrichtung" 30 "Ausparken_Fahrtrichtung_vorgeben" 32 "Suche_Rangierflaeche_zu_klein" 33 "n_a_temp_Drive_Select" 34 "Fahrinf_Bremse_loesen" 35 "Fahrinf_Fahrtrichtungswechsel" 36 "Fahrinf_Bremse_FT_RT_betaetigen" 37 "GP_Fzgposition_vor_Garage" 38 "GP_RT_Garage_oeffnen" 39 "GP_Kein_Zuparken" 40 "Suche_Fahrinfo_beachten" 41 "GP_Fzgposition_freie_Parkflaeche" 42 "GP_n_a_temp_Laser" 43 "Geschwindigkeitsueberschreitung" 44 "Fahrinf_Weiter_vorfahren" 45 "Fahrinf_Bremsbetaetigug" 46 "Fahrinf_Anhalten" 47 "GP_AP_nicht_moeglich_Fahrweg" 48 "PP_Gang_Schluesselauthentifizier" 49 "Fahrhinweis_FT_betaetigen" 50 "PP_aktiv_Hinweis_FUEN" 128 "Disclaimer_LP_rechts" 129 "Disclaimer_LP_links" 130 "Disclaimer_RQ_rechts" 131 "Disclaimer_RQ_links" 132 "Disclaimer_VQ_rechts" 133 "Disclaimer_VQ_links" 134 "Disclaimer_AP_rechts" 135 "Disclaimer_AP_links" 136 "Disclaimer_Bremse_loesen" 137 "Abbruch_Lenkeingriff_Fahrer" 138 "Abbruch_Anhaenger_erkannt" 139 "Abbruch_max_Rangierzuege" 140 "Abbruch_Zeitlimit_ueberschritten" 141 "Beendet_Bitte_uebernehmen" 142 "Beendet" 143 "Abbruch_Fahrpedaleingriff" 144 "Abbruch_ESC_Eingriff" 145 "Stby_Verkehr_erkannt" 146 "Abbruch_Spiegel_ausklappen" 147 "Abbruch_Waehlhebeleingriff" 148 "Abbruch_AP_Luecke_zu_klein" 149 "Abbruch_Rangierflaeche_zu_klein" 150 "Abbruch_Sensorsicht" 151 "Beendet_Stoerung_Fzgverbindung" 152 "Beendet_selbst_bremsen" 153 "Abbruch_Hindernis_erkannt" 154 "Abbruch_bitte_uebernehmen" 155 "Beendet_Fortsetzung_moeglich" 156 "Stby_Hindernis_erkannt" 157 "FUEN_moeglich" 158 "Abbruch_FUEN_Motor_abgestellt" 159 "Abbruch_Drive_Select" 160 "Abbruch_AP_Seite_versperrt" 161 "PP_Fehler_Schluesselautorisier" 162 "PP_Hinweis_ZV" 163 "PP_Hinweis_Motorabschaltung" 164 "Stby_FT_oder_RT_betaetigen" 165 "Stby_Hindernis_Richtungswechsel" 166 "Stby_erhoehter_Fahrwiderstand" 167 "Abbruch_EPB_aktiviert" 168 "Abbruch_MO_nicht_bereit" 169 "Abbruch_Stoerung_Service" 170 "Abbruch_Gurtschloss_gesteckt" 171 "PP_Abbruch_Rangierbereich" 172 "PP_Abbruch_Verdeckaktivierung" 173 "Abbruch_Bremseingriff_FAS_System" 174 "PP_eingeschraenkt_verfuegbar" 175 "Abbruch" 176 "PosOK_Lenkrad_loslassen_Bremse" 177 "PosOK_Lenkrad_loslassen_FT" 178 "Wiederaufnahme_FT_betaetigen" 179 "PP_beendet_FUEN_moeglich" 180 "Lenkeingriff_beendet" 181 "PP_Abbruch_Zeitlimit" ;
VAL_ 398 PLA2_Status_Funktion 0 "PL_Suche" 1 "PL_Suche_Standby" 2 "PL_gefunden" 3 "Pos_OK" 4 "Rangieren_vorwaerts" 5 "Rangieren_rueckwaerts" 6 "Disclaimer_in_Anzeige" 7 "Automodus_Wand" 8 "PP_Pos_OK" 9 "Reserved" 10 "Reserved" 11 "GP_Pos_OK" 12 "Reserved" 13 "Reserved" 14 "DP_Pos_OK" 15 "Reserved" ;
VAL_ 1166 PLA_Anforderung_HMS 0 "keine_Anforderung_Init" 1 "Halten" 2 "Parken" 3 "Halten_standby" 4 "Anfahren" 5 "Loesen_ueber_Rampe" 6 "Parken_mit_P" 7 "reserviert" ;
VAL_ 1166 PLA_Status_Aktive_Seite 0 "Rechts" 1 "Links" ;
VAL_ 1166 PLA_Anf_Anzeige_Mini 0 "keine_Anzeige" 1 "Miniaturanzeige" ;
VAL_ 1166 PLA_Mini_Modus 0 "kein_Mini_angezeigt" 1 "Mini_Laengsparken" 2 "Mini_Rueckwaerts_Querparken_mit_Vorbeifahrt" 3 "Mini_Vorwaerts_Querparken_ohne_VB" 4 "Mini_Vorwaerts_Querparken_mit_VB" 5 "weitere_Parkmoeglichkeit_vorhanden" 6 "Garagenparken" 7 "Mini_Rueckwaerts_Querparken_ohne_Vorbeifahrt" ;
VAL_ 1166 PLA_Anf_Akustik 0 "keine_Akustik" 1 "Akustik__Gong_1000" ;
VAL_ 1166 PLA_Anf_Anzeige_Schwellpfeil 0 "Keine_Schwellpfeilanzeige" 1 "Anzeige_Schwellpfeil" ;
VAL_ 1166 PLA_Anf_Anzeige_Bremsfuss 0 "Keine_Anzeige_Bremsfuss" 1 "Anzeige_Bremsfuss" ;
VAL_ 1166 PLA_Anf_Anzeigemodus 0 "Keine_Anzeige" 1 "Anzeige_AP_verfuegbar" 2 "Laengsparken_Singlescreen" 3 "Reserved" 4 "Rueckwaerts_Querparken_mit_VB" 5 "Rueckwaerts_Querparken_ohne_VB" 6 "Vorwaerts_Querparken_ohne_VB" 7 "Vorwaerts_Querparken_mit_VB" 8 "Ausparken_Laengsparken_Single" 9 "Garagenparken_vorwaerts" 10 "Garagenparken_rueckwaerts" 11 "Textmeldung_hochprior" 12 "Textmeldungen_niederprior" 13 "Anzeige_beidseitig" 14 "Anzeige_einseitig" 15 "Anzeige_PL_verfuegbar" ;
VAL_ 1166 PLA_Anf_Meldungen 0 "keine_Meldung" 1 "PLA_beendet" 2 "RBF_deaktiviert" 3 "Autosuche_ESC_ASR_Eingriff" 4 "PLA_temp_n_a_ESC_ASR_Fehler" 5 "PLA_temp_n_a_Anhaenger_gesteckt" 6 "Suche_Zeitlimit_ueberschritten" 7 "PLA_zurzeit_n_verfuegbar" 8 "PLA_defekt_Werkstatt" 9 "Stillstandzeit_n_ausreichend" 11 "AP_Blinker_setzen_u_RWG_einlegen" 12 "AP_n_moeglich_PL_zu_klein" 13 "RBF_aktiv" 14 "PLA_beendet_v_zu_hoch" 15 "PLA_beendet_Schiebetuer_offen" 16 "Gegenseite_versperrt" 17 "Parken_n_a_Luecke_zu_klein" 18 "PLA_im_Offroad_Modus_n_a" 21 "AP_Blinker_setzen_u_Softkey_MIB" 22 "Start_Softkey_am_MIB_betaetigen" 23 "RBF_Hindernis_erkannt" 24 "RBF_temp_beendet" 25 "RBF_Gaspedal_loesen" 26 "RBF_Bremse_betaetigen" 27 "RBF_n_a_temp" 28 "RBF_n_a_temp_Anhaenger" 29 "RBF_n_a_temp_Sensorsicht" 30 "RBF_n_a_temp_ESC" 31 "RBF_n_a_temp_Drive_Select" 32 "Einparken_am_MIB_bestaetigen" 40 "info_v_reduzieren" 41 "info_v_begrenzt" 42 "info_Wiederaufnahme" 43 "info_Richtungsw_rueckw" 44 "info_Richtungsw_vorw" 128 "Disclaimer_LP_rechts" 129 "Disclaimer_LP_links" 130 "Disclaimer_RQ_rechts" 131 "Disclaimer_RQ_links" 136 "Disclaimer_VQ_rechts" 137 "Disclaimer_VQ_links" 138 "Disclaimer_AP_rechts" 139 "Disclaimer_AP_links" 144 "Abbruch_Lenkeingriff_Fahrer" 145 "Abbruch_Anhaenger_erkannt" 146 "Abbruch_ESC_deaktiv" 147 "Abbruch_Zeitlimit_ueberschritten" 148 "Lenkeingriff_beendet_uebernehmen" 149 "Abbruch_manuell_parken" 150 "Abbruch_v_zu_hoch" 151 "Abbruch_ESC_ASR_Eingriff" 152 "PLA_beendet_temp_n_a" 153 "PLA_defekt_Werkstatt" 154 "Lenkung_uebernehmen_Fahrt_forts" 155 "Abbr_AP_Luecke_zu_klein" 156 "Bremseingriff_v_zu_hoch" 157 "Abbruch_Hindernis_erkannt" 158 "PLA_Notbremsung_Bremse_betaetige" 159 "PLA_Notbr_Abbruch_Bremse_betaet" 160 "Abbr_Einp_Hindernis_erkannt" 161 "PLA_beendet_Lenkung_uebernehmen" 162 "Abbruch_Offroad_Modus_PLA_n_a" 163 "PLA_Abbruch_Schiebetuer_offen" 164 "Abbr_Luecke_zu_klein" 165 "RBF_temp_n_a" 166 "RBF_Bremse_betaetigen" 167 "Disclaimer_vorwaerts" 168 "RBF_Bitte_uebernehmen" 169 "RBF_Stoerung_Service" 170 "Disclaimer_rueckwaerts" 171 "Abbruch_Fluegeltuer_offen" 172 "Lenkeingriff_Aktiv_Bremsen" ;
VAL_ 1166 PLA_Status_Funktion 0 "PL_Suche" 1 "PL_Suche_Standby" 2 "PL_gefunden" 3 "POS_OK" 4 "Rangieren_vorwaerts" 5 "Rangieren_rueckwaerts" 6 "Disclaimer_in_Anzeige" 7 "Automodus_Wand" 8 "PP_Pos_OK" 11 "GP_Pos_OK" 14 "DP_Pos_OK" ;
VAL_ 1166 PLA_Status_beenden_Mini 0 "Funktion_vorhanden" 1 "Funktion_ausgewaehlt" 2 "Funktion_einparken_moeglich" 3 "Funktion_nicht_vorhanden" ;
VAL_ 1166 PLA_Status_Laengsparken_Mini 0 "Funktion_vorhanden" 1 "Funktion_ausgewaehlt" 2 "Funktion_einparken_moeglich" 3 "Funktion_nicht_vorhanden" ;
VAL_ 1166 PLA_Status_QP_Rueckw_Mini 0 "Funktion_vorhanden" 1 "Funktion_ausgewaehlt" 2 "Funktion_einparken_moeglich" 3 "Funktion_nicht_vorhanden" ;
VAL_ 1166 PLA_Status_QP_Vorw_Mini 0 "Funktion_vorhanden" 1 "Funktion_ausgewaehlt" 2 "Funktion_einparken_moeglich" 3 "Funktion_nicht_vorhanden" ;
VAL_ 319 PreCrash_Charisma_FahrPr 0 "keine_Funktion" 1 "Programm_1" 2 "Programm_2" 3 "Programm_3" 4 "Programm_4" 5 "Programm_5" 6 "Programm_6" 7 "Programm_7" 8 "Programm_8" 9 "Programm_9" 10 "Programm_10" 11 "Programm_11" 12 "Programm_12" 13 "Programm_13" 14 "Programm_14" 15 "Programm_15" ;
VAL_ 319 PreCrash_Charisma_Status 0 "Init" 1 "verfuegbar" 2 "nicht_verfuegbar" 3 "asynchron_durch_Fahrerwunsch" ;
VAL_ 319 PreCrash_Schiebedach_schliessen 0 "keine_Schliessung" 1 "Schliessung_angefordert" ;
VAL_ 319 PreCrash_Fenster_schliessen 0 "keine_Schliessung" 1 "Schliessung_angefordert" ;
VAL_ 319 PreCrash_Blinken 0 "keine_Blinkanforderung" 1 "Warnblinken" 2 "RECAS_Blinken" 3 "Notbremsblinken" ;
VAL_ 319 SC_PreSense_FCWP 0 "Warnung_gilt_fuer_Objekte" 1 "Warnung_gitl_fuer_Fussgaenger" ;
VAL_ 319 PreCrash_Tueren_Verriegeln 0 "keine_Anforderung" 1 "Tueren_Verriegeln" ;
VAL_ 319 PreCrash_Anforderung_AFR 0 "keine_Anforderung" 1 "linke_Seite" 2 "rechte_Seite" 3 "Vorderachse" 4 "Hinterachse" 5 "Vorwarnung" 7 "Init" ;
VAL_ 319 SC_PreCrash_LED 0 "keine_Anzeige" 1 "Stufe_1_glimmen" 2 "Stufe_2_leuchten" 3 "Stufe_3_blinken" ;
VAL_ 319 PreCrash_FS_Pneumatik_ansteuern 0 "keine_Anforderung" 1 "Pneumatik_ansteuern" ;
VAL_ 319 PreCrash_BFS_Pneumatik_ansteuern 0 "keine_Anforderung" 1 "Pneumatik_ansteuern" ;
VAL_ 319 PreCrash_Fo_Pneumatik_ansteuern 0 "keine_Anforderung" 1 "Pneumatik_ansteuern" ;
VAL_ 319 PreCrash_FS_Sitzlehne_verfahren 0 "keine_Anforderung" 1 "reserviert" 2 "reserviert" 3 "Sitzlehnenkopf_in_pos_xRichtung_verfahrenvor" 4 "Sitzlehnenkopf_in_neg_xRichtung_verfahrenzurueck" 6 "reserviert" 7 "Lehnenkopfverstellung_ansteuern" ;
VAL_ 319 PreCrash_BFS_Sitzlehne_verfahren 0 "keine_Anforderung" 1 "reserviert" 2 "reserviert" 3 "Sitzlehnenkopf_in_pos_xRichtung_verfahrenvor" 4 "Sitzlehnenkopf_in_neg_xRichtung_verfahrenzurueck" 6 "reserviert" 7 "Lehnenkopfverstellung_ansteuern" ;
VAL_ 319 PreCrash_Fo_Sitzlehne_verfahren 0 "keine_Anforderung" 1 "reserviert" 2 "reserviert" 3 "Sitzlehnenkopf_in_pos_xRichtung_verfahrenvor" 4 "Sitzlehnenkopf_in_neg_xRichtung_verfahrenzurueck" ;
VAL_ 319 PreCrash_FS_KSV_verfahren 0 "keine_Anforderung" 1 "in_pos_xRichtung_verfahren" 2 "in_neg_xRichung_verfahren" 3 "in_pos_zRichtung_verfahren" 4 "in_neg_zRichtung_verfahren" 5 "in_pos_xRichtung_und_neg_zRichtung_verfahren" 6 "in_pos_x_Richtung_und_pos_zRichtung_verfahren" 7 "in_neg_xRichtung_und_neg_zRichtung_verfahren" 8 "in_neg_xRichtung_und_pos_zRichtung_verfahren" 9 "Kopfstuetze_ansteuern" ;
VAL_ 319 PreCrash_BFS_KSV_verfahren 0 "keine_Anforderung" 1 "in_pos_xRichtung_verfahren" 2 "in_neg_xRichung_verfahren" 3 "in_pos_zRichtung_verfahren" 4 "in_neg_zRichtung_verfahren" 5 "in_pos_xRichtung_und_neg_zRichtung_verfahren" 6 "in_pos_x_Richtung_und_pos_zRichtung_verfahren" 7 "in_neg_xRichtung_und_neg_zRichtung_verfahren" 8 "in_neg_xRichtung_und_pos_zRichtung_verfahren" 9 "Kopfstuetze_ansteuern" ;
VAL_ 319 PreCrash_Fo_KSV_verfahren 0 "keine_Anforderung" 1 "in_pos_xRichtung_verfahren" 2 "in_neg_xRichung_verfahren" 3 "in_pos_zRichtung_verfahren" 4 "in_neg_zRichtung_verfahren" 5 "in_pos_xRichtung_und_neg_zRichtung_verfahren" 6 "in_pos_x_Richtung_und_pos_zRichtung_verfahren" 7 "in_neg_xRichtung_und_neg_zRichtung_verfahren" 8 "in_neg_xRichtung_und_pos_zRichtung_verfahren" ;
VAL_ 319 SC_PreCrash_Warnung 0 "keine_Anzeige" 1 "latente_Vorwarnung" 2 "Vorwarnung" 3 "Akutwarnung" 4 "Eingriff" 5 "Fahreruebernahmeaufforderung" 6 "Abbiegewarnung" 7 "Basiseingriff" 8 "Heckeingriff" ;
VAL_ 319 SC_PreCrash_Texte 0 "keine_Anzeige" 1 "Systemstoerung" 2 "keine_Sensorsicht" 3 "Demomodus" 4 "System_aus" 5 "Anhaengerbetrieb" 6 "ESC_aus" 7 "zurzeit_eingeschraenkt" 8 "zurzeit_eingeschraenkt_ESP_Aus" 9 "Initialisierung" ;
VAL_ 1122 PSD_Segment_ID 0 "keine Segmentinformationen vorhanden" 1 "Fehlerwert" ;
VAL_ 1122 PSD_Vorgaenger_Segment_ID 0 "keine Segmentinformation vorhanden" 1 "Fehlerwert" ;
VAL_ 1122 PSD_Strassenkategorie 0 "Rest_Feldweg_Schotterweg_Privatweg" 1 "Ortsstraße" 2 "Kreisstraße" 3 "Landstraße" 4 "Bundesstraße" 5 "Autobahn" 7 "Init" ;
VAL_ 1122 PSD_Endkruemmung 255 "Gerade" ;
VAL_ 1122 PSD_Endkruemmung_Vorz 0 "Kruemmung_positiv" 1 "Kruemmung_negativ" ;
VAL_ 1122 PSD_Idenditaets_ID 0 "keine_Segment_Informationen_vorhanden" 1 "Fehler" ;
VAL_ 1122 PSD_ADAS_Qualitaet 0 "keine_ADAS_Qualitaet" 1 "ADAS_Qualitaet" ;
VAL_ 1122 PSD_wahrscheinlichster_Pfad 0 "Pfad_mit_geringer_Wahrscheinlichkeit" 1 "wahrscheinlichster_Pfad" ;
VAL_ 1122 PSD_Geradester_Pfad 0 "nicht_geradester_PFad" 1 "geradester_Pfad" ;
VAL_ 1122 PSD_Fahrspuren_Anzahl 0 "Einbahnstrasse_in_falsche_Richtung" 1 "eine_Fahrspur" 2 "zwei_Fahrspuren" 3 "drei_Fahrspuren" 4 "vier_Fahrspuren" 5 "fuenf_Fahrspuren" 6 "sechs_Fahrspuren" 7 "mehr_als_sechs_Fahrspuren" ;
VAL_ 1122 PSD_Bebauung 0 "ausserhalb_bebauten_Gebietes" 1 "innerhalb_bebauten_Gebietes" ;
VAL_ 1122 PSD_Segment_Komplett 0 "Segment_Attribute_nicht_komplett" 1 "Segment_Attribute_komplett" ;
VAL_ 1122 PSD_Rampe 0 "Strasse_mit_Gegenverkehr" 1 "Auffahrt_Einbahnstr" 2 "Abfahrt_Einbahnstr" 3 "Einbahnstrasse" ;
VAL_ 1122 PSD_Anfangskruemmung 255 "Gerade" ;
VAL_ 1122 PSD_Anfangskruemmung_Vorz 0 "positiv" 1 "negativ" ;
VAL_ 1122 PSD_Abzweigerichtung 0 "rects_abzweigende_Strasse" 1 "links_abzweigende_Strasse" ;
VAL_ 1123 PSD_Pos_Segment_ID 0 "keine Position gegeben" 1 "Fehlerwert" ;
VAL_ 1123 PSD_Pos_Standort_Eindeutig 0 "mehrdeutiger_Standort" 1 "eindeutiger_Standort" ;
VAL_ 1123 PSD_Pos_Fehler_Laengsrichtung 0 "Init" 1 "< 2m" 2 "< 5m" 3 "< 10m" 4 "< 20m" 5 "< 50m" 6 "> 50m" 7 "Off-Road" ;
VAL_ 1123 PSD_Pos_Fahrspur 0 "unbekannt" 1 "Erste_Spur_von_rechts" 2 "Zweite_Spur_von_rechts" 3 "Dritte_Spur_von_rechts" 4 "Vierte_Spur_von_rechts" 5 "Fuenfte_Spur_von_rechts" 6 "Sechte_Spur_von_rechts" 7 "Siebte_oder_weitere_Spur_von_rechts" ;
VAL_ 1123 PSD_Attribut_Segment_ID_05 0 "keine_Segment_Information" 1 "Fehler" ;
VAL_ 1123 PSD_Attribut_1_ID 0 "keine_Information" ;
VAL_ 1123 PSD_Attribut_2_ID 0 "keine_Information" ;
VAL_ 1123 PSD_Attribute_Komplett_05 0 "Attribute_nicht_komplett" 1 "Attribute_komplett" ;
VAL_ 1124 PSD_06_Mux 0 "Init" ;
VAL_ 1124 PSD_Sys_Segment_ID 0 "keine Segmentinformationen vorhanden" 1 "nicht zulaessig" ;
VAL_ 1124 PSD_Attribut_Segment_ID 0 "keine_Segment_Information_vorhanden" 1 "Fehler" ;
VAL_ 1124 PSD_Ges_Segment_ID 0 "keine Segmentinformationen vorhanden" 1 "nicht zulaessig" ;
VAL_ 1124 PSD_Baum_Laenge_VZ 0 "Ost" 1 "West" ;
VAL_ 1124 PSD_Steigung_1_Segment_ID 0 "keine_Segment_Information_vorhanden" 1 "Fehler" ;
VAL_ 1124 PSD_Baum_Laenge 33554431 "keine_GPS_Information" ;
VAL_ 1124 PSD_Attribut_3_ID 0 "keine_Information" ;
VAL_ 1124 PSD_Steigung_1_A_Steigung 126 "mehr_als_15_Prozent" 127 "Steigung_unbekannt" ;
VAL_ 1124 PSD_Ges_Geschwindigkeit 0 "Kein Geschwindigkeitsgebot" 1 "0 km/h < v_max <  5 km/h" 2 "5 km/h < v_max < 10km/h" 3 "10 km/h < v_max < 15 km/h" 4 "15 km/h < v_max < 20 km/h" 5 "20 km/h < v_max < 25 km/h" 6 "25 km/h < v_max < 30 km/h" 7 "30 km/h < v_max < 35 km/h" 8 "35 km/h < v_max < 40 km/h" 9 "40 km/h < v_max < 45 km/h" 10 "45 km/h < v_max < 50 km/h" 11 "50 km/h < v_max < 60 km/h" 12 "60 km/h < v_max < 70 km/h" 13 "70 km/h < v_max < 80 km/h" 14 "80 km/h < v_max < 90 km/h" 15 "90 km/h < v_max < 100 km/h" 16 "100 km/h < v_max < 110 km/h" 17 "110 km/h < v_max < 120 km/h" 18 " 120 km/h < v_max < 130 km/h" 19 "130 km/h < v_max < 140 km/h" 20 "140 km/h < v_max < 150 km/h" 21 "150 km/h < v_max < 160 km/h" 22 "160 km/h < v_max" 23 "Geschwindigkeitsgebot aufgehoben" 24 "..0x1F ungültig" ;
VAL_ 1124 PSD_Steigung_1_A_Vorz 0 "Gefaelle" 1 "Steigung" ;
VAL_ 1124 PSD_Sys_Geschwindigkeit_Einheit 0 "km/h" 1 "mph" ;
VAL_ 1124 PSD_Sys_Verkehrsrichtung 0 "Rechtsverkehr" 1 "Linksverkehr" ;
VAL_ 1124 PSD_Sys_Geometrieguete 0 "Geringe_Guete" 1 "tbd" 2 "tbd" 3 "Hohe_Guete" ;
VAL_ 1124 PSD_Sys_Mapmatchingguete 0 "geringe_Guete" 1 "res" 2 "res" 3 "hohe_Guete" ;
VAL_ 1124 PSD_Ges_Typ 0 "Geschw_Klasse_des_Kartendatensuppliers" 1 "Explizit_abgeleiteten_Begrenzung" 2 "Durch_Gesetzg_vorgeg_allgem_Gebot_fuer_uebertr_Rahmenbed" 3 "Init" ;
VAL_ 1124 PSD_Sys_Alter_Karte 0 "kleiner_1_Jahr" 1 "1_Jahr" 2 "2_Jahre" 3 "3_Jahre" 4 "4_Jahre" 5 "5_Jahre" 6 "6_Jahre" 7 "groesser_7_Jahre" ;
VAL_ 1124 PSD_Ges_Spur_Geschw_Begrenzung 0 "Gebot_fuer_alle_spuren_gueltig" ;
VAL_ 1124 PSD_Steigung_1_B_Steigung 126 "mehr_als_15_Prozent" 127 "Steigung_unbekannt" ;
VAL_ 1124 PSD_Attribut_4_ID 0 "keine_Information" ;
VAL_ 1124 PSD_Sys_Zielfuehrung 0 "Zielfuehrung nicht aktiv" 1 "Zielfuehrung aktiv" ;
VAL_ 1124 PSD_Sys_US_State 0 "kein_US_State" 1 "Alabama" 2 "Alaska" 3 "Arkansas" 4 "Arizona" 5 "California" 6 "Colorado" 7 "Conneticut" 8 "District_of_Columbia" 9 "Delaware" 10 "Florida" 11 "Georgia" 12 "Hawaii" 13 "Idaho" 14 "Illinois" 15 "Iowa" 16 "Indiana" 17 "Kansas" 18 "Kentucky" 19 "Louisiana" 20 "Massachusetts" 21 "Maryland" 22 "Maine" 23 "Michigan" 24 "Minnesota" 25 "Missouri" 26 "Mississippi" 27 "Montana" 28 "North_Carolina" 29 "North_Dakota" 30 "Nebraska" 31 "Nevada" 32 "New_Hampshire" 33 "New_Jersey" 34 "New_Mexico" 35 "New_York" 36 "Ohio" 37 "Oklahoma" 38 "Oregon" 39 "Pennsylvania" 40 "Puerto_Rico" 41 "Rhode_Island" 42 "South_Carolina" 43 "South_Dakota" 44 "Tennessee" 45 "Texas" 46 "Utah" 47 "Virginia" 48 "Virgin_Islands" 49 "Vermont" 50 "Washington" 51 "Wisconsin" 52 "West_Virginia" 53 "Wyoming" ;
VAL_ 1124 PSD_Ges_Geschwindigkeit_Gespann 0 "alle Fahrzeuge" 1 "PKW mit Gespann" 2 "LKW, Busse, etc." ;
VAL_ 1124 PSD_Baum_Breite_VZ 0 "Nord" 1 "Sued" ;
VAL_ 1124 PSD_Ges_Geschwindigkeit_Witter 0 "Witterungsunabhängig" 1 "Nässe, Regen, Niederschlag" 2 "Glätte" 3 "Nebel" ;
VAL_ 1124 PSD_Steigung_1_B_Vorz 0 "Gefaelle" 1 "Steigung" ;
VAL_ 1124 PSD_Ges_Geschwindigkeit_Tag_Anf 0 "kein Beginn definiert" 1 "Montag" 2 "Dienstag" 3 "Mittwoch" 4 "Donnerstag" 5 "Freitag" 6 "Samstag" 7 "Sonntag" ;
VAL_ 1124 PSD_Ges_Geschwindigkeit_Tag_Ende 0 "kein Ende definiert" 1 "Montag" 2 "Dienstag" 3 "Mittwoch" 4 "Donnerstag" 5 "Freitag" 6 "Samstag" 7 "Sonntag" ;
VAL_ 1124 PSD_Sys_Quali_verfuegbar 0 "Qualitaetskriterien_nicht_verfuegbar" 1 "Qualitaetskriterien_verfuegbar" ;
VAL_ 1124 PSD_Sys_Zielfuehrung_geaendert 0 "Zielfuehrung_nicht_geaendert" 1 "Zielfuehrung_geaendert" ;
VAL_ 1124 PSD_Ges_Geschwindigkeit_Std_Anf 25 "kein Beginn für stundenweise Einschränkungen" ;
VAL_ 1124 PSD_Steigung_1_Attribute_kompl 0 "Steigungen_nicht_komplett" 1 "Steigungen_komplett" ;
VAL_ 1124 PSD_Sys_Geometrieguete_erweitert 0 "Init" ;
VAL_ 1124 PSD_Steigung_2_Segment_ID 0 "keine_Segment_Information_vorhanden" 1 "Fehler" ;
VAL_ 1124 PSD_Attribut_5_ID 0 "keine_Information" ;
VAL_ 1124 PSD_Ges_Geschwindigkeit_Std_Ende 25 "kein Ende für stundenweise Einschränkungen" ;
VAL_ 1124 PSD_Steigung_2_Steigung 126 "mehr_als_15_Prozent" 127 "Steigung_unbekannt" ;
VAL_ 1124 PSD_Ges_Ueberholverbot 0 "kein Überholverbot" 1 "alle Fahrzeuge" 2 "Überholverbot für PKW mit Gespann" 3 "Überholverbot für LKW, Busse, etc." ;
VAL_ 1124 PSD_Ges_Wechselverkehrszeichen 0 "Kein Wechselverkehrszeichen" 1 "Wechselverkehrszeichen links" 2 "Wechselverkehrszeichen rechts" 3 "Wechselverkehrszeichen links und rechts" 4 "Wechselverkerhszeichen über der Fahrbahn" ;
VAL_ 1124 PSD_Steigung_2_Vorz 0 "Gefaelle" 1 "Steigung" ;
VAL_ 1124 PSD_Wechselverkehrszeichen_Typ 0 "kein_Wechselverkehrszeichen" 1 "LED_Wechselverkehrszeichen" 2 "nicht_LED_Wechselverkehrszeichen" ;
VAL_ 1124 PSD_Ges_Gesetzlich_Kategorie 0 "kein_legales_Verbot" 1 "innerorts" 2 "ausserorts" 3 "Autobahn" ;
VAL_ 1124 PSD_Attribute_Komplett_06 0 "Attribute_nicht_komplett" 1 "Attribute_komplett" ;
VAL_ 1124 PSD_Ges_Gesetzlich_Zusatz 0 "kein_Zusatz_zu_legalem_Gebot" 1 "Anhaenger_Klasse_1" 2 "Anhaenger_Klasse_2" ;
VAL_ 1124 PSD_Ges_Verkehrszeichen_Quelle 0 "VZA_kein_Onlinedienst" 1 "nur_VZA" 2 "nur_VZO" 3 "VZA_und_VZO" ;
VAL_ 1124 PSD_Steigung_2_Attribute_kompl 0 "Steigungen_nicht_komplett" 1 "Steigungen_komplett" ;
VAL_ 1124 PSD_Ges_Attribute_Komplett 0 "Attribute_nicht_komplett" 1 "Attribute_komplett" ;
VAL_ 2463978730 pVS_vLimit_HMI 30 "keine_Geschwindigkeitsvorgabe" 31 "Init" ;
VAL_ 2463978730 pVS_Hinweismeldung 0 "keine_Meldung" 1 "pVS_v_ueberschritten" 2 "pVS_v_ueberdrueckt" 3 "pVS_v_Aenderung" ;
VAL_ 2463978730 pVS_vLimit_HMI_Unit 0 "kmh" 1 "mph" ;
VAL_ 2463978730 pVS_Note_SpeedAdjustment 0 "pVS_vLimit_constant" 1 "pVS_vLimit_change" ;
VAL_ 2463978730 pVS_IconActivation 0 "pVS_nicht_aktiv" 1 "pVS_aktiv" ;
VAL_ 2463978730 pVS_vLimit_Range 1021 "kein_Range_Limit" 1022 "Init" 1023 "Fehler" ;
VAL_ 2463978730 pVS_vLimit_Range_HMI 1021 "kein_Range_Limit" 1022 "Init" 1023 "Fehler" ;
VAL_ 2463978730 pVS_vLimit_Range_pers 1021 "Kein_Range_Limit" 1022 "Init" 1023 "Fehler" ;
VAL_ 906 QSP_Warnlampe 0 "Warnlampe aus" 1 "Warnlampe ein (Aufprüfen), zur Zeit nicht belegt" 2 "Warnlampe ein (Warnung)  =  Fehler" 3 "Warnlampe ein (Übertemperatur)" ;
VAL_ 906 QSP_Init 0 "Initisalierungsphase abgeschlossen" 1 "Initialisierungsphase laeuft" ;
VAL_ 906 QSP_Ist_Moment 1023 "Fehler" ;
VAL_ 906 QSP_Thermische_Belastung 63 "Fehler" ;
VAL_ 906 QSP_Temperatur_Oel 127 "Fehler" ;
VAL_ 906 QSP_Status 0 "Abgeschaltet" 1 "Init" 2 "Bereit" 3 "Normalbetrieb" 4 "Temporaer_beenden" 5 "Temporaer_abgeschaltet" 6 "Beendet_durch_Fehler" 7 "Abgeschaltet_aufgrund_Fehler" ;
VAL_ 1339 QS_Charisma_FahrPr 0 "keine_Funktion" 1 "Programm_1" 2 "Programm_2" 3 "Programm_3" 4 "Programm_4" 5 "Programm_5" 6 "Programm_6" 7 "Programm_7" 8 "Programm_8" 9 "Programm_9" 10 "Programm_10" 11 "Programm_11" 12 "Programm_12" 13 "Programm_13" 14 "Programm_14" 15 "Programm_15" ;
VAL_ 1339 QS_Charisma_Status 0 "Init" 1 "verfuegbar" 2 "nicht_verfuegbar" 3 "asynchron_durch_Fahrerwunsch" ;
VAL_ 1339 QS_Symbol_Rear_Lock 0 "aus" 1 "ein" ;
VAL_ 1339 QS_Warntexte 0 "keine Meldung" 1 "Meldung_1" 2 "Meldung_2" 3 "Meldung_3" ;
VAL_ 1616 RA_Radio_Error_Flag 0 "kein_KD_Fehler" 1 "KD_Fehler" ;
VAL_ 1616 RA_Frequency_unit 0 "1_kHz" 1 "100_kHz" ;
VAL_ 1616 RA_AM_Tuning 0 "frequency_locked" 1 "AM_tuning" ;
VAL_ 1529 RDK_FMVSS138_Lampe 0 "RDK_WaLa_inaktiv" 1 "RDK_WaLa_aktiv" ;
VAL_ 1529 RDK_FMVSS138_MIL 0 "keine_Stoerungsanzeige" 1 "Stoerungsanzeige" ;
VAL_ 1529 RDK_Kalibrierung 0 "BAP_Kalibrierung" 1 "CAN_Kombitaster_Kalibrierung" ;
VAL_ 1529 RDK_Reifendruck_Lampe 0 "RDK_WaLa_inaktiv" 1 "RDK_WaLa_aktiv" ;
VAL_ 1529 RDK_Warnungen_02 0 "keine_Anzeige" 1 "Reifen_allgemein_Warnstufe_1" 2 "Reifen_vorne_links_Warnstufe_1" 3 "Reifen_vorne_rechts_Warnstufe_1" 4 "Reifen_hinten_links_Warnstufe_1" 5 "Reifen_hinten_rechts_Warnstufe_1" 6 "Reifen_allgemein_Warnstufe_2" 7 "Reifen_vorne_links_Warnstufe_2" 8 "Reifen_vorne_rechts_Warnstufe_2" 9 "Reifen_hinten_links_Warnstufe_2" 10 "Reifen_hinten_rechts_Warnstufe_2" 11 "Reifen_allgemein_Warnstufe_3" 12 "Reifen_vorne_links_Warnstufe_3" 13 "Reifen_vorne_rechts_Warnstufe_3" 14 "Reifen_hinten_links_Warnstufe_3" 15 "Reifen_hinten_rechts_Warnstufe_3" 16 "Akustikausgabe_Kalibrierung_io" 17 "Textausgabe_Kalibrierung_io" 18 "Akustik_Textausgabe_Kalibrier_io" 19 "RDK_aktiviert" 20 "RDK_deaktiviert" 21 "RDK_Systemstoerung" 22 "RDK_Systemstoerung_temporaer" 23 "V_Warnschwelle_1" 24 "V_Warnschwelle_2" 25 "Radwechsel_allgemein" 26 "Teilueberwachung" 27 "V_Warnschwelle_3" 28 "V_Warnschwelle_4" 29 "V_Warnschwelle_5" 30 "Reifendruecke_kalibrieren" ;
VAL_ 1529 RDK_angelernt 0 "nicht_angelernt" 1 "angelernt" ;
VAL_ 1529 RDK_Reifentemperatur_Lampe 0 "RDK_WaLa_inaktiv" 1 "RDK_WaLa_aktiv" ;
VAL_ 1529 RDK_RS_aktiv 0 "inaktiv" 1 "aktiv" ;
VAL_ 1529 RDK_Text_7 0 "inaktiv" 1 "aktiv" ;
VAL_ 1529 RDK_W_1_Reifen_HL 0 "inaktiv" 1 "aktiv" ;
VAL_ 1529 RDK_W_1_Reifen_HR 0 "inaktiv" 1 "aktiv" ;
VAL_ 1529 RDK_W_1_Reifen_VL 0 "inaktiv" 1 "aktiv" ;
VAL_ 1529 RDK_W_1_Reifen_VR 0 "inaktiv" 1 "aktiv" ;
VAL_ 1529 RDK_W_2_Reifen_HL 0 "inaktiv" 1 "aktiv" ;
VAL_ 1529 RDK_W_2_Reifen_HR 0 "inaktiv" 1 "aktiv" ;
VAL_ 1529 RDK_W_2_Reifen_VL 0 "inaktiv" 1 "aktiv" ;
VAL_ 1529 RDK_W_2_Reifen_VR 0 "inaktiv" 1 "aktiv" ;
VAL_ 1525 RW_Gesamt_Reichweite_Max_Anzeige 2045 "nicht_verbaut" 2046 "Init" 2047 "Fehler" ;
VAL_ 1525 RW_Reservewarnung_2_aktiv 0 "Init" 1 "inaktiv" 2 "aktiv" 3 "reserviert" ;
VAL_ 1525 RW_RWDS_Lastprofil 2046 "Init" 2047 "Fehler" ;
VAL_ 1525 RW_Gesamt_Reichweite 2045 "nicht_verbaut" 2046 "Init" 2047 "Fehler" ;
VAL_ 1525 RW_Prim_Reichweitenverbrauch 2047 "Init" ;
VAL_ 1525 RW_Prim_Reichweitenv_Einheit 0 "Liter_pro_100km" 1 "kWh_pro_100km" 2 "Kg_pro_100km" 3 "nicht_verbaut" ;
VAL_ 1525 RW_Primaer_Reichweite 2045 "nicht_verbaut" 2046 "Init" 2047 "Fehler" ;
VAL_ 1527 RW_Tendenz 0 "keine_Tendenz" 1 "konstant" 2 "steigend" 3 "sinkend" ;
VAL_ 1527 RW_Texte 0 "kein_Text" 1 "Text_1" 2 "Text_2" 3 "Text_3" ;
VAL_ 1527 RW_Reservewarnung_aktiv 0 "inaktiv" 1 "aktiv" ;
VAL_ 1527 RW_Reichweite_Einheit_Anzeige 0 "km" 1 "miles" ;
VAL_ 1527 RW_Gesamt_Reichweite_Anzeige 2045 "nicht_verbaut" 2046 "Init" 2047 "Fehler" ;
VAL_ 1527 RW_Primaer_Reichweite_Anzeige 2045 "nicht_verbaut" 2046 "Init" 2047 "Fehler" ;
VAL_ 1527 RW_Sekundaer_Reichweite_Anzeige 2045 "nicht_verbaut" 2046 "Init" 2047 "Fehler" ;
VAL_ 1527 RW_Sekundaer_Reichweite 2045 "nicht_verbaut" 2046 "Init" 2047 "Fehler" ;
VAL_ 1527 RW_Sek_Reichweitenv_Einheit 0 "Liter_pro_100km" 1 "kWh_pro_100km" 2 "Kg_pro_100km" 3 "nicht_verbaut" ;
VAL_ 1527 RW_Sek_Reichweitenverbrauch 2047 "Init" ;
VAL_ 2527679676 RW_Prim_rRWB_Reichw_Max_Ges_Anz 2045 "nicht_verbaut" 2046 "Init" 2047 "Fehler" ;
VAL_ 2527679676 RW_Prim_rRWB_aktiv 0 "rRWB_inaktiv" 1 "rRWB_aktiv" 2 "reserviert" 3 "Init" ;
VAL_ 2527679676 RW_Prim_rRWB_Reichw_Anz 2045 "nicht_verbaut" 2046 "Init" 2047 "Fehler" ;
VAL_ 2527679676 RW_Prim_rRWB_Reichw_Gesamt_Anz 2045 "nicht_verbaut" 2046 "Init" 2047 "Fehler" ;
VAL_ 2527679676 RW_Prim_statische_Reichw_Anz 2045 "nicht_verbaut" 2046 "Init" 2047 "Fehler" ;
VAL_ 2527679676 RW_Prim_rRWB_Reichw_Rest_E_Anz 2045 "nicht_verbaut" 2046 "Init" 2047 "Fehler" ;
VAL_ 1440 LS_Helligkeit_IR 254 "Init" 255 "Fehler" ;
VAL_ 1440 LS_Helligkeit_FW 1022 "Init" 1023 "Fehler" ;
VAL_ 1440 LS_defekt 0 "OK" 1 "defekt" ;
VAL_ 1440 LS_Verbau 0 "Init" 1 "Lichtsensor_verbaut" ;
VAL_ 1440 RS_Regenmenge 0 "0" 1 "0,0_bis_0,3" 2 "0,31_bis_1,4" 3 "1,41_bis_2,0" 4 "2,01_bis_2,8" 5 "2,81_bis_3,3" 6 "3,31_bis_4,0" 7 "4,01_bis_5,0" 8 "5,01_bis_7,0" 9 "7,01_bis_9,0" 10 "9,01_bis_11,0" 11 "11,01_bis_15,0" 12 "15,01_bis_22,0" 13 ">22,01" 14 "Init" 15 "Fehler" ;
VAL_ 1440 RS_Verbau 0 "Init" 1 "Regensensor verbaut" ;
VAL_ 1440 RS_Verglasung_schliessen 0 "Verglasung nicht schliessen" 1 "Verglasung schliessen" ;
VAL_ 1440 RS_defekt 0 "OK" 1 "defekt" ;
VAL_ 1440 RS_Wischergeschwindigkeit 0 "kein Wischen" 1 "42 Huebe/min" 2 "45 Huebe/min" 3 "48 Huebe/min" 4 "51 Huebe/min" 5 "54 Huebe/min" 6 "57 Huebe/min" 7 "60 Huebe/min" ;
VAL_ 1440 RLS_Vorfeldhelligkeit_Boost 0 "groesser_24413_Lux" 1 "bis_24413_Lux" 2 "bis_22193_Lux" 3 "bis_20176_Lux" 4 "bis_18342_Lux" 5 "bis_16647_Lux" 6 "bis_15158_Lux" 7 "bis_13780_Lux" 8 "bis_12527_Lux" 9 "bis_11388_Lux" 10 "bis_10353_Lux" 11 "bis_9412_Lux" 12 "bis_8556_Lux" 13 "bis_7778_Lux" 14 "bis_7071_Lux" 15 "bis_6428_Lux" ;
VAL_ 2527679790 RTM_Fehlerstatus 0 "Init" 1 "Sending_Failure" 2 "UpdateDownload_Failure" 3 "UpdateInstall_Failure" 4 "UpdateRollbacked" 5 "UpdateRollback_Failure" 6 "BackupBattery_Failure" 7 "RTM_Level3_Warning" ;
VAL_ 2527679790 RTM_IstModus 0 "Standby" 1 "RTM_Operational" 2 "RTM_NonOperational" 3 "UpdateAvailable" 4 "UpdateDownloaded" 5 "UpdateInstalled" 6 "WorkshopMode" 7 "TransportMode" ;
VAL_ 2527679790 RTM_OTA_SignalStrength 0 "No_Connection" 1 "Signal_Strength_OK" 2 "Signal_Strength_Bad" 3 "Reconnection" ;
VAL_ 2527679790 RTM_OTA_InstallProcess 0 "Init" ;
VAL_ 2527679790 RTM_OTA_InstallPrecondition 0 "Init" 1 "Check_Success" 2 "Check_Fail_KL15_on" 3 "Check_Fail_Not_Gear_P" ;
VAL_ 2527679790 RTM_OTA_InstallDuration 31 "Init" ;
VAL_ 2527679790 RTM_OTA_Download_Speed 0 "Init" ;
VAL_ 2527679790 RTM_OTA_Download_Size 254 "Init" 255 "Fehler" ;
VAL_ 2527679790 RTM_OTA_Download_Process 254 "Init" 255 "Fehler" ;
VAL_ 1504 MD1_Position 126 "Init" 127 "nicht_normiert" ;
VAL_ 1504 MD1_Lage 0 "Ausstelllage" 1 "Schiebelage" ;
VAL_ 1504 MD3_Lage 0 "Ausstelllage" 1 "Schiebelage" ;
VAL_ 1504 MRollo_Position 126 "Init" 127 "nicht_normiert" ;
VAL_ 1504 MRollo_Lage 0 "Ausstelllage" 1 "Schiebelage" ;
VAL_ 1504 SAD_normiert 0 "inaktiv" 1 "aktiv" ;
VAL_ 1504 SAD_Thermoschutz 0 "inaktiv" 1 "aktiv" ;
VAL_ 1504 SAD_UEKB_aktiv 0 "inaktiv" 1 "aktiv" ;
VAL_ 1504 Rollo_normiert 0 "inaktiv" 1 "aktiv" ;
VAL_ 1504 Rollo_Thermoschutz 0 "inaktiv" 1 "aktiv" ;
VAL_ 1504 Rollo_UEKB_aktiv 0 "inaktiv" 1 "aktiv" ;
VAL_ 1504 SAD_Taster_Deckel_hi 0 "nicht_betaetigt" 1 "man_sl_zu" 2 "auto_sl_zu" 3 "man_sl_auf" 4 "auto_sl_auf" 5 "man_al_auf" 6 "auto_al_auf" 7 "man_al_zu" 8 "auto_al_zu" 14 "fehler_schalter_haengt" 15 "fehler_schalter_unplausibel" ;
VAL_ 1504 SAD_Taster_Deckel_vo 0 "nicht_betaetigt" 1 "man_sl_zu" 2 "auto_sl_zu" 3 "man_sl_auf" 4 "auto_sl_auf" 5 "man_al_auf" 6 "auto_al_auf" 7 "man_al_zu" 8 "auto_al_zu" 14 "fehler_schalter_haengt" 15 "fehler_schalter_unplausibel" ;
VAL_ 1504 SAD_Taster_Rollo_hi 0 "nicht_betaetigt" 1 "man_zu" 2 "auto_zu" 3 "man_auf" 4 "auto_auf" 6 "fehler_schalter_haengt" 7 "fehler_schalter_unplausibel" ;
VAL_ 1504 SAD_Taster_Rollo_vo 0 "nicht_betaetigt" 1 "man_zu" 2 "auto_zu" 3 "man_auf" 4 "auto_auf" 6 "fehler_schalter_haengt" 7 "fehler_schalter_unplausibel" ;
VAL_ 1504 SAD_Anf_ESC_Zuschaltung 0 "inaktiv" 1 "aktiv" ;
VAL_ 1504 SAD_Text 0 "inaktiv" 1 "aktiv" ;
VAL_ 424 SARA_Accel_X_r 0 "nicht_verbaut" 8191 "Fehler" ;
VAL_ 424 SARA_Accel_Y_r 0 "nicht_verbaut" 8191 "Fehler" ;
VAL_ 424 SARA_Omega_Z_r 0 "nicht_verbaut" 8191 "Fehler" ;
VAL_ 424 SARA_CF_Accel_X_r 0 "gueltiger_Wert" 1 "nicht_belegt" 2 "nicht_belegt" 3 "temporaerer_Fehler" 4 "Init" 5 "Sensor_nicht_verbaut_Signal_nicht_berrechnet" 6 "Sensor_nicht_abgeglichen" 7 "Sensor_defekt" ;
VAL_ 424 SARA_CF_Accel_Y_r 0 "gueltiger_Wert" 1 "nicht_belegt" 2 "nicht_belegt" 3 "temporaerer_Fehler" 4 "Init" 5 "Sensor_nicht_verbaut_Signal_nicht_berrechnet" 6 "Sensor_nicht_abgeglichen" 7 "Sensor_defekt" ;
VAL_ 424 SARA_CF_Omega_Z_r 0 "gueltiger_Wert" 1 "nicht_belegt" 2 "nicht_belegt" 3 "temporaerer_Fehler" 4 "Init" 5 "Sensor_nicht_verbaut_Signal_nicht_berrechnet" 6 "Sensor_nicht_abgeglichen" 7 "Sensor_defekt" ;
VAL_ 784 SCU_Warnungen 0 "keine_Anzeige" 1 "DL_Stoerung" 2 "DL_Initialisierung" 3 "DL_Ausfall" ;
VAL_ 784 SCU_Charisma_FahrPr 0 "keine_Funktion" 1 "Programm_1" 2 "Programm_2" 3 "Programm_3" 4 "Programm_4" 5 "Programm_5" 6 "Programm_6" 7 "Programm_7" 8 "Programm_8" 9 "Programm_9" 10 "Programm_10" 11 "Programm_11" 12 "Programm_12" 13 "Programm_13" 14 "Programm_14" 15 "Programm_15" ;
VAL_ 784 SCU_Charisma_Status 0 "Init" 1 "verfuegbar" 2 "nicht_verfuegbar" 3 "asynchron_durch_Fahrerwunsch" ;
VAL_ 784 SCU_IL_Status 0 "SCU_IL_nicht_aktiv" 1 "SCU_IL_Init" 2 "SCU_IL_funktionsbereit" 3 "SCU_IL_Winkelregelung_aktiv" 4 "SCU_IL_Fehler_dauer_sich_Ueber" 5 "nicht_belegt" 6 "SCU_IL_Fehler_temp_sich_Ueber" 7 "SCU_IL_Sync" 8 "SCU_IL_nicht_verfuegbar" ;
VAL_ 1522 KBI_Phototransistor 254 "Init" 255 "Fehler" ;
VAL_ 1522 KBI_Dimmpoti 126 "Nicht verfügbar" 127 "Fehler" ;
VAL_ 1363 SR3_Status_Lehne_Links 0 "nicht_entriegelt" 1 "entriegelt" ;
VAL_ 1363 SR3_Status_Lehne_Rechts 0 "nicht_entriegelt" 1 "entriegelt" ;
